VERSION ""

NS_ :

BS_:

BU_: APIM_CISM FCIMB RACM_RCIM DSP WCM DACMC HUD_ADV TRM_ITRM ACM GWM _delete APIM IPC GENERIC TSTR

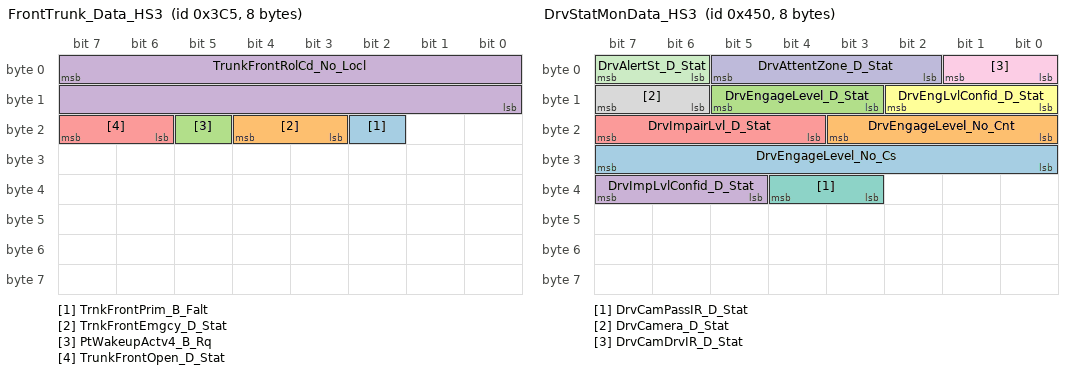
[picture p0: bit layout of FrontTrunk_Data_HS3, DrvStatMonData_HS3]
BO_ 965 FrontTrunk_Data_HS3: 8 GWM
 SG_ TrnkFrontPrim_B_Falt : 18|1@0+ (1,0) [0|1] "SED"  IPC
 SG_ TrnkFrontEmgcy_D_Stat : 20|2@0+ (1,0) [0|0] "SED"  IPC
 SG_ PtWakeupActv4_B_Rq : 21|1@0+ (1,0) [0|1] "SED"  GENERIC
 SG_ TrunkFrontRolCd_No_Locl : 7|16@0+ (1,0) [0|65535] "unitless"  GENERIC
 SG_ TrunkFrontOpen_D_Stat : 23|2@0+ (1,0) [0|3] "SED"  GENERIC

BO_ 1104 DrvStatMonData_HS3: 8 GWM
 SG_ DrvEngageLevel_No_Cs : 31|8@0+ (1,0) [0|255] "Unitless" Vector__XXX
 SG_ DrvEngageLevel_No_Cnt : 19|4@0+ (1,0) [0|15] "Unitless" Vector__XXX
 SG_ DrvEngageLevel_D_Stat : 13|3@0+ (1,0) [0|7] "SED" Vector__XXX
 SG_ DrvImpLvlConfid_D_Stat : 39|3@0+ (1,0) [0|7] "SED" Vector__XXX
 SG_ DrvImpairLvl_D_Stat : 23|4@0+ (1,0) [0|15] "SED" Vector__XXX
 SG_ DrvEngLvlConfid_D_Stat : 10|3@0+ (1,0) [0|7] "SED" Vector__XXX
 SG_ DrvCamPassIR_D_Stat : 36|2@0+ (1,0) [0|3] "SED"  APIM_CISM
 SG_ DrvCamera_D_Stat : 15|2@0+ (1,0) [0|3] "SED"  APIM_CISM
 SG_ DrvCamDrvIR_D_Stat : 1|2@0+ (1,0) [0|3] "SED"  APIM_CISM
 SG_ DrvAttentZone_D_Stat : 5|4@0+ (1,0) [0|15] "SED" Vector__XXX
 SG_ DrvAlertSt_D_Stat : 7|2@0+ (1,0) [0|3] "SED" Vector__XXX

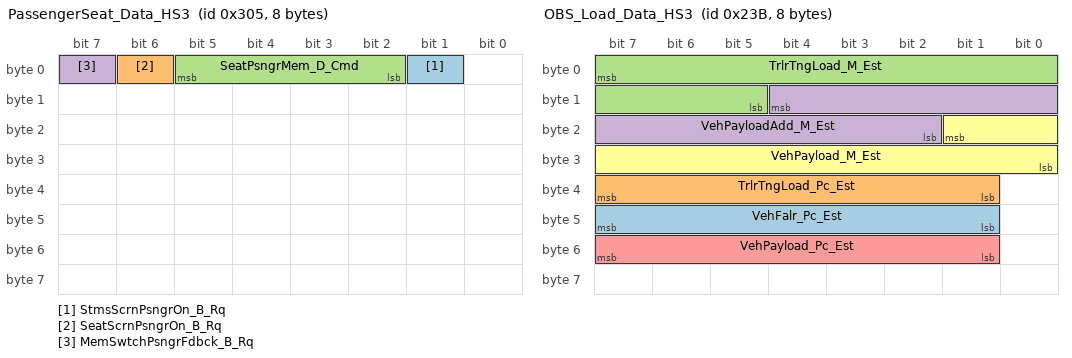
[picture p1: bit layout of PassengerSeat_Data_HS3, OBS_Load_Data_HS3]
BO_ 773 PassengerSeat_Data_HS3: 8 GWM
 SG_ StmsScrnPsngrOn_B_Rq : 1|1@0+ (1,0) [0|1] "SED"  APIM,APIM_CISM
 SG_ SeatScrnPsngrOn_B_Rq : 6|1@0+ (1,0) [0|1] "SED"  GENERIC
 SG_ SeatPsngrMem_D_Cmd : 5|4@0+ (1,0) [0|15] "SED"  GENERIC
 SG_ MemSwtchPsngrFdbck_B_Rq : 7|1@0+ (1,0) [0|1] "SED"  GENERIC

BO_ 303 Body_Info_16_HS3: 8 GWM
 SG_ CanMsg12F_No_Crc : 7|8@0+ (1,0) [0|255] "Unitless"  GENERIC
 SG_ CanMsg12F_No_Cnt : 11|4@0+ (1,0) [0|15] "Unitless"  GENERIC
 SG_ DrStatHood_D2_Actl : 23|3@0+ (1,0) [0|7] "SED"  IPC

BO_ 302 FrontTrunk_Data_2_HS3: 8 GWM
 SG_ CanMsg12E_No_Crc : 7|8@0+ (1,0) [0|255] "Unitless"  GENERIC
 SG_ CanMsg12E_No_Cnt : 11|4@0+ (1,0) [0|15] "Unitless"  GENERIC
 SG_ TrnkFrontRleas_B_Stat : 21|1@0+ (1,0) [0|1] "SED"  GENERIC

BO_ 2612009176 PARSEDPushFcGWM_ECGtoHUD: 8 GWM
 SG_ PARSEDPushFcGWM_ECGtoHUD : 7|29@0+ (1,0) [0|536870911] "unitless"  HUD_ADV

BO_ 571 OBS_Load_Data_HS3: 8 GWM
 SG_ VehFalr_Pc_Est : 47|7@0+ (1,0) [0|125] "percent"  APIM,APIM_CISM
 SG_ TrlrTngLoad_Pc_Est : 39|7@0+ (1,0) [0|125] "percent"  APIM,APIM_CISM
 SG_ TrlrTngLoad_M_Est : 7|11@0+ (10,-10240) [-10240|10210] "kilogram"  APIM,APIM_CISM
 SG_ VehPayloadAdd_M_Est : 12|11@0+ (5,-5115) [-5115|5110] "kilogram"  APIM,APIM_CISM
 SG_ VehPayload_Pc_Est : 55|7@0+ (1,0) [0|125] "percent"  APIM,APIM_CISM
 SG_ VehPayload_M_Est : 17|10@0+ (5,0) [0|5105] "kilogram"  APIM,APIM_CISM

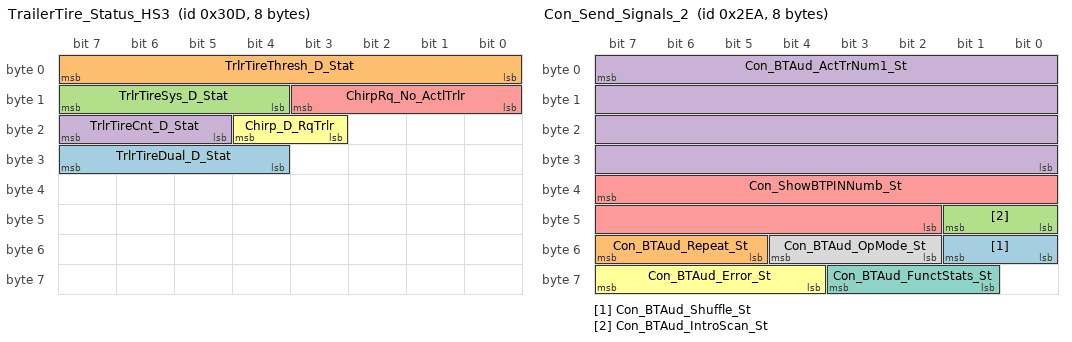
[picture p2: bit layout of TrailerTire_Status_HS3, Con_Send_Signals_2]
BO_ 781 TrailerTire_Status_HS3: 8 GWM
 SG_ TrlrTireDual_D_Stat : 31|4@0+ (1,0) [0|15] "SED"  APIM,IPC,APIM_CISM
 SG_ TrlrTireThresh_D_Stat : 7|8@0+ (1,0) [0|255] "unitless"  APIM,IPC,APIM_CISM
 SG_ TrlrTireSys_D_Stat : 15|4@0+ (1,0) [0|15] "SED"  APIM,IPC,APIM_CISM
 SG_ TrlrTireCnt_D_Stat : 23|3@0+ (1,0) [0|6] "SED"  APIM,IPC,APIM_CISM
 SG_ ChirpRq_No_ActlTrlr : 11|4@0+ (1,0) [0|15] "unitless"  GENERIC
 SG_ Chirp_D_RqTrlr : 20|2@0+ (1,0) [0|3] "SED"  GENERIC

BO_ 1188 OPTIN_MC_WORD_Rx: 8 IPC
 SG_ OPTIN_MC_WORD_Rx : 7|64@0+ (1,0) [0|1.84467440737096E+019] "unitless"  GWM

BO_ 746 Con_Send_Signals_2: 8 ACM
 SG_ Con_BTAud_Shuffle_St : 49|2@0+ (1,0) [0|3] "SED"  IPC
 SG_ Con_BTAud_Repeat_St : 55|3@0+ (1,0) [0|7] "SED"  IPC
 SG_ Con_BTAud_IntroScan_St : 41|2@0+ (1,0) [0|3] "SED"  IPC
 SG_ Con_BTAud_ActTrNum1_St : 7|32@0+ (1,0) [0|4294967295] ""  IPC
 SG_ Con_ShowBTPINNumb_St : 39|14@0+ (1,0) [0|16383] ""  IPC
 SG_ Con_BTAud_Error_St : 63|4@0+ (1,0) [0|15] "SED"  IPC
 SG_ Con_BTAud_FunctStats_St : 59|3@0+ (1,0) [0|7] "SED"  IPC
 SG_ Con_BTAud_OpMode_St : 52|3@0+ (1,0) [0|7] "SED"  IPC

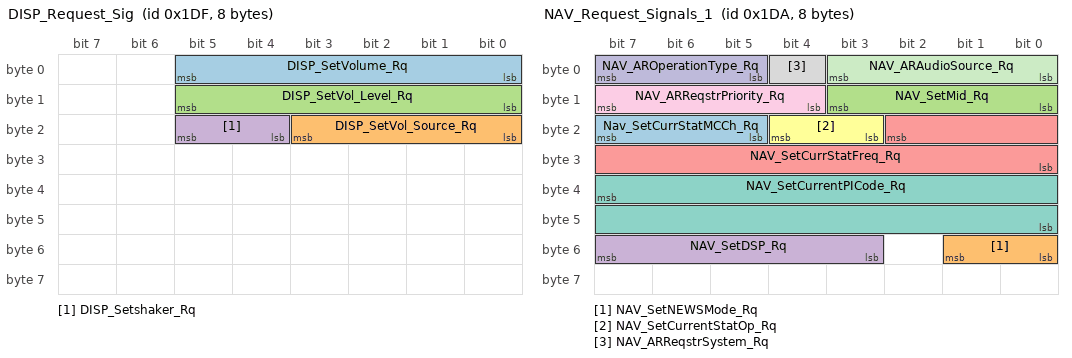
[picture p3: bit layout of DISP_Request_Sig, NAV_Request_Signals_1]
BO_ 479 DISP_Request_Sig: 8 APIM
 SG_ DISP_SetVolume_Rq : 5|6@0+ (1,-30) [-30|33] "steps"  ACM,DSP,GWM
 SG_ DISP_SetVol_Source_Rq : 19|4@0+ (1,0) [0|15] "SED"  IPC,ACM,DSP
 SG_ DISP_SetVol_Level_Rq : 13|6@0+ (1,0) [0|63] "unitless"  ACM,DSP
 SG_ DISP_Setshaker_Rq : 21|2@0+ (1,0) [0|3] "SED"  ACM,DSP

BO_ 474 NAV_Request_Signals_1: 8 APIM
 SG_ Nav_SetCurrStatMCCh_Rq : 23|3@0+ (1,0) [0|7] "SED"  ACM
 SG_ NAV_SetNEWSMode_Rq : 49|2@0+ (1,0) [0|3] "SED"  ACM
 SG_ NAV_SetMid_Rq : 11|4@0+ (1,-7) [-7|8] "SED"  DSP,ACM
 SG_ NAV_SetDSP_Rq : 55|5@0+ (1,0) [0|31] "SED"  ACM
 SG_ NAV_SetCurrStatFreq_Rq : 18|11@0+ (1,0) [0|1557] "unitless"  ACM
 SG_ NAV_SetCurrentStatOp_Rq : 20|2@0+ (1,0) [0|3] "SED"  ACM
 SG_ NAV_SetCurrentPICode_Rq : 39|16@0+ (1,0) [0|65535] "unitless"  ACM
 SG_ NAV_ARReqstrSystem_Rq : 4|1@0+ (1,0) [0|1] "SED"  DSP,ACM
 SG_ NAV_ARReqstrPriority_Rq : 15|4@0+ (1,0) [0|15] "SED"  DSP,ACM
 SG_ NAV_AROperationType_Rq : 7|3@0+ (1,0) [0|7] "SED"  DSP,ACM
 SG_ NAV_ARAudioSource_Rq : 3|4@0+ (1,0) [0|15] "SED"  DSP,ACM

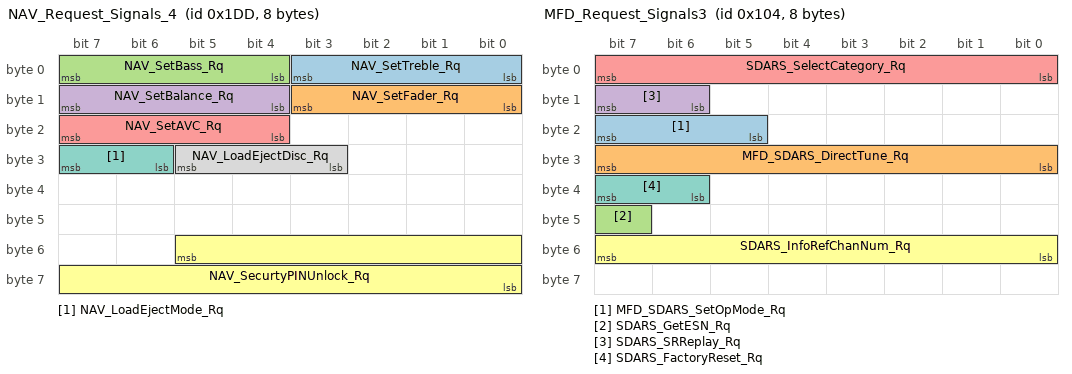
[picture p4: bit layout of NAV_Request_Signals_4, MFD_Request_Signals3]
BO_ 477 NAV_Request_Signals_4: 8 APIM
 SG_ NAV_SetTreble_Rq : 3|4@0+ (1,-7) [-7|8] "SED"  ACM,DSP
 SG_ NAV_SetFader_Rq : 11|4@0+ (1,-7) [-7|8] "SED"  ACM,DSP
 SG_ NAV_SetBass_Rq : 7|4@0+ (1,-7) [-7|8] "SED"  ACM,DSP
 SG_ NAV_SetBalance_Rq : 15|4@0+ (1,-7) [-7|8] "SED"  ACM,DSP
 SG_ NAV_SetAVC_Rq : 23|4@0+ (1,0) [0|15] "SED"  ACM,DSP
 SG_ NAV_SecurtyPINUnlock_Rq : 53|14@0+ (1,0) [0|16383] "unitless"  ACM
 SG_ NAV_LoadEjectMode_Rq : 31|2@0+ (1,0) [0|3] "SED"  ACM
 SG_ NAV_LoadEjectDisc_Rq : 29|3@0+ (1,0) [0|7] "SED"  ACM

BO_ 260 MFD_Request_Signals3: 8 APIM
 SG_ MFD_SDARS_SetOpMode_Rq : 23|3@0+ (1,0) [0|7] "SED"  ACM
 SG_ MFD_SDARS_DirectTune_Rq : 31|8@0+ (1,0) [0|255] "unitless"  ACM
 SG_ SDARS_GetESN_Rq : 47|1@0+ (1,0) [0|1] "SED"  ACM
 SG_ SDARS_SRReplay_Rq : 15|2@0+ (1,0) [0|3] "SED"  ACM
 SG_ SDARS_SelectCategory_Rq : 7|8@0+ (1,0) [0|255] "unitless"  ACM
 SG_ SDARS_InfoRefChanNum_Rq : 55|8@0+ (1,0) [0|255] "unitless"  ACM
 SG_ SDARS_FactoryReset_Rq : 39|2@0+ (1,0) [0|3] "SED"  DSP,ACM

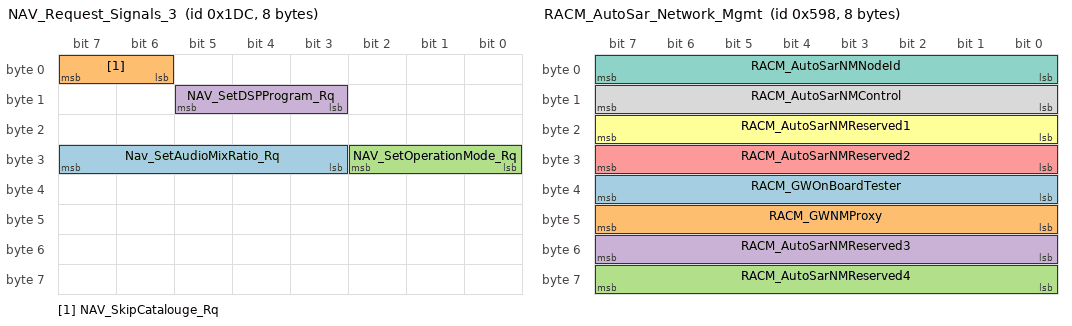
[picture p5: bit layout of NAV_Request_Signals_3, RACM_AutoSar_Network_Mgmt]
BO_ 476 NAV_Request_Signals_3: 8 APIM
 SG_ Nav_SetAudioMixRatio_Rq : 31|5@0+ (1,0) [0|20] "decibel"  ACM
 SG_ NAV_SkipCatalouge_Rq : 7|2@0+ (1,0) [0|3] "SED"  ACM
 SG_ NAV_SetOperationMode_Rq : 26|3@0+ (1,0) [0|7] "SED"  ACM
 SG_ NAV_SetDSPProgram_Rq : 13|3@0+ (1,0) [0|7] "SED"  ACM

BO_ 490 HMI_Request_Signals_2: 8 APIM
 SG_ HMI_SetCompression_Rq : 9|2@0+ (1,0) [0|3] "SED"  ACM
 SG_ HMI_SkipTrack_Rq : 35|2@0+ (1,0) [0|3] "SED"  ACM

BO_ 1001 Personality_SUMA_Data_HS3: 8 GWM
 SG_ AirSuspMsgTxt_D_Rq2 : 36|2@0+ (1,0) [0|3] "SED"  APIM_CISM,APIM,IPC
 SG_ PersIndexSuma_D_Actl : 39|3@0+ (1,0) [0|7] "SED"  APIM_CISM,APIM,IPC
 SG_ FeatNoSumaActl : 23|16@0+ (1,0) [0|65535] "Number"  APIM_CISM,APIM,IPC
 SG_ FeatConfigSumaActl : 7|16@0+ (1,0) [0|65535] "Undefined"  APIM_CISM,APIM,IPC

BO_ 1916 TesterPhysicalResRACM: 8 RACM_RCIM
 SG_ TesterPhysicalResRACM : 7|64@0+ (1,0) [0|1.84467E+019] "unitless"  TSTR

BO_ 1908 TesterPhysicalReqRACM: 8 TSTR
 SG_ TesterPhysicalReqRACM : 7|64@0+ (1,0) [0|1.84467E+019] "unitless"  RACM_RCIM

BO_ 1432 RACM_AutoSar_Network_Mgmt: 8 RACM_RCIM
 SG_ RACM_GWOnBoardTester : 39|8@0+ (1,0) [0|255] "unitless"  HUD_ADV,GWM
 SG_ RACM_GWNMProxy : 47|8@0+ (1,0) [0|255] "unitless"  HUD_ADV,GWM
 SG_ RACM_AutoSarNMReserved4 : 63|8@0+ (1,0) [0|255] "unitless"  HUD_ADV,GWM
 SG_ RACM_AutoSarNMReserved3 : 55|8@0+ (1,0) [0|255] "unitless"  HUD_ADV,GWM
 SG_ RACM_AutoSarNMReserved2 : 31|8@0+ (1,0) [0|255] "unitless"  HUD_ADV,GWM
 SG_ RACM_AutoSarNMReserved1 : 23|8@0+ (1,0) [0|255] "unitless"  HUD_ADV,GWM
 SG_ RACM_AutoSarNMNodeId : 7|8@0+ (1,0) [0|255] "unitless"  HUD_ADV,GWM
 SG_ RACM_AutoSarNMControl : 15|8@0+ (1,0) [0|255] "unitless"  HUD_ADV,GWM

BO_ 1923 TesterPhysicalReqDSP: 8 TSTR
 SG_ TesterPhysicalReqDSP : 7|64@0+ (1,0) [0|1.84467E+019] "unitless"  DSP

BO_ 1931 TesterPhysicalResDSP: 8 DSP
 SG_ TesterPhysicalResDSP : 7|64@0+ (1,0) [0|1.84467E+019] "unitless"  TSTR

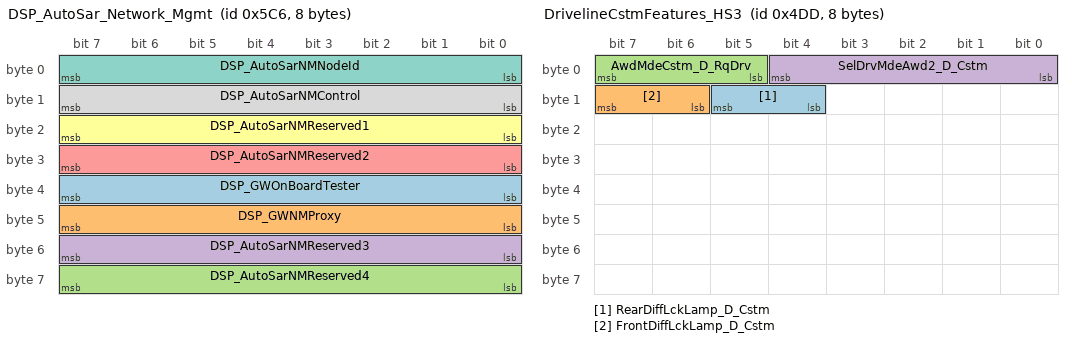
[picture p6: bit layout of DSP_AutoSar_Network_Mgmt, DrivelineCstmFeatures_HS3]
BO_ 1478 DSP_AutoSar_Network_Mgmt: 8 DSP
 SG_ DSP_GWOnBoardTester : 39|8@0+ (1,0) [0|255] "unitless"  HUD_ADV
 SG_ DSP_GWNMProxy : 47|8@0+ (1,0) [0|255] "unitless"  HUD_ADV
 SG_ DSP_AutoSarNMReserved4 : 63|8@0+ (1,0) [0|255] "unitless"  HUD_ADV
 SG_ DSP_AutoSarNMReserved3 : 55|8@0+ (1,0) [0|255] "unitless"  HUD_ADV
 SG_ DSP_AutoSarNMReserved2 : 31|8@0+ (1,0) [0|255] "unitless"  HUD_ADV
 SG_ DSP_AutoSarNMReserved1 : 23|8@0+ (1,0) [0|255] "unitless"  HUD_ADV
 SG_ DSP_AutoSarNMNodeId : 7|8@0+ (1,0) [0|255] "unitless"  HUD_ADV
 SG_ DSP_AutoSarNMControl : 15|8@0+ (1,0) [0|255] "unitless"  HUD_ADV

BO_ 1245 DrivelineCstmFeatures_HS3: 8 GWM
 SG_ RearDiffLckLamp_D_Cstm : 13|2@0+ (1,0) [0|3] "SED"  IPC
 SG_ FrontDiffLckLamp_D_Cstm : 15|2@0+ (1,0) [0|3] "SED"  IPC
 SG_ AwdMdeCstm_D_RqDrv : 7|3@0+ (1,0) [0|7] "SED"  IPC
 SG_ SelDrvMdeAwd2_D_Cstm : 4|5@0+ (1,0) [0|31] "SED"  GENERIC

BO_ 1242 PowertrainCstmData_HS3: 8 GWM
 SG_ EngExhMdeQuietCstm_D_Rq : 7|3@0+ (1,0) [0|7] "SED"  IPC
 SG_ StopStrtCstm_D_Rq : 15|2@0+ (1,0) [0|3] "SED"  IPC
 SG_ SelDrvMdeCstmPt_D_Rq : 4|5@0+ (1,0) [0|31] "SED"  GENERIC

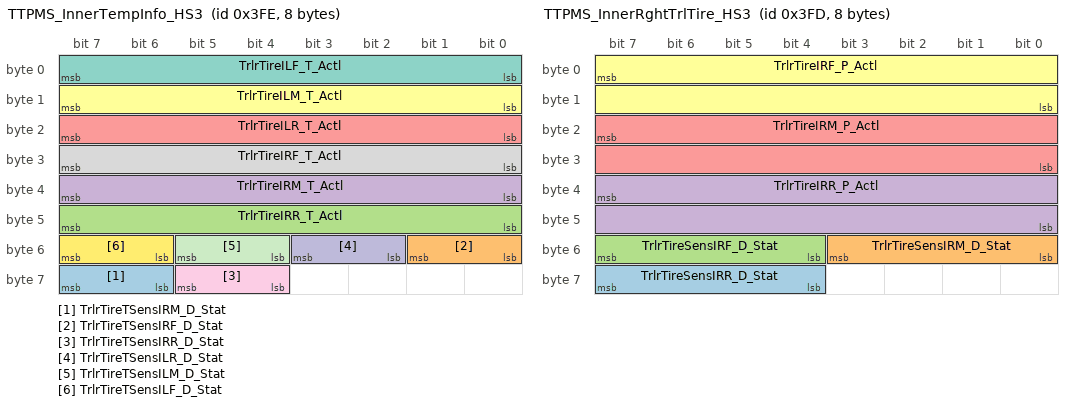
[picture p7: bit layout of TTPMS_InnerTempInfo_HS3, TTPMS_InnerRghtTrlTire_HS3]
BO_ 1022 TTPMS_InnerTempInfo_HS3: 8 GWM
 SG_ TrlrTireTSensIRM_D_Stat : 63|2@0+ (1,0) [0|3] "SED"  APIM,IPC,APIM_CISM
 SG_ TrlrTireTSensIRF_D_Stat : 49|2@0+ (1,0) [0|3] "SED"  APIM,IPC,APIM_CISM
 SG_ TrlrTireIRR_T_Actl : 47|8@0+ (1,-60) [-60|193] "degC"  APIM,IPC,APIM_CISM
 SG_ TrlrTireIRM_T_Actl : 39|8@0+ (1,-60) [-60|193] "degC"  APIM,IPC,APIM_CISM
 SG_ TrlrTireILR_T_Actl : 23|8@0+ (1,-60) [-60|193] "degC"  APIM,IPC,APIM_CISM
 SG_ TrlrTireILM_T_Actl : 15|8@0+ (1,-60) [-60|193] "degC"  APIM,IPC,APIM_CISM
 SG_ TrlrTireILF_T_Actl : 7|8@0+ (1,-60) [-60|193] "degC"  APIM,IPC,APIM_CISM
 SG_ TrlrTireIRF_T_Actl : 31|8@0+ (1,-60) [-60|193] "degC"  APIM,IPC,APIM_CISM
 SG_ TrlrTireTSensIRR_D_Stat : 61|2@0+ (1,0) [0|3] "SED"  APIM,IPC,APIM_CISM
 SG_ TrlrTireTSensILR_D_Stat : 51|2@0+ (1,0) [0|3] "SED"  APIM,IPC,APIM_CISM
 SG_ TrlrTireTSensILM_D_Stat : 53|2@0+ (1,0) [0|3] "SED"  APIM,IPC,APIM_CISM
 SG_ TrlrTireTSensILF_D_Stat : 55|2@0+ (1,0) [0|3] "SED"  APIM,IPC,APIM_CISM

BO_ 1021 TTPMS_InnerRghtTrlTire_HS3: 8 GWM
 SG_ TrlrTireSensIRR_D_Stat : 63|4@0+ (1,0) [0|15] "SED"  APIM,IPC,APIM_CISM
 SG_ TrlrTireSensIRM_D_Stat : 51|4@0+ (1,0) [0|15] "SED"  APIM,IPC,APIM_CISM
 SG_ TrlrTireSensIRF_D_Stat : 55|4@0+ (1,0) [0|15] "SED"  APIM_CISM
 SG_ TrlrTireIRR_P_Actl : 39|16@0+ (1,0) [0|65533] "kilopascal"  APIM,IPC,APIM_CISM
 SG_ TrlrTireIRM_P_Actl : 23|16@0+ (1,0) [0|65533] "kilopascal"  APIM,IPC,APIM_CISM
 SG_ TrlrTireIRF_P_Actl : 7|16@0+ (1,0) [0|65533] "kilopascal"  APIM,IPC,APIM_CISM

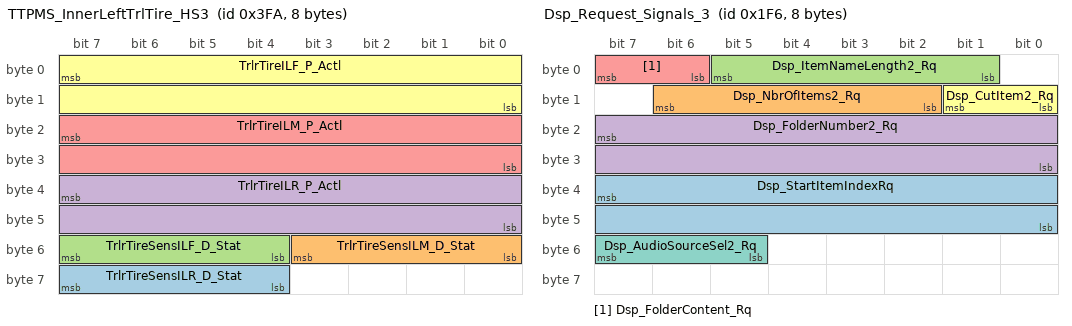
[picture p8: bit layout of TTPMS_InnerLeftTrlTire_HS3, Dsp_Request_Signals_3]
BO_ 1018 TTPMS_InnerLeftTrlTire_HS3: 8 GWM
 SG_ TrlrTireSensILR_D_Stat : 63|4@0+ (1,0) [0|15] "SED"  APIM_CISM,APIM,IPC
 SG_ TrlrTireSensILM_D_Stat : 51|4@0+ (1,0) [0|15] "SED"  APIM,IPC,APIM_CISM
 SG_ TrlrTireSensILF_D_Stat : 55|4@0+ (1,0) [0|15] "SED"  APIM,IPC,APIM_CISM
 SG_ TrlrTireILR_P_Actl : 39|16@0+ (1,0) [0|65533] "kilopascal"  APIM,IPC,APIM_CISM
 SG_ TrlrTireILM_P_Actl : 23|16@0+ (1,0) [0|65533] "kilopascal"  APIM,IPC,APIM_CISM
 SG_ TrlrTireILF_P_Actl : 7|16@0+ (1,0) [0|65533] "kilopascal"  APIM,IPC,APIM_CISM

BO_ 502 Dsp_Request_Signals_3: 8 APIM
 SG_ Dsp_StartItemIndexRq : 39|16@0+ (1,0) [0|65535] "unitless"  ACM
 SG_ Dsp_NbrOfItems2_Rq : 14|5@0+ (1,0) [0|20] "SED"  ACM
 SG_ Dsp_ItemNameLength2_Rq : 5|5@0+ (1,0) [0|20] "SED"  ACM
 SG_ Dsp_FolderNumber2_Rq : 23|16@0+ (1,0) [0|65535] "unitless"  ACM
 SG_ Dsp_FolderContent_Rq : 7|2@0+ (1,0) [0|3] "SED"  ACM
 SG_ Dsp_CutItem2_Rq : 9|2@0+ (1,0) [0|3] "SED"  ACM
 SG_ Dsp_AudioSourceSel2_Rq : 55|3@0+ (1,0) [0|7] "SED"  ACM

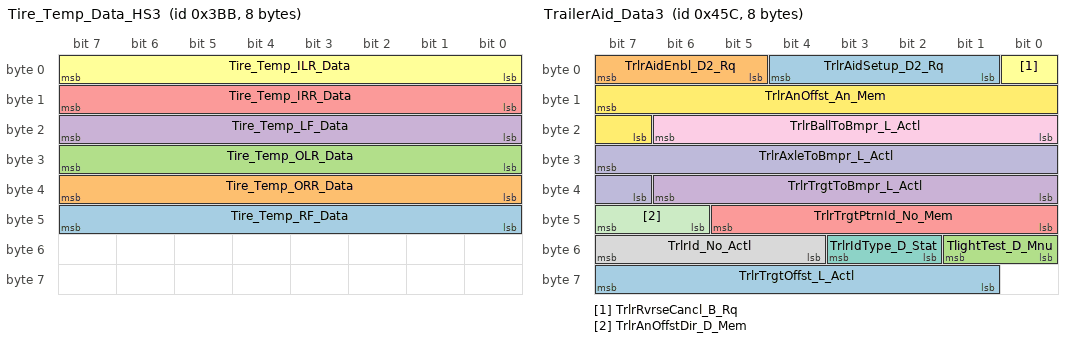
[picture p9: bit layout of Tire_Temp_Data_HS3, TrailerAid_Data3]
BO_ 955 Tire_Temp_Data_HS3: 8 GWM
 SG_ Tire_Temp_RF_Data : 47|8@0+ (1,-60) [-60|193] "degC"  IPC,APIM,APIM_CISM
 SG_ Tire_Temp_ORR_Data : 39|8@0+ (1,-60) [-60|193] "degC"  IPC,APIM,APIM_CISM
 SG_ Tire_Temp_OLR_Data : 31|8@0+ (1,-60) [-60|193] "degC"  IPC,APIM,APIM_CISM
 SG_ Tire_Temp_LF_Data : 23|8@0+ (1,-60) [-60|193] "degC"  IPC,APIM,APIM_CISM
 SG_ Tire_Temp_IRR_Data : 15|8@0+ (1,-60) [-60|193] "degC"  IPC,APIM,APIM_CISM
 SG_ Tire_Temp_ILR_Data : 7|8@0+ (1,-60) [-60|193] "degC"  IPC,APIM,APIM_CISM

BO_ 1116 TrailerAid_Data3: 8 APIM
 SG_ TrlrAidSetup_D2_Rq : 4|4@0+ (1,0) [0|15] "SED"  GWM
 SG_ TrlrAidEnbl_D2_Rq : 7|3@0+ (1,0) [0|7] "SED"  GWM
 SG_ TlightTest_D_Mnu : 49|2@0+ (1,0) [0|3] "SED"  GWM
 SG_ TrlrTrgtToBmpr_L_Actl : 38|7@0+ (0.0127,0) [0|1.6129] "meter"  GWM
 SG_ TrlrTrgtPtrnId_No_Mem : 45|6@0+ (1,0) [0|63] "unitless"  GWM
 SG_ TrlrRvrseCancl_B_Rq : 0|1@0+ (1,0) [0|1] "SED"  GWM
 SG_ TrlrIdType_D_Stat : 51|2@0+ (1,0) [0|3] "SED"  GWM
 SG_ TrlrId_No_Actl : 55|4@0+ (1,0) [0|15] "unitless"  GWM
 SG_ TrlrBallToBmpr_L_Actl : 22|7@0+ (0.0127,0) [0|1.6129] "meter"  GWM
 SG_ TrlrAxleToBmpr_L_Actl : 31|9@0+ (0.0254,0) [0|12.9794] "meter"  GWM
 SG_ TrlrAnOffstDir_D_Mem : 47|2@0+ (1,0) [0|3] "SED"  GWM
 SG_ TrlrAnOffst_An_Mem : 15|9@0+ (0.1,0) [0|51.1] "degrees"  GWM
 SG_ TrlrTrgtOffst_L_Actl : 63|7@0+ (0.0127,0) [0|1.6129] "meter"  GWM

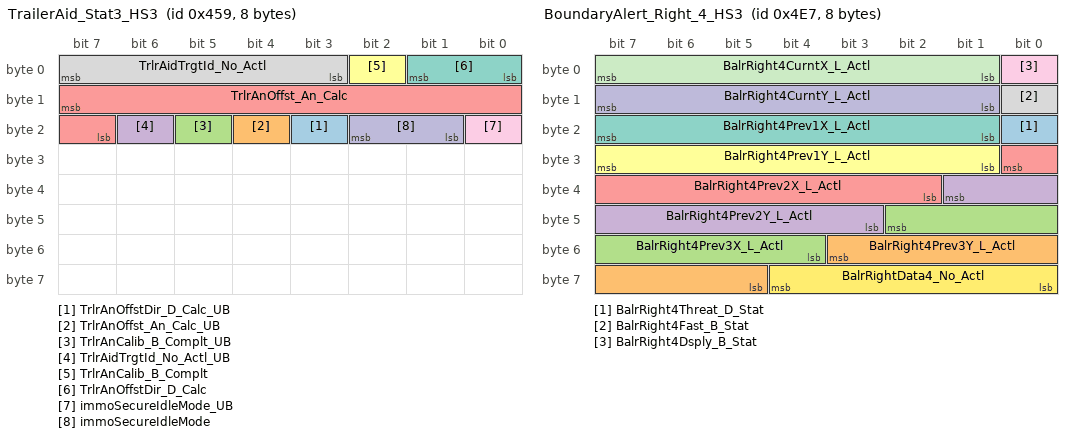
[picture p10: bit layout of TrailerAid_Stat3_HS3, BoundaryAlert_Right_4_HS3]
BO_ 1113 TrailerAid_Stat3_HS3: 8 GWM
 SG_ TrlrAnOffstDir_D_Calc_UB : 19|1@0+ (1,0) [0|1] "SED"  APIM_CISM,IPC,APIM
 SG_ TrlrAnOffst_An_Calc_UB : 20|1@0+ (1,0) [0|1] "SED"  APIM_CISM,IPC,APIM
 SG_ TrlrAnCalib_B_Complt_UB : 21|1@0+ (1,0) [0|1] "SED"  APIM_CISM,IPC,APIM
 SG_ TrlrAidTrgtId_No_Actl_UB : 22|1@0+ (1,0) [0|1] "SED"  APIM_CISM,IPC,APIM
 SG_ TrlrAnOffst_An_Calc : 15|9@0+ (0.1,0) [0|51.1] "degrees"  APIM_CISM,IPC,APIM
 SG_ TrlrAnCalib_B_Complt : 2|1@0+ (1,0) [0|1] "SED"  APIM_CISM,IPC,APIM
 SG_ TrlrAnOffstDir_D_Calc : 1|2@0+ (1,0) [0|3] "SED"  APIM_CISM,IPC,APIM
 SG_ TrlrAidTrgtId_No_Actl : 7|5@0+ (1,0) [0|31] "unitless"  APIM_CISM,IPC,APIM
 SG_ immoSecureIdleMode_UB : 16|1@0+ (1,0) [0|1] "SED"  APIM_CISM,APIM
 SG_ immoSecureIdleMode : 18|2@0+ (1,0) [0|3] "SED"  APIM_CISM,APIM

BO_ 1255 BoundaryAlert_Right_4_HS3: 8 GWM
 SG_ BalrRight4Threat_D_Stat : 16|1@0+ (1,0) [0|1] "SED"  IPC
 SG_ BalrRight4Prev3Y_L_Actl : 51|7@0+ (0.5,-32) [-32|31.5] "meter"  IPC
 SG_ BalrRight4Prev3X_L_Actl : 42|7@0+ (0.5,-32) [-32|31.5] "meter"  IPC
 SG_ BalrRight4Prev2Y_L_Actl : 33|7@0+ (0.5,-32) [-32|31.5] "meter"  IPC
 SG_ BalrRight4Prev2X_L_Actl : 24|7@0+ (0.5,-32) [-32|31.5] "meter"  IPC
 SG_ BalrRight4Prev1Y_L_Actl : 31|7@0+ (0.5,-32) [-32|31.5] "meter"  IPC
 SG_ BalrRight4Prev1X_L_Actl : 23|7@0+ (0.5,-32) [-32|31.5] "meter"  IPC
 SG_ BalrRight4Fast_B_Stat : 8|1@0+ (1,0) [0|1] "SED"  IPC
 SG_ BalrRight4Dsply_B_Stat : 0|1@0+ (1,0) [0|1] "SED"  IPC
 SG_ BalrRight4CurntY_L_Actl : 15|7@0+ (0.5,-32) [-32|31.5] "meter"  IPC
 SG_ BalrRight4CurntX_L_Actl : 7|7@0+ (0.5,-32) [-32|31.5] "meter"  IPC
 SG_ BalrRightData4_No_Actl : 60|5@0+ (1,0) [0|31] "unitless" Vector__XXX

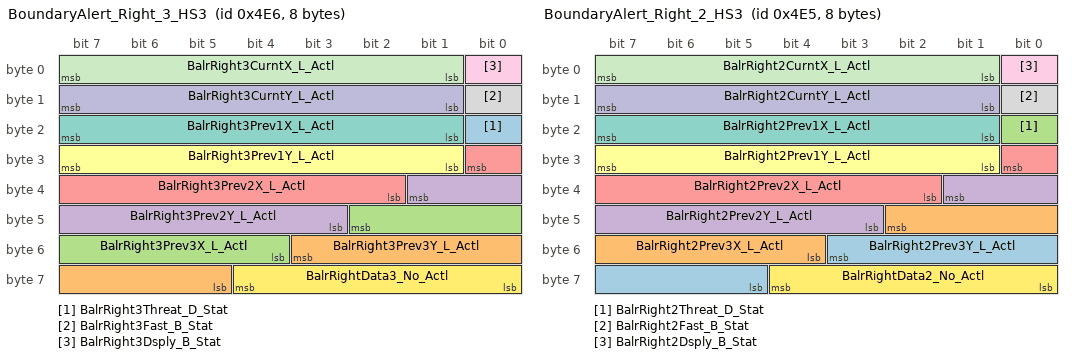
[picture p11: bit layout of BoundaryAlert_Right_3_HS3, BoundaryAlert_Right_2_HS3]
BO_ 1254 BoundaryAlert_Right_3_HS3: 8 GWM
 SG_ BalrRight3Threat_D_Stat : 16|1@0+ (1,0) [0|1] "SED"  IPC
 SG_ BalrRight3Prev3Y_L_Actl : 51|7@0+ (0.5,-32) [-32|31.5] "meter"  IPC
 SG_ BalrRight3Prev3X_L_Actl : 42|7@0+ (0.5,-32) [-32|31.5] "meter"  IPC
 SG_ BalrRight3Prev2Y_L_Actl : 33|7@0+ (0.5,-32) [-32|31.5] "meter"  IPC
 SG_ BalrRight3Prev2X_L_Actl : 24|7@0+ (0.5,-32) [-32|31.5] "meter"  IPC
 SG_ BalrRight3Prev1Y_L_Actl : 31|7@0+ (0.5,-32) [-32|31.5] "meter"  IPC
 SG_ BalrRight3Prev1X_L_Actl : 23|7@0+ (0.5,-32) [-32|31.5] "meter"  IPC
 SG_ BalrRight3Fast_B_Stat : 8|1@0+ (1,0) [0|1] "SED"  IPC
 SG_ BalrRight3Dsply_B_Stat : 0|1@0+ (1,0) [0|1] "SED"  IPC
 SG_ BalrRight3CurntY_L_Actl : 15|7@0+ (0.5,-32) [-32|31.5] "meter"  IPC
 SG_ BalrRight3CurntX_L_Actl : 7|7@0+ (0.5,-32) [-32|31.5] "meter"  IPC
 SG_ BalrRightData3_No_Actl : 60|5@0+ (1,0) [0|31] "unitless" Vector__XXX

BO_ 1253 BoundaryAlert_Right_2_HS3: 8 GWM
 SG_ BalrRight2Prev3Y_L_Actl : 51|7@0+ (0.5,-32) [-32|31.5] "meter"  IPC
 SG_ BalrRight2Prev3X_L_Actl : 42|7@0+ (0.5,-32) [-32|31.5] "meter"  IPC
 SG_ BalrRight2Threat_D_Stat : 16|1@0+ (1,0) [0|1] "SED"  IPC
 SG_ BalrRight2Prev2Y_L_Actl : 33|7@0+ (0.5,-32) [-32|31.5] "meter"  IPC
 SG_ BalrRight2Prev2X_L_Actl : 24|7@0+ (0.5,-32) [-32|31.5] "meter"  IPC
 SG_ BalrRight2Prev1Y_L_Actl : 31|7@0+ (0.5,-32) [-32|31.5] "meter"  IPC
 SG_ BalrRight2Prev1X_L_Actl : 23|7@0+ (0.5,-32) [-32|31.5] "meter"  IPC
 SG_ BalrRight2Fast_B_Stat : 8|1@0+ (1,0) [0|1] "SED"  IPC
 SG_ BalrRight2Dsply_B_Stat : 0|1@0+ (1,0) [0|1] "SED"  IPC
 SG_ BalrRight2CurntY_L_Actl : 15|7@0+ (0.5,-32) [-32|31.5] "meter"  IPC
 SG_ BalrRight2CurntX_L_Actl : 7|7@0+ (0.5,-32) [-32|31.5] "meter"  IPC
 SG_ BalrRightData2_No_Actl : 60|5@0+ (1,0) [0|31] "unitless" Vector__XXX

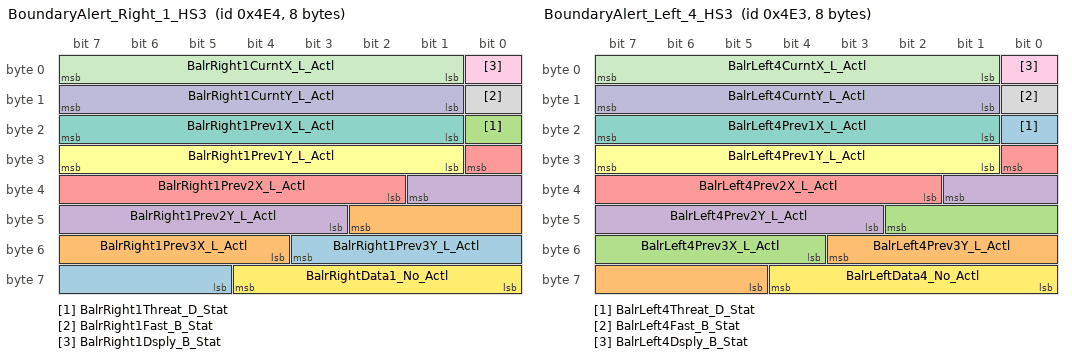
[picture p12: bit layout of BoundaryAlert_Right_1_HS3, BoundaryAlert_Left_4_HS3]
BO_ 1252 BoundaryAlert_Right_1_HS3: 8 GWM
 SG_ BalrRight1Prev3Y_L_Actl : 51|7@0+ (0.5,-32) [-32|31.5] "meter"  IPC
 SG_ BalrRight1Prev3X_L_Actl : 42|7@0+ (0.5,-32) [-32|31.5] "meter"  IPC
 SG_ BalrRight1Threat_D_Stat : 16|1@0+ (1,0) [0|1] "SED"  IPC
 SG_ BalrRight1Prev2Y_L_Actl : 33|7@0+ (0.5,-32) [-32|31.5] "meter"  IPC
 SG_ BalrRight1Prev2X_L_Actl : 24|7@0+ (0.5,-32) [-32|31.5] "meter"  IPC
 SG_ BalrRight1Prev1Y_L_Actl : 31|7@0+ (0.5,-32) [-32|31.5] "meter"  IPC
 SG_ BalrRight1Prev1X_L_Actl : 23|7@0+ (0.5,-32) [-32|31.5] "meter"  IPC
 SG_ BalrRight1Fast_B_Stat : 8|1@0+ (1,0) [0|1] "SED"  IPC
 SG_ BalrRight1Dsply_B_Stat : 0|1@0+ (1,0) [0|1] "SED"  IPC
 SG_ BalrRight1CurntY_L_Actl : 15|7@0+ (0.5,-32) [-32|31.5] "meter"  IPC
 SG_ BalrRight1CurntX_L_Actl : 7|7@0+ (0.5,-32) [-32|31.5] "meter"  IPC
 SG_ BalrRightData1_No_Actl : 60|5@0+ (1,0) [0|31] "unitless" Vector__XXX

BO_ 1251 BoundaryAlert_Left_4_HS3: 8 GWM
 SG_ BalrLeft4Threat_D_Stat : 16|1@0+ (1,0) [0|1] "SED"  IPC
 SG_ BalrLeft4Prev3Y_L_Actl : 51|7@0+ (0.5,-32) [-32|31.5] "meter"  IPC
 SG_ BalrLeft4Prev3X_L_Actl : 42|7@0+ (0.5,-32) [-32|31.5] "meter"  IPC
 SG_ BalrLeft4Prev2Y_L_Actl : 33|7@0+ (0.5,-32) [-32|31.5] "meter"  IPC
 SG_ BalrLeft4Prev2X_L_Actl : 24|7@0+ (0.5,-32) [-32|31.5] "meter"  IPC
 SG_ BalrLeft4Prev1Y_L_Actl : 31|7@0+ (0.5,-32) [-32|31.5] "meter"  IPC
 SG_ BalrLeft4Prev1X_L_Actl : 23|7@0+ (0.5,-32) [-32|31.5] "meter"  IPC
 SG_ BalrLeft4Fast_B_Stat : 8|1@0+ (1,0) [0|1] "SED"  IPC
 SG_ BalrLeft4Dsply_B_Stat : 0|1@0+ (1,0) [0|1] "SED"  IPC
 SG_ BalrLeft4CurntY_L_Actl : 15|7@0+ (0.5,-32) [-32|31.5] "meter"  IPC
 SG_ BalrLeft4CurntX_L_Actl : 7|7@0+ (0.5,-32) [-32|31.5] "meter"  IPC
 SG_ BalrLeftData4_No_Actl : 60|5@0+ (1,0) [0|31] "unitless" Vector__XXX

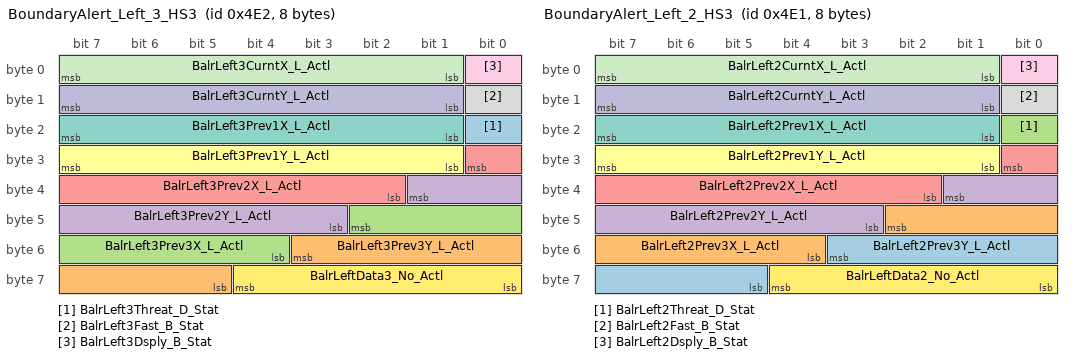
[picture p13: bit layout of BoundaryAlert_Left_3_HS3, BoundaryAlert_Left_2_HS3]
BO_ 1250 BoundaryAlert_Left_3_HS3: 8 GWM
 SG_ BalrLeft3Threat_D_Stat : 16|1@0+ (1,0) [0|1] "SED"  IPC
 SG_ BalrLeft3Prev3Y_L_Actl : 51|7@0+ (0.5,-32) [-32|31.5] "meter"  IPC
 SG_ BalrLeft3Prev3X_L_Actl : 42|7@0+ (0.5,-32) [-32|31.5] "meter"  IPC
 SG_ BalrLeft3Prev2Y_L_Actl : 33|7@0+ (0.5,-32) [-32|31.5] "meter"  IPC
 SG_ BalrLeft3Prev2X_L_Actl : 24|7@0+ (0.5,-32) [-32|31.5] "meter"  IPC
 SG_ BalrLeft3Prev1Y_L_Actl : 31|7@0+ (0.5,-32) [-32|31.5] "meter"  IPC
 SG_ BalrLeft3Prev1X_L_Actl : 23|7@0+ (0.5,-32) [-32|31.5] "meter"  IPC
 SG_ BalrLeft3Fast_B_Stat : 8|1@0+ (1,0) [0|1] "SED"  IPC
 SG_ BalrLeft3Dsply_B_Stat : 0|1@0+ (1,0) [0|1] "SED"  IPC
 SG_ BalrLeft3CurntY_L_Actl : 15|7@0+ (0.5,-32) [-32|31.5] "meter"  IPC
 SG_ BalrLeft3CurntX_L_Actl : 7|7@0+ (0.5,-32) [-32|31.5] "meter"  IPC
 SG_ BalrLeftData3_No_Actl : 60|5@0+ (1,0) [0|31] "unitless" Vector__XXX

BO_ 1249 BoundaryAlert_Left_2_HS3: 8 GWM
 SG_ BalrLeft2Prev3Y_L_Actl : 51|7@0+ (0.5,-32) [-32|31.5] "meter"  IPC
 SG_ BalrLeft2Prev3X_L_Actl : 42|7@0+ (0.5,-32) [-32|31.5] "meter"  IPC
 SG_ BalrLeft2Threat_D_Stat : 16|1@0+ (1,0) [0|1] "SED"  IPC
 SG_ BalrLeft2Prev2Y_L_Actl : 33|7@0+ (0.5,-32) [-32|31.5] "meter"  IPC
 SG_ BalrLeft2Prev2X_L_Actl : 24|7@0+ (0.5,-32) [-32|31.5] "meter"  IPC
 SG_ BalrLeft2Prev1Y_L_Actl : 31|7@0+ (0.5,-32) [-32|31.5] "meter"  IPC
 SG_ BalrLeft2Prev1X_L_Actl : 23|7@0+ (0.5,-32) [-32|31.5] "meter"  IPC
 SG_ BalrLeft2Fast_B_Stat : 8|1@0+ (1,0) [0|1] "SED"  IPC
 SG_ BalrLeft2Dsply_B_Stat : 0|1@0+ (1,0) [0|1] "SED"  IPC
 SG_ BalrLeft2CurntY_L_Actl : 15|7@0+ (0.5,-32) [-32|31.5] "meter"  IPC
 SG_ BalrLeft2CurntX_L_Actl : 7|7@0+ (0.5,-32) [-32|31.5] "meter"  IPC
 SG_ BalrLeftData2_No_Actl : 60|5@0+ (1,0) [0|31] "unitless" Vector__XXX

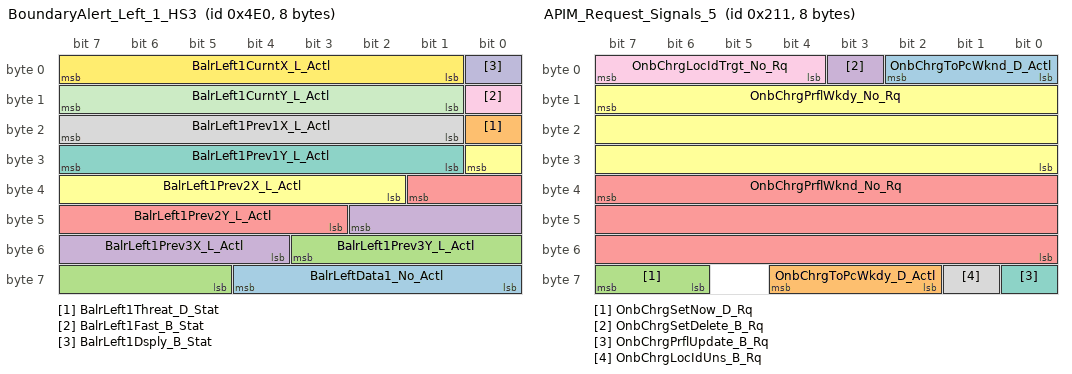
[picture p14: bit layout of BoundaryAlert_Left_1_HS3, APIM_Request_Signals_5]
BO_ 1248 BoundaryAlert_Left_1_HS3: 8 GWM
 SG_ BalrLeftData1_No_Actl : 60|5@0+ (1,0) [0|31] "unitless" Vector__XXX
 SG_ BalrLeft1Threat_D_Stat : 16|1@0+ (1,0) [0|1] "SED"  IPC
 SG_ BalrLeft1Prev3Y_L_Actl : 51|7@0+ (0.5,-32) [-32|31.5] "meter"  IPC
 SG_ BalrLeft1Prev3X_L_Actl : 42|7@0+ (0.5,-32) [-32|31.5] "meter"  IPC
 SG_ BalrLeft1Prev2Y_L_Actl : 33|7@0+ (0.5,-32) [-32|31.5] "meter"  IPC
 SG_ BalrLeft1Prev2X_L_Actl : 24|7@0+ (0.5,-32) [-32|31.5] "meter"  IPC
 SG_ BalrLeft1Prev1Y_L_Actl : 31|7@0+ (0.5,-32) [-32|31.5] "meter"  IPC
 SG_ BalrLeft1Prev1X_L_Actl : 23|7@0+ (0.5,-32) [-32|31.5] "meter"  IPC
 SG_ BalrLeft1Fast_B_Stat : 8|1@0+ (1,0) [0|1] "SED"  IPC
 SG_ BalrLeft1Dsply_B_Stat : 0|1@0+ (1,0) [0|1] "SED"  IPC
 SG_ BalrLeft1CurntY_L_Actl : 15|7@0+ (0.5,-32) [-32|31.5] "meter"  IPC
 SG_ BalrLeft1CurntX_L_Actl : 7|7@0+ (0.5,-32) [-32|31.5] "meter"  IPC

BO_ 1256 GWM_Send_Signals_15_HS3: 8 GWM
 SG_ BalrMdeRight_D_Stat_UB : 21|1@0+ (1,0) [0|1] "SED"  IPC
 SG_ BalrMdeSelRight_B_Stat_UB : 17|1@0+ (1,0) [0|1] "SED"  IPC
 SG_ BalrRight_D_Stat_UB : 16|1@0+ (1,0) [0|1] "SED"  IPC
 SG_ BalrLckRight_B_Stat_UB : 14|1@0+ (1,0) [0|1] "SED"  IPC
 SG_ BalrChimeRight_D_Rq_UB : 2|1@0+ (1,0) [0|1] "SED"  IPC
 SG_ BalrSnsRight_D_Falt_UB : 24|1@0+ (1,0) [0|1] "SED"  IPC
 SG_ BalrWndwRight_B_Stat_UB : 36|1@0+ (1,0) [0|1] "SED"  IPC
 SG_ BalrLckRight_B_Stat : 15|1@0+ (1,0) [0|1] "SED"  IPC
 SG_ BalrWndwRight_B_Stat : 37|1@0+ (1,0) [0|1] "SED"  IPC
 SG_ BalrMdeSelRight_B_Stat : 18|1@0+ (1,0) [0|1] "SED"  IPC
 SG_ BalrSnsRight_D_Falt : 26|2@0+ (1,0) [0|3] "SED"  IPC
 SG_ BalrChimeRight_D_Rq : 4|2@0+ (1,0) [0|3] "SED"  IPC
 SG_ BalrMdeRight_D_Stat : 23|2@0+ (1,0) [0|3] "SED"  IPC
 SG_ BalrRight_D_Stat : 31|2@0+ (1,0) [0|3] "SED"  IPC
 SG_ BalrWndwLeft_B_Stat_UB : 38|1@0+ (1,0) [0|1] "SED"  IPC
 SG_ BalrSnsLeft_D_Falt_UB : 27|1@0+ (1,0) [0|1] "SED"  IPC
 SG_ BalrMdeSelLeft_B_Stat_UB : 19|1@0+ (1,0) [0|1] "SED"  IPC
 SG_ BalrMdeLeft_D_Stat_UB : 8|1@0+ (1,0) [0|1] "SED"  IPC
 SG_ BalrLeft_D_Stat_UB : 11|1@0+ (1,0) [0|1] "SED"  IPC
 SG_ BalrLckLeft_B_Stat_UB : 0|1@0+ (1,0) [0|1] "SED"  IPC
 SG_ BalrChimeLeft_D_Rq_UB : 5|1@0+ (1,0) [0|1] "SED"  IPC
 SG_ BalrLeft_D_Stat : 13|2@0+ (1,0) [0|3] "SED"  IPC
 SG_ BalrMdeSelLeft_B_Stat : 20|1@0+ (1,0) [0|1] "SED"  IPC
 SG_ BalrLckLeft_B_Stat : 1|1@0+ (1,0) [0|1] "SED"  IPC
 SG_ BalrWndwLeft_B_Stat : 39|1@0+ (1,0) [0|1] "SED"  IPC
 SG_ BalrMdeLeft_D_Stat : 10|2@0+ (1,0) [0|3] "SED"  IPC
 SG_ BalrSnsLeft_D_Falt : 29|2@0+ (1,0) [0|3] "SED"  IPC
 SG_ BalrChimeLeft_D_Rq : 7|2@0+ (1,0) [0|3] "SED"  IPC
 SG_ WakeAlarm2_D_Stat_UB : 33|1@0+ (1,0) [0|1] "SED"  TRM_ITRM
 SG_ WakeAlarm2_D_Stat : 35|2@0+ (1,0) [0|3] "SED"  TRM_ITRM

BO_ 529 APIM_Request_Signals_5: 8 APIM
 SG_ OnbChrgToPcWknd_D_Actl : 2|3@0+ (1,0) [0|7] "percent"  GWM
 SG_ OnbChrgToPcWkdy_D_Actl : 60|3@0+ (1,0) [0|7] "percent"  GWM
 SG_ OnbChrgSetNow_D_Rq : 63|2@0+ (1,0) [0|3] "SED"  GWM
 SG_ OnbChrgSetDelete_B_Rq : 3|1@0+ (1,0) [0|1] "SED"  GWM
 SG_ OnbChrgPrflWknd_No_Rq : 39|24@0+ (1,0) [0|16777215] "unitless"  GWM
 SG_ OnbChrgPrflWkdy_No_Rq : 15|24@0+ (1,0) [0|16777215] "unitless"  GWM
 SG_ OnbChrgPrflUpdate_B_Rq : 56|1@0+ (1,0) [0|1] "SED"  GWM
 SG_ OnbChrgLocIdUns_B_Rq : 57|1@0+ (1,0) [0|1] "SED"  GWM
 SG_ OnbChrgLocIdTrgt_No_Rq : 7|4@0+ (1,0) [0|15] "Unitless"  GWM

BO_ 642 GWM_Send_Signals_14_HS3: 8 GWM
 SG_ SldrrMsgTxt_D2_Rq_UB : 8|1@0+ (1,0) [0|1] "SED"  IPC
 SG_ SldrrMsgTxt_D2_Rq : 11|3@0+ (1,0) [0|7] "SED"  IPC
 SG_ SldrrChime_D_Rq_UB : 12|1@0+ (1,0) [0|1] "SED"  IPC
 SG_ SldrrChime_D_Rq : 15|3@0+ (1,0) [0|7] "SED"  IPC
 SG_ SldrlMsgTxt_D2_Rq_UB : 0|1@0+ (1,0) [0|1] "SED"  IPC
 SG_ SldrlMsgTxt_D2_Rq : 3|3@0+ (1,0) [0|7] "SED"  IPC
 SG_ SldrlChime_D_Rq_UB : 4|1@0+ (1,0) [0|1] "SED"  IPC
 SG_ SldrlChime_D_Rq : 7|3@0+ (1,0) [0|7] "SED"  IPC
 SG_ PaakMyKeySearch_D_Stat_UB : 27|1@0+ (1,0) [0|1] "SED"  APIM_CISM,APIM
 SG_ UreaLvlQlty_D_RqDsply_UB : 48|1@0+ (1,0) [0|1] "SED"  IPC
 SG_ DieslPrtcWarn_D_Rq_UB : 24|1@0+ (1,0) [0|1] "SED"  IPC
 SG_ UreaQltySysWarn_D_Rq_UB : 25|1@0+ (1,0) [0|1] "SED"  IPC
 SG_ UreaLvlTxtWarn_D_Rq_UB : 26|1@0+ (1,0) [0|1] "SED"  IPC
 SG_ UreaLvlQlty_D_RqDsply : 59|3@0+ (1,0) [0|7] "SED"  IPC
 SG_ UreaLvlTxtWarn_D_Rq : 63|4@0+ (1,0) [0|15] "SED"  IPC
 SG_ UreaQltySysWarn_D_Rq : 51|3@0+ (1,0) [0|7] "SED"  IPC
 SG_ DieslPrtcWarn_D_Rq : 55|4@0+ (1,0) [0|15] "SED"  IPC
 SG_ KeyMyKeyTot_No2_Cnt_UB : 40|1@0+ (1,0) [0|1] "SED"  APIM_CISM,APIM
 SG_ KeyAdmnTot_No2_Cnt_UB : 32|1@0+ (1,0) [0|1] "SED"  APIM_CISM,APIM
 SG_ KeyMyKeyTot_No2_Cnt : 47|7@0+ (1,0) [0|127] "unitless"  APIM_CISM,APIM
 SG_ KeyAdmnTot_No2_Cnt : 39|7@0+ (1,0) [0|127] "unitless"  APIM_CISM,APIM
 SG_ DcChrgSrvcRqd_B_Rq_UB : 31|1@0+ (1,0) [0|1] "SED"  IPC
 SG_ DcChrgSrvcRqd_B_Rq : 16|1@0+ (1,0) [0|1] "SED"  IPC
 SG_ PaakMyKeySearch_D_Stat : 30|3@0+ (1,0) [0|7] "SED"  APIM_CISM,APIM
 SG_ GrdAsstActv_B_Stat_UB : 17|1@0+ (1,0) [0|1] "SED"  IPC
 SG_ GrdAsstActv_B_Stat : 18|1@0+ (1,0) [0|1] "SED"  IPC
 SG_ TrlrAidTrlrId_No_Rq_UB : 19|1@0+ (1,0) [0|1] "SED"  APIM_CISM,IPC,APIM
 SG_ TrlrAidTrlrId_No_Rq : 23|4@0+ (1,0) [0|15] "unitless"  APIM_CISM,IPC,APIM

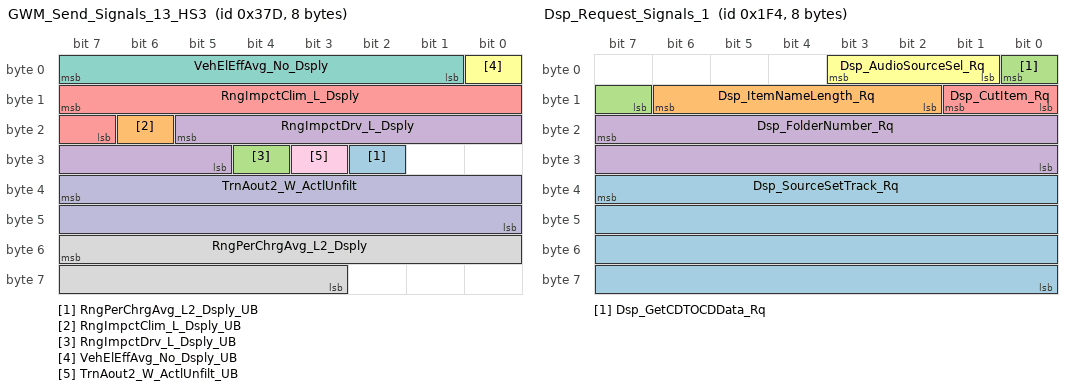
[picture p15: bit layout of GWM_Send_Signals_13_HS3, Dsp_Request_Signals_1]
BO_ 893 GWM_Send_Signals_13_HS3: 8 GWM
 SG_ RngPerChrgAvg_L2_Dsply_UB : 26|1@0+ (1,0) [0|1] "SED"  APIM,APIM_CISM,IPC
 SG_ RngImpctClim_L_Dsply_UB : 22|1@0+ (1,0) [0|1] "SED"  IPC
 SG_ RngImpctDrv_L_Dsply_UB : 28|1@0+ (1,0) [0|1] "SED"  IPC
 SG_ RngImpctDrv_L_Dsply : 21|9@0+ (1,-255) [-255|256] "km"  IPC
 SG_ RngImpctClim_L_Dsply : 15|9@0+ (1,-255) [-255|256] "km"  IPC
 SG_ VehElEffAvg_No_Dsply_UB : 0|1@0+ (1,0) [0|1] "SED"  APIM_CISM,IPC,APIM
 SG_ VehElEffAvg_No_Dsply : 7|7@0+ (10,-100) [-100|1150] "wattHr/km"  APIM_CISM,IPC,APIM
 SG_ RngPerChrgAvg_L2_Dsply : 55|13@0+ (0.1,0) [0|818.9] "km"  APIM,APIM_CISM,IPC
 SG_ TrnAout2_W_ActlUnfilt_UB : 27|1@0+ (1,0) [0|1] "SED"  APIM_CISM,ACM
 SG_ TrnAout2_W_ActlUnfilt : 39|16@0+ (0.1,-3276.5) [-3276.5|3276.8] "rad/s"  APIM_CISM,ACM

BO_ 500 Dsp_Request_Signals_1: 8 APIM
 SG_ Dsp_SourceSetTrack_Rq : 39|32@0+ (1,0) [0|4294967295] "unitless"  ACM
 SG_ Dsp_ItemNameLength_Rq : 14|5@0+ (1,0) [0|20] "SED"  ACM
 SG_ Dsp_GetCDTOCDData_Rq : 0|2@0+ (1,0) [0|3] "SED"  ACM
 SG_ Dsp_FolderNumber_Rq : 23|16@0+ (1,0) [0|65535] "unitless"  ACM
 SG_ Dsp_CutItem_Rq : 9|2@0+ (1,0) [0|3] "SED"  ACM
 SG_ Dsp_AudioSourceSel_Rq : 3|3@0+ (1,0) [0|7] "SED"  ACM

BO_ 503 Dsp_Request_Signals_4: 8 APIM
 SG_ Dsp_PlayFrstTrInFldr_Rq : 39|16@0+ (1,0) [0|65535] "unitless"  ACM
 SG_ Dsp_ItemIndex_Rq : 23|16@0+ (1,0) [0|65535] "unitless"  ACM
 SG_ Dsp_FolderNumber3_Rq : 7|16@0+ (1,0) [0|65535] "unitless"  ACM
 SG_ Dsp_AudioSourceSel3_Rq : 55|3@0+ (1,0) [0|7] "SED"  ACM

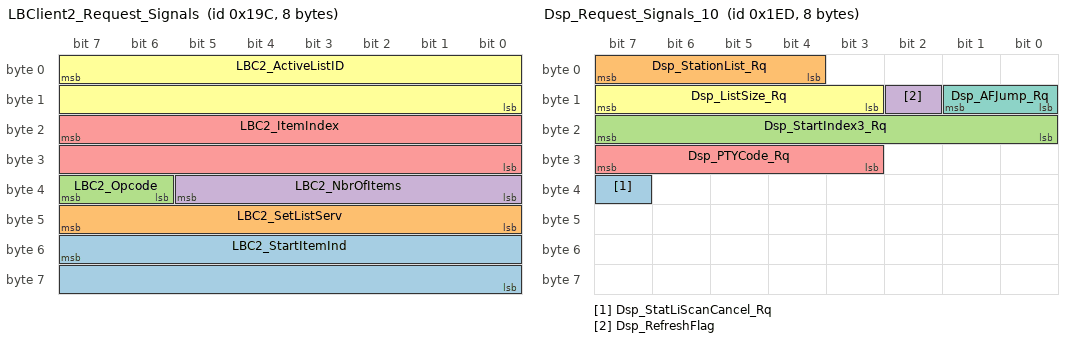
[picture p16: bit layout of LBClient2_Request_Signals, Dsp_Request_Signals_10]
BO_ 412 LBClient2_Request_Signals: 8 APIM
 SG_ LBC2_StartItemInd : 55|16@0+ (1,0) [0|65535] "unitless"  ACM
 SG_ LBC2_SetListServ : 47|8@0+ (1,0) [0|255] "unitless"  ACM
 SG_ LBC2_Opcode : 39|2@0+ (1,0) [0|3] "SED"  ACM
 SG_ LBC2_NbrOfItems : 37|6@0+ (1,0) [0|63] "unitless"  ACM
 SG_ LBC2_ItemIndex : 23|16@0+ (1,0) [0|65535] "unitless"  ACM
 SG_ LBC2_ActiveListID : 7|16@0+ (1,0) [0|65535] "unitless"  ACM

BO_ 493 Dsp_Request_Signals_10: 8 APIM
 SG_ Dsp_StatLiScanCancel_Rq : 39|1@0+ (1,0) [0|1] "SED"  ACM
 SG_ Dsp_StationList_Rq : 7|4@0+ (1,0) [0|15] "SED"  ACM
 SG_ Dsp_StartIndex3_Rq : 23|8@0+ (1,0) [0|255] "unitless"  ACM
 SG_ Dsp_RefreshFlag : 10|1@0+ (1,0) [0|1] "SED"  ACM
 SG_ Dsp_PTYCode_Rq : 31|5@0+ (1,0) [0|31] "SED"  ACM
 SG_ Dsp_ListSize_Rq : 15|5@0+ (1,0) [0|31] "SED"  ACM
 SG_ Dsp_AFJump_Rq : 9|2@0+ (1,0) [0|3] "SED"  ACM

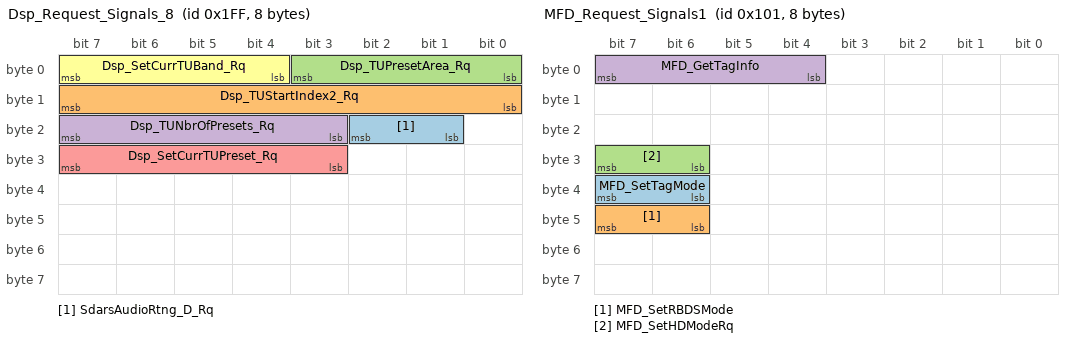
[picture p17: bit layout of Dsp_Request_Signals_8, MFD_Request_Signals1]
BO_ 511 Dsp_Request_Signals_8: 8 APIM
 SG_ SdarsAudioRtng_D_Rq : 18|2@0+ (1,0) [0|3] "SED"  ACM
 SG_ Dsp_TUStartIndex2_Rq : 15|8@0+ (1,0) [0|255] "unitless"  ACM
 SG_ Dsp_TUPresetArea_Rq : 3|4@0+ (1,0) [0|15] "SED"  ACM
 SG_ Dsp_TUNbrOfPresets_Rq : 23|5@0+ (1,0) [0|30] "SED"  ACM
 SG_ Dsp_SetCurrTUPreset_Rq : 31|5@0+ (1,0) [0|31] "SED"  ACM
 SG_ Dsp_SetCurrTUBand_Rq : 7|4@0+ (1,0) [0|15] "SED"  ACM

BO_ 257 MFD_Request_Signals1: 8 APIM
 SG_ MFD_SetTagMode : 39|2@0+ (1,0) [0|3] "SED"  ACM
 SG_ MFD_SetRBDSMode : 47|2@0+ (1,0) [0|3] "SED"  ACM
 SG_ MFD_SetHDModeRq : 31|2@0+ (1,0) [0|3] "SED"  ACM
 SG_ MFD_GetTagInfo : 7|4@0+ (1,0) [0|15] "day"  ACM

BO_ 713 SDARS_RDISP_WORD_Rx: 8 APIM
 SG_ SDARS_RDISP_WORD_Rx : 7|64@0+ (1,0) [0|1.84467440737096E+019] "unitless"  ACM

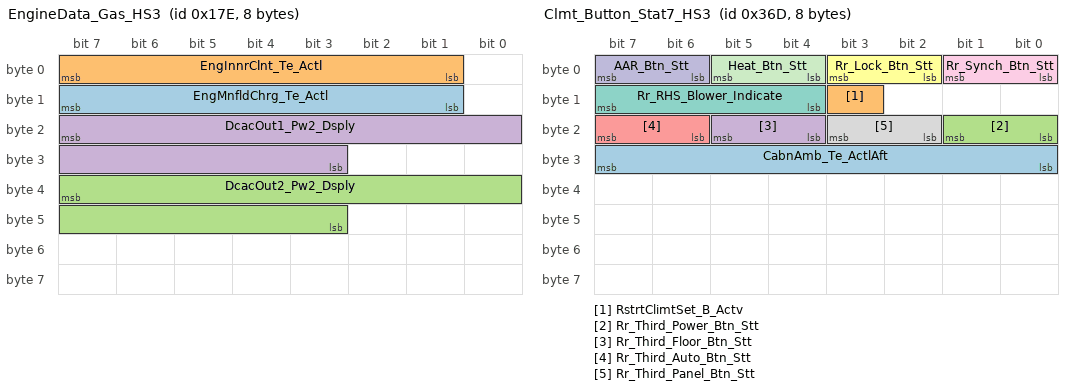
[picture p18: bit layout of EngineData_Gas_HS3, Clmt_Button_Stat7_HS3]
BO_ 382 EngineData_Gas_HS3: 8 GWM
 SG_ EngMnfldChrg_Te_Actl : 15|7@0+ (1,-20) [-20|105] "degC"  IPC
 SG_ EngInnrClnt_Te_Actl : 7|7@0+ (1,50) [50|175] "degC"  IPC
 SG_ DcacOut2_Pw2_Dsply : 39|13@0+ (1,0) [0|8189] "watts"  APIM,APIM_CISM
 SG_ DcacOut1_Pw2_Dsply : 23|13@0+ (1,0) [0|8189] "watts"  APIM,APIM_CISM

BO_ 877 Clmt_Button_Stat7_HS3: 8 GWM
 SG_ CabnAmb_Te_ActlAft : 31|8@0+ (0.5,-57) [-57|70] "degC"  GENERIC
 SG_ RstrtClimtSet_B_Actv : 11|1@0+ (1,0) [0|1] "SED"  GENERIC
 SG_ Rr_Third_Power_Btn_Stt : 17|2@0+ (1,0) [0|3] "SED"  APIM_CISM,APIM,RACM_RCIM
 SG_ Rr_Third_Floor_Btn_Stt : 21|2@0+ (1,0) [0|3] "SED"  APIM_CISM,APIM,RACM_RCIM
 SG_ Rr_Third_Auto_Btn_Stt : 23|2@0+ (1,0) [0|3] "SED"  APIM_CISM,APIM,RACM_RCIM
 SG_ Rr_Lock_Btn_Stt : 3|2@0+ (1,0) [0|3] "SED"  APIM_CISM,RACM_RCIM,APIM
 SG_ Rr_RHS_Blower_Indicate : 15|4@0+ (1,0) [0|15] "SED"  APIM_CISM,RACM_RCIM,APIM
 SG_ Rr_Third_Panel_Btn_Stt : 19|2@0+ (1,0) [0|3] "SED"  APIM_CISM,APIM,RACM_RCIM
 SG_ Rr_Synch_Btn_Stt : 1|2@0+ (1,0) [0|3] "SED"  RACM_RCIM,APIM_CISM,APIM
 SG_ AAR_Btn_Stt : 7|2@0+ (1,0) [0|3] "SED"  RACM_RCIM,APIM_CISM,FCIMB,APIM
 SG_ Heat_Btn_Stt : 5|2@0+ (1,0) [0|3] "SED"  RACM_RCIM,APIM_CISM,FCIMB,APIM

BO_ 592 RFA_BLEM_APIM_Tx_HS3: 8 GWM
 SG_ RFA_BLEM_APIM_Tx : 7|64@0+ (1,0) [0|1.84467440737096E+019] "unitless"  APIM_CISM,APIM

BO_ 600 APIM_RFA_BLEM_Tx: 8 APIM
 SG_ APIM_RFA_BLEM_Tx : 7|64@0+ (1,0) [0|1.84467440737096E+019] "unitless"  GWM

BO_ 708 TMCSrvr_TMCClnt_WORD_Tx: 8 ACM
 SG_ TMCSrvr_TMCClnt_WORD_Tx : 7|64@0+ (1,0) [0|1.84467440737096E+019] "unitless"  APIM

BO_ 414 LBS2_Indication_Signals: 8 ACM
 SG_ LBS2_ListStatus : 57|2@0+ (1,0) [0|3] "SED"  RACM_RCIM,APIM,IPC
 SG_ LBS2_ParentID : 31|16@0+ (1,0) [0|65535] "unitless"  RACM_RCIM,APIM,IPC
 SG_ LBS2_ListServer : 7|8@0+ (1,0) [0|255] "unitless"  RACM_RCIM,APIM,IPC
 SG_ LBS2_ListID : 15|16@0+ (1,0) [0|65535] "unitless"  RACM_RCIM,APIM,IPC
 SG_ LBS2_EntryIndex : 47|16@0+ (1,0) [0|65535] "unitless"  APIM,IPC,RACM_RCIM

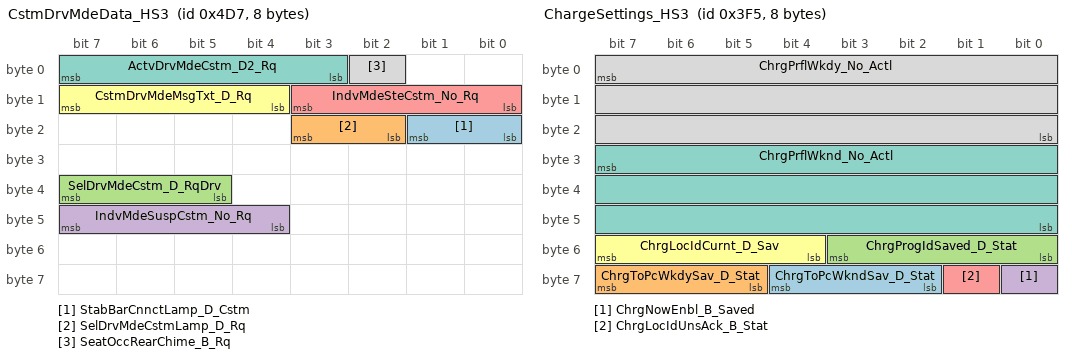
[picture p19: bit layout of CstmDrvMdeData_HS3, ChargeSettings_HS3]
BO_ 1239 CstmDrvMdeData_HS3: 8 GWM
 SG_ StabBarCnnctLamp_D_Cstm : 17|2@0+ (1,0) [0|3] "SED"  IPC
 SG_ SelDrvMdeCstmLamp_D_Rq : 19|2@0+ (1,0) [0|3] "SED"  IPC
 SG_ SelDrvMdeCstm_D_RqDrv : 39|3@0+ (1,0) [0|7] "SED"  IPC
 SG_ IndvMdeSuspCstm_No_Rq : 47|4@0+ (1,0) [0|15] "unitless"  IPC
 SG_ IndvMdeSteCstm_No_Rq : 11|4@0+ (1,0) [0|15] "unitless"  IPC
 SG_ CstmDrvMdeMsgTxt_D_Rq : 15|4@0+ (1,0) [0|15] "SED"  IPC
 SG_ ActvDrvMdeCstm_D2_Rq : 7|5@0+ (1,0) [0|31] "SED"  IPC
 SG_ SeatOccRearChime_B_Rq : 2|1@0+ (1,0) [0|1] "SED"  IPC

BO_ 716 TMCSrvr_TMCClient_WORD_Rx: 8 APIM
 SG_ TMCSrvr_TMCClnt_WORD_Rx : 7|64@0+ (1,0) [0|1.84467440737096E+019] "unitless"  ACM

BO_ 1013 ChargeSettings_HS3: 8 GWM
 SG_ ChrgToPcWkndSav_D_Stat : 60|3@0+ (1,0) [0|7] "SED"  APIM_CISM,APIM
 SG_ ChrgToPcWkdySav_D_Stat : 63|3@0+ (1,0) [0|7] "SED"  APIM_CISM,APIM
 SG_ ChrgProgIdSaved_D_Stat : 51|4@0+ (1,0) [0|15] "Unitless"  APIM_CISM,APIM
 SG_ ChrgNowEnbl_B_Saved : 56|1@0+ (1,0) [0|1] "SED"  APIM_CISM,APIM
 SG_ ChrgLocIdUnsAck_B_Stat : 57|1@0+ (1,0) [0|1] "SED"  APIM_CISM,APIM
 SG_ ChrgLocIdCurnt_D_Sav : 55|4@0+ (1,0) [0|15] "unitless"  APIM_CISM,IPC,APIM
 SG_ ChrgPrflWknd_No_Actl : 31|24@0+ (1,0) [0|16777215] "unitless"  APIM_CISM,APIM
 SG_ ChrgPrflWkdy_No_Actl : 7|24@0+ (1,0) [0|16777215] "unitless"  APIM_CISM,APIM

BO_ 641 GWM_Send_Signals_10_HS3: 8 GWM
 SG_ ChrgGoTElement_B_Dsply_UB : 57|1@0+ (1,0) [0|1] "SED"  APIM,APIM_CISM
 SG_ ChrgGoTElement_B_Dsply : 58|1@0+ (1,0) [0|1] "SED"  APIM,APIM_CISM
 SG_ BattChrgTrgtSoC_D_Rq : 46|3@0+ (1,0) [0|7] "Percent"  IPC
 SG_ BattChrgTrgtSoC_D_Rq_UB : 43|1@0+ (1,0) [0|1] "SED"  IPC
 SG_ ChrgLocIdCurnt_D_Uns_UB : 59|1@0+ (1,0) [0|1] "SED"  APIM_CISM,APIM
 SG_ ChrgLocIdCurnt_D_Uns : 63|4@0+ (1,0) [0|15] "unitless"  APIM_CISM,APIM
 SG_ IgnPsswrdActv_B_Stat_UB : 54|1@0+ (1,0) [0|1] "SED"  APIM_CISM,APIM
 SG_ IgnPsswrdSetup_B_Rq_UB : 50|1@0+ (1,0) [0|1] "SED"  APIM_CISM,APIM
 SG_ IgnPsswrdLckout_B_Stat_UB : 51|1@0+ (1,0) [0|1] "SED"  APIM_CISM,APIM
 SG_ IgnPsswrdSetup_B_Rq : 52|1@0+ (1,0) [0|1] "SED"  APIM_CISM,APIM
 SG_ IgnPsswrdLckout_B_Stat : 53|1@0+ (1,0) [0|1] "SED"  APIM_CISM,APIM
 SG_ PaakCnnct_D_Stat_UB : 40|1@0+ (1,0) [0|1] "SED"  APIM_CISM,APIM
 SG_ PaakCnnct_D_Stat : 42|2@0+ (1,0) [0|3] "SED"  APIM_CISM,APIM
 SG_ IgnPsswrdActv_B_Stat : 55|1@0+ (1,0) [0|1] "SED"  APIM_CISM,APIM
 SG_ ChrgGoTTouch_B_Stat_UB : 47|1@0+ (1,0) [0|1] "SED"  APIM_CISM,APIM
 SG_ ChrgGoTTouch_B_Stat : 24|1@0+ (1,0) [0|1] "SED"  APIM_CISM,APIM
 SG_ ChrgGoTPrcond_D_Stat_UB : 16|1@0+ (1,0) [0|1] "SED"  APIM_CISM,APIM
 SG_ ChrgGoTPrcond_D_Stat : 26|2@0+ (1,0) [0|3] "SED"  APIM_CISM,APIM
 SG_ ChrgGoTNext_D_Stat_UB : 17|1@0+ (1,0) [0|1] "SED"  APIM_CISM,APIM
 SG_ ChrgGoTNext_D_Stat : 35|4@0+ (1,0) [0|15] "Unitless"  APIM_CISM,APIM
 SG_ ChrgGoTMnte_D_Stat_UB : 18|1@0+ (1,0) [0|1] "SED"  APIM_CISM,APIM
 SG_ ChrgGoTMnte_D_Stat : 39|4@0+ (1,0) [0|15] "SED"  APIM_CISM,APIM
 SG_ ChrgGoTHr_T_Stat_UB : 19|1@0+ (1,0) [0|1] "SED"  APIM_CISM,APIM
 SG_ ChrgGoTHr_T_Stat : 31|5@0+ (1,0) [0|29] "hour"  APIM_CISM,APIM
 SG_ ChrgGoTExtHtr_B_Stat_UB : 8|1@0+ (1,0) [0|1] "SED"  APIM_CISM,APIM
 SG_ ChrgGoTExtHtr_B_Stat : 9|1@0+ (1,0) [0|1] "SED"  APIM_CISM,APIM
 SG_ ChrgGoTElement_D_Stat_UB : 10|1@0+ (1,0) [0|1] "SED"  APIM_CISM,APIM
 SG_ ChrgGoTElement_D_Stat : 23|4@0+ (1,0) [0|15] "Unitless"  APIM_CISM,APIM
 SG_ ChrgGoTAllOn_B_Stat_UB : 11|1@0+ (1,0) [0|1] "SED"  APIM_CISM,APIM
 SG_ ChrgGoTAllOn_B_Stat : 12|1@0+ (1,0) [0|1] "SED"  APIM_CISM,APIM
 SG_ TrlrAidMsgTxt_D2_Rq : 7|6@0+ (1,0) [0|63] "SED"  APIM_CISM,IPC,TRM_ITRM,APIM
 SG_ TrlrAidEnbl_D2_Stat : 15|3@0+ (1,0) [0|7] "SED"  APIM_CISM,IPC,TRM_ITRM,APIM
 SG_ TrlrAidMsgTxt_D2_Rq_UB : 1|1@0+ (1,0) [0|1] "SED"  APIM_CISM,IPC,TRM_ITRM,APIM
 SG_ TrlrAidEnbl_D2_Stat_UB : 0|1@0+ (1,0) [0|1] "SED"  APIM_CISM,IPC,TRM_ITRM,APIM

BO_TX_BU_ 479 : APIM_CISM,APIM;
BO_TX_BU_ 474 : APIM_CISM,APIM;
BO_TX_BU_ 477 : APIM_CISM,APIM;
BO_TX_BU_ 260 : APIM_CISM,APIM;
BO_TX_BU_ 1116 : APIM_CISM,APIM;
BO_TX_BU_ 529 : APIM_CISM,APIM;
BO_TX_BU_ 600 : APIM_CISM,APIM;
BO_TX_BU_ 414 : APIM_CISM,ACM;
CM_ SG_ 1104 DrvEngageLevel_No_Cs "Signal not transmitted on gas variants.";
CM_ SG_ 1104 DrvEngageLevel_No_Cnt "Signal not transmitted on gas variants.";
CM_ SG_ 773 MemSwtchPsngrFdbck_B_Rq "Updated to 1 bit for CGEA, Not backwards compatible";
CM_ SG_ 746 Con_BTAud_Shuffle_St "Object MediaPlayer BTAudio.Shuffle";
CM_ SG_ 746 Con_BTAud_Repeat_St "Object Media Player BTAudio.Repeat";
CM_ SG_ 746 Con_BTAud_IntroScan_St "Object Media Player BTAudio.IntroScan";
CM_ SG_ 746 Con_BTAud_ActTrNum1_St "Object Media Player BTAudio.ActiveTrackNum1
";
CM_ SG_ 746 Con_ShowBTPINNumb_St "Object BT Device.ShowBTPINNumb

PIN value range (dec): 0000 - 9999

Inactive: $3FFD
Invalid: $3FFE";
CM_ SG_ 746 Con_BTAud_Error_St "Object Media Player BTAudio.BTAudioError";
CM_ SG_ 746 Con_BTAud_FunctStats_St "Object Media Player BTAudio.FunctionStatus";
CM_ SG_ 746 Con_BTAud_OpMode_St "Object Media Player BTAudio.OperationMode";
CM_ SG_ 479 DISP_SetVol_Source_Rq "Object.VolumeControl.MFD_SetVol_Source.Rq

SetVol_Source.Rq";
CM_ SG_ 479 DISP_SetVol_Level_Rq "Object.VolumeControl.MFD_SetVol_Level.Rq 

0x0 Inactive/NoChange
0x1 No Volume
0x2 Vol_Step1
0x3 Vol_Step2
0x4 Vol_Step3
Cont.
0x1F Vol_Step30

Object.VolumeControl.SetPointVolume

Object.VolumeControl.SetVol_Level.Rq";
CM_ SG_ 479 DISP_Setshaker_Rq "Object.AudioSettings.SetShaker.Rq
";
CM_ SG_ 474 Nav_SetCurrStatMCCh_Rq "Object Audio.SetDSPProgram
";
CM_ SG_ 474 NAV_SetNEWSMode_Rq "Object Tuner.SetNEWSMode";
CM_ SG_ 474 NAV_SetMid_Rq "Object Audio Settings.SetMid

Level -7..0..7
$F: Inactive

Method: SetMidRange.Rq";
CM_ SG_ 474 NAV_SetDSP_Rq "Object Audio.SetDSP

Object.AudioSettings.SetOccupancy_Mode.Rq";
CM_ SG_ 474 NAV_SetCurrStatFreq_Rq "Object Tuner.SetCurrentStat.Request.Frequency

AM: Freq = 153+ Offset kHz.
Offset 0..1557

FM: Freq = 76+ Offset*0.05 MHz. Offset 0..640
Selected tuned band determine frequency (kHz or MHz).";
CM_ SG_ 474 NAV_SetCurrentStatOp_Rq "Object Tuner.SetCurrentStat.Request.Operation";
CM_ SG_ 474 NAV_SetCurrentPICode_Rq "Object Tuner.SetCurrentStat.Request.PI Code

16 bit hex coded PI Code

";
CM_ SG_ 474 NAV_ARReqstrSystem_Rq "Object Audio Management AudioClient.AudioRequest.Requester System

AudioRequest.Rq : RequesterSystem";
CM_ SG_ 474 NAV_ARReqstrPriority_Rq "Object Audio Management AudioClient.AudioRequest.Requester Priority

AudioRequest.Rq : RequesterPriority";
CM_ SG_ 474 NAV_AROperationType_Rq "Object Audio Management Audio Client.AudioRequest.Operation Type

AudioRequest.Rq : OperationType";
CM_ SG_ 474 NAV_ARAudioSource_Rq "Object Audio Management Audio Client.AudioRequest.Requested Audio Source

$8 interpreted as APIM or Navigation

AudioRequest.Rq : RequestedAudioSource";
CM_ SG_ 477 NAV_SetTreble_Rq "Object Audio.SetTreble.Rq



Level -7..0..7
$F: Inactive";
CM_ SG_ 477 NAV_SetFader_Rq "Object Audio.SetFader

.Rq

Level -7..0..7

$F: Inactive";
CM_ SG_ 477 NAV_SetBass_Rq "Object Audio.SetBass.Rq



Level -7..0..7
$F: Inactive";
CM_ SG_ 477 NAV_SetBalance_Rq "Object Audio.SetBalance.Rq



Level -7..0..7
$F: Inactive";
CM_ SG_ 477 NAV_SetAVC_Rq "Object Audio.SetAVC
Object. Audio.SetSpeed_Comp_Vol.Rq

$F: Inactive";
CM_ SG_ 477 NAV_SecurtyPINUnlock_Rq "Object ACU System Master.SecurityPINUnlock
PIN: from 0000 - 9999
$3FFF: Inactive";
CM_ SG_ 477 NAV_LoadEjectMode_Rq "Object Single CD.LoadEject.Mode";
CM_ SG_ 477 NAV_LoadEjectDisc_Rq "Object Indash CD Changer.LoadEject(Disc Number)
Object Single CD.LoadEject(Action)
";
CM_ SG_ 260 SDARS_GetESN_Rq "Object Tuner.SDARS Tuner.GetESN";
CM_ SG_ 260 SDARS_SRReplay_Rq "Object Tuner.SDARS Tuner.SR-ReplayStatus";
CM_ SG_ 260 SDARS_SelectCategory_Rq "Object Tuner.SDARS Tuner.SetCategory
0x00: All
0x01: Category1
0x02: Category2
....
0xF9: Category249
0xFA: Reserved
....
0xFE: Reserved
0xFF: Invalid
";
CM_ SG_ 260 SDARS_InfoRefChanNum_Rq "Object Tuner.SDARS Tuner.InfoRefresh.Rq
$0: Channel_0
$1: Channel_1
$2: Channel_2
$FE: Channel_254
$FF: Inactive";
CM_ SG_ 260 SDARS_FactoryReset_Rq "Object Tuner.SDARS Tuner.FactoryReset

Object VehicleSettings.FactoryReset.Rq

Object StationManagement.FactoryReset.Rq

Enhanced Memory: FactoryReset_Rq";
CM_ SG_ 476 NAV_SkipCatalouge_Rq "Object Single CD.SkipFolder";
CM_ SG_ 476 NAV_SetOperationMode_Rq "Object Rear CD Changer.SetOperationMode
Object Indash CD Changer.SetOperationMode
Object Single CD.SetOperationMode";
CM_ SG_ 476 NAV_SetDSPProgram_Rq "Object Audio.SetDSPProgram
";
CM_ SG_ 502 Dsp_StartItemIndexRq "Object Media Player BT SDCard.GetMPInfo.StartItemIndex
USB.GetMPInfo.StartItemIndex
SingleCD.GetMPInfo.StartItemIndex

$FFFF: Inactive";
CM_ SG_ 502 Dsp_NbrOfItems2_Rq "Object Media Player 
BT Audio.GetMPInfo.NbrOfItems
SDCard.GetMPInfo.NbrOfItems
USB.GetMPInfo.NbrOfItems
SingleCD.GetMPInfo.NbrOfItems";
CM_ SG_ 502 Dsp_ItemNameLength2_Rq "Object Media Player 
BT Audio.GetMPInfo.ItemNameLength
SDCard.GetMPInfo.ItemNameLength
USB.GetMPInfo.ItemNameLength
SingleCD.GetMPInfo.ItemNameLength";
CM_ SG_ 502 Dsp_FolderNumber2_Rq "Object Media Player 
BT Audio.GetMPInfo.FolderNumber
USB.GetMPInfo.FolderNumber
SDCard.GetMPInfo.FolderNumber
SingleCD.GetMPInfo.FolderNumber

$FFFF: Inactive";
CM_ SG_ 502 Dsp_FolderContent_Rq "Object Media Player 
BT Audio.GetMPInfo.FolderContent
SDCard.GetMPInfo.FolderContent
USB.GetMPInfo.FolderContent
SingleCD.GetMPinfo.Foldercontent

Note: Value table entries were truncated from:
$0: ..FolderNumber
$1: ..OfParameterFolderNumber";
CM_ SG_ 502 Dsp_CutItem2_Rq "Object Media Player 
BT Audio.GetMPInfo.CutItemName
SDCard.GetMPInfo.CutItemName
USB.GetMPInfo.CutItemName
SingleCD.GetMPInfo.CutItemName

Note: value table entry for value $2 was truncated from:
OneQuarterFromTheBeginningThreeQuarterFromTheEnd";
CM_ SG_ 502 Dsp_AudioSourceSel2_Rq "Object Media Player 
BT Audio.GetMPInfo.AudioSource
SDCard.GetMPInfo.AudioSource
USB.GetMPInfo.AudioSource
SingleCD.GetMPInfo.AudioSource";
CM_ SG_ 500 Dsp_SourceSetTrack_Rq "Object Media Player BTAudio.SetTrack
Object Media Player USB.SetTrack
Object Single CD.SetTrack.AudioSource
";
CM_ SG_ 500 Dsp_ItemNameLength_Rq "Object Media Player BTAudio.GetFolderName.ItemNameLength
Object Media Player USB.GetFolderName.ItemNameLength
Object Single CD.GetFolderName.ItemNameLength";
CM_ SG_ 500 Dsp_GetCDTOCDData_Rq "GetCDTOCData";
CM_ SG_ 500 Dsp_FolderNumber_Rq "Object Media Player BTAudio.GetFolderName.FolderNumber
Object Media Player USB.GetFolderName.FolderNumber
Object Single CD.GetFolderName.FolderNumber";
CM_ SG_ 500 Dsp_CutItem_Rq "Object Media Player BTAudio.GetFolderName.CutItemName
Object Media Player USB.GetFolderName.CutItemName
Object Single CD.GetFolderName.CutItemName

Note: value table entry for value $2 was truncated from:
OneQuarterFromTheBeginningThreeQuarterFromTheEnd";
CM_ SG_ 500 Dsp_AudioSourceSel_Rq "Object Media Player 
{ BTAudio.GetFolderName, 
SDCard.GetFolderName,
USB.GetFolderName,
BTAudio.SetTrack,
SD Card.SetTrack}.AudioSource
USB.SetTrack.AudioSource
Object Single CD.GetFolderName.AudioSource
Object Single CD.SetTrack.AudioSource";
CM_ SG_ 503 Dsp_PlayFrstTrInFldr_Rq "Object Single CD.PlayFirstTrackInFolder
Object Media Player BTAudio.PlayFirstTrackInFolder.FolderNumber
Object Media Player USB.PlayFirstTrackInFolder.FolderNumber

$FFFF: Inactive";
CM_ SG_ 503 Dsp_ItemIndex_Rq "Object Media Player BTAudio.GetDetailedMPInfo.ItemIndex
Object Media Player USB.GetDetailedMPInfo.ItemIndex

$FFFF: Inactive";
CM_ SG_ 503 Dsp_FolderNumber3_Rq "Object Media Player BTAudio.GetDetailedMPInfo.FolderNumber
Object Media Player USB.GetDetailedMPInfo.FolderNumber

$FFFF: Inactive";
CM_ SG_ 503 Dsp_AudioSourceSel3_Rq "Objects Media Player  {BTAudio, USB}.GetDetailedMPInfo.AudioSource

Objects Media Player {Single CD, BTAudio, USB}.PlayFirstTrackInFolder.AudioSource";
CM_ SG_ 412 LBC2_StartItemInd "Object. ListBrowser.ItemInf.Rq.StartItemInd
0x0000:Inactive
0x0001:1
0xFFFE:65634
0xFFFF:Reserved";
CM_ SG_ 412 LBC2_SetListServ "Object. ListBrowser.ItemInf.Rq.SetListServ
0x00:Inactive
0x01:ServerID_1
0xFF:ALL";
CM_ SG_ 412 LBC2_Opcode "Object. ListBrowser.ItemInf.Rq.Opcode";
CM_ SG_ 412 LBC2_NbrOfItems "Object. ListBrowser.ItemInf.Rq.NbrOfItems
0x00:Inactive
0x01:1Item
0x3F:63Items";
CM_ SG_ 412 LBC2_ItemIndex "Object. ListBrowser.ItemInf.Rq.ItemIndex
0x0000:BrowseActiveListID
0x0001:EntryIndex_1
0xFFFF:ParentOfActiveListID";
CM_ SG_ 412 LBC2_ActiveListID "Object. ListBrowser.ItemInf.Rq.ActiveListID
0x0000:Root
0xFFFF:Reserved";
CM_ SG_ 493 Dsp_StatLiScanCancel_Rq "Object Tuner.StationListScan";
CM_ SG_ 493 Dsp_StationList_Rq "Object Tuner.GetStationList(StationList)
(Parameter1)";
CM_ SG_ 493 Dsp_StartIndex3_Rq "Object TunerGetStationList(StartingIndex)
(Parameter3)";
CM_ SG_ 493 Dsp_RefreshFlag "Object Tuner.GetStationList(StationList)
(Parameter5)";
CM_ SG_ 493 Dsp_PTYCode_Rq "Object Tuner.GetStationList(PTYCode)
(Parramater4)

$0: Invalid
$1: PTY 1 (News)
..
$1F: PTY 31 (Alarm)";
CM_ SG_ 493 Dsp_ListSize_Rq "Object Tuner.GetStationList(ListSize)
(Parameter2)";
CM_ SG_ 493 Dsp_AFJump_Rq "Object Tuner.AFJump.Rq";
CM_ SG_ 511 Dsp_TUStartIndex2_Rq "Object Tuner.GetTUPresetInfo.StartIndex2
Object DAB.GetTUPresetInfo.StartIndex2
Object SDARS.GetTUPresetInfo.StartIndex2

$1-$FF: Preset 1 to 255";
CM_ SG_ 511 Dsp_TUPresetArea_Rq "Object Tuner.GetTUPresetInfo.PresetArea
Object DAB.GetTUPresetInfo.PresetArea
Object SDARS.GetTUPresetInfo.PresetArea";
CM_ SG_ 511 Dsp_TUNbrOfPresets_Rq "Object Tuner.GetTUPresetInfo.NumberOfPresets
Object DAB.GetTUPresetInfo.NumberOfPresets
Object SDARS.GetTUPresetInfo.NumberOfPresets

$1-$1E: Preset 1 to 30";
CM_ SG_ 511 Dsp_SetCurrTUPreset_Rq "Object Tuner.GetTUPresetInfo.SetCurrentTUPreset
Object DAB.GetTUPresetInfo.SetCurrentTUPreset
Object SDARS.GetTUPresetInfo.SetCurrentTUPreset

$1-$1E: Preset 1 to 30";
CM_ SG_ 511 Dsp_SetCurrTUBand_Rq "Object Tuner.SetCurrTUBand
Object DAB.SetCurrTUBand
Object SDARS.SetCurrTUBand
";
CM_ SG_ 257 MFD_SetTagMode "Used by MFD to distribute actual Master Clock data to the Slave";
CM_ SG_ 257 MFD_SetRBDSMode "Used by MFD to distribute actual Master Clock data to the Slave";
CM_ SG_ 257 MFD_SetHDModeRq "Used by MFD to distribute actual Master Clock data to the Slave";
CM_ SG_ 257 MFD_GetTagInfo "Used by MFD to distribute actual Master Clock data to the Slave";
CM_ BO_ 382 "ECM, PCM Gas Only msg";
CM_ BO_ 600 "Tx by HS3 APIM";
CM_ SG_ 600 APIM_RFA_BLEM_Tx "Tx by HS3 APIM";
CM_ SG_ 708 TMCSrvr_TMCClnt_WORD_Tx "MM ISO 15765-2 Message Catalogue RDISP2 - AUDIO";
CM_ SG_ 414 LBS2_ParentID "Object. ListBrowser.ItemInf.Rq.ActiveListID
0x0000:Root
0xFFFF:Reserved";
CM_ SG_ 414 LBS2_ListID "Object. ListBrowser.ItemInf.Rq.ItemIndex
0x0000:BrowseActiveListID
0x0001:EntryIndex_1
0xFFFF:ParentOfActiveListID";
CM_ SG_ 414 LBS2_EntryIndex "Object. ListBrowser.ItemInf.Rq.ActiveListID
0x0000:Root
0xFFFF:Reserved";
BA_DEF_ BO_  "FrameRouting" STRING ;
BA_DEF_ BO_  "FrameGatewayNetwork" STRING ;
BA_DEF_ BO_  "NetworkInitialization" ENUM  "No","Yes";
BA_DEF_ BO_  "FrameGatewayId" HEX 0 1407;
BA_DEF_ BO_  "EventRateOfChange" INT 10 10000;
BA_DEF_ BO_  "GenMsgStartDelayTime" INT 0 10000;
BA_DEF_ BO_  "GenMsgNrOfRepetition" INT 0 100;
BA_DEF_ BO_  "GenMsgDelayTime" INT 0 1000;
BA_DEF_ BO_  "GenMsgCycleTime" INT 0 100000;
BA_DEF_ BO_  "GenMsgSendType" ENUM  "FixedPeriodic","Event","EnabledPeriodic","NotUsed","NotUsed","EventPeriodic","NotUsed","NotUsed","NoMsgSendType";
BA_DEF_ SG_  "U_CD764_MY2022_Tx" ENUM  "No","Yes";
BA_DEF_ SG_  "U_U55X_MY2022_Tx" ENUM  "No","Yes";
BA_DEF_ SG_  "U_CD542_MY2021_Tx" ENUM  "No","Yes";
BA_DEF_ SG_  "ECGUsedTxSignal" ENUM  "No","Yes";
BA_DEF_ SG_  "U_T6_MCA_MY2020_Tx" ENUM  "No","Yes";
BA_DEF_ SG_  "U_P702_MY2021_Tx" ENUM  "No","Yes";
BA_DEF_ SG_  "U_CX727_MY2021_Tx" ENUM  "No","Yes";
BA_DEF_ SG_  "U_CD764_MY2022_Rx" ENUM  "No","Yes";
BA_DEF_ SG_  "U_FNV2_IVI_Rx" ENUM  "No","Yes";
BA_DEF_ SG_  "U_U55X_MY2022_Rx" ENUM  "No","Yes";
BA_DEF_ SG_  "U_CD542_MY2021_Rx" ENUM  "No","Yes";
BA_DEF_ SG_  "ECGUsedRxSignal" ENUM  "No","Yes";
BA_DEF_ SG_  "U_T6_MCA_MY2020_Rx" ENUM  "No","Yes";
BA_DEF_ SG_  "U_P702_MY2021_Rx" ENUM  "No","Yes";
BA_DEF_ SG_  "U_CX727_MY2021_Rx" ENUM  "No","Yes";
BA_DEF_ SG_  "GenSigStartValue" HEX 0 268435455;
BA_DEF_ SG_  "MetaData" ENUM  "No","Yes";
BA_DEF_ SG_  "ContentDependant" ENUM  "No","Yes";
BA_DEF_ SG_  "GenSigStartValueInteger" INT 0 1000000000;
BA_DEF_ SG_  "UsedOnPgmDBC" ENUM  "No","Yes";
BA_DEF_ SG_  "WakeupSignal" ENUM  "No","Yes";
BA_DEF_ SG_  "GenSigInactiveValue" INT 0 100000;
BA_DEF_ SG_  "GenSigSendType" ENUM  "Cyclic","OnWrite","vector_leerstring","OnChange","vector_leerstring","IfActive","vector_leerstring","NoSigSendType";
BA_DEF_ BO_  "OvtpPushApplication" ENUM  "FALSE","TRUE";
BA_DEF_ BO_  "SCP_FreshnessValueLength" INT 0 512;
BA_DEF_ BO_  "SCP_FreshnessValueTxLength" INT 0 512;
BA_DEF_ BO_  "SCP_AuthInfoTxLength" INT 0 512;
BA_DEF_ BO_  "GenMsgRoutingTimeoutTime" INT 0 5000;
BA_DEF_ BO_  "MessageGateway" ENUM  "No","Yes";
BA_DEF_ BO_  "NmAsrMessage" ENUM  "No","Yes";
BA_DEF_ BO_  "DiagState" ENUM  "No","Yes";
BA_DEF_ BO_  "TpTxIndex" INT 0 536870911;
BA_DEF_ BO_  "DiagRequest" ENUM  "No","Yes";
BA_DEF_ BO_  "DiagResponse" ENUM  "No","Yes";
BA_DEF_ BO_  "GenMsgILSupport" ENUM  "No","Yes";
BA_DEF_DEF_  "FrameRouting" "";
BA_DEF_DEF_  "FrameGatewayNetwork" "NONE";
BA_DEF_DEF_  "NetworkInitialization" "Yes";
BA_DEF_DEF_  "FrameGatewayId" 0;
BA_DEF_DEF_  "EventRateOfChange" 10000;
BA_DEF_DEF_  "GenMsgStartDelayTime" 0;
BA_DEF_DEF_  "GenMsgNrOfRepetition" 1;
BA_DEF_DEF_  "GenMsgDelayTime" 20;
BA_DEF_DEF_  "GenMsgCycleTime" 0;
BA_DEF_DEF_  "GenMsgSendType" "NoMsgSendType";
BA_DEF_DEF_  "U_CD764_MY2022_Tx" "No";
BA_DEF_DEF_  "U_U55X_MY2022_Tx" "No";
BA_DEF_DEF_  "U_CD542_MY2021_Tx" "No";
BA_DEF_DEF_  "ECGUsedTxSignal" "No";
BA_DEF_DEF_  "U_T6_MCA_MY2020_Tx" "No";
BA_DEF_DEF_  "U_P702_MY2021_Tx" "No";
BA_DEF_DEF_  "U_CX727_MY2021_Tx" "No";
BA_DEF_DEF_  "U_CD764_MY2022_Rx" "No";
BA_DEF_DEF_  "U_FNV2_IVI_Rx" "No";
BA_DEF_DEF_  "U_U55X_MY2022_Rx" "No";
BA_DEF_DEF_  "U_CD542_MY2021_Rx" "No";
BA_DEF_DEF_  "ECGUsedRxSignal" "No";
BA_DEF_DEF_  "U_T6_MCA_MY2020_Rx" "No";
BA_DEF_DEF_  "U_P702_MY2021_Rx" "No";
BA_DEF_DEF_  "U_CX727_MY2021_Rx" "No";
BA_DEF_DEF_  "GenSigStartValue" 0;
BA_DEF_DEF_  "MetaData" "No";
BA_DEF_DEF_  "ContentDependant" "No";
BA_DEF_DEF_  "GenSigStartValueInteger" 0;
BA_DEF_DEF_  "UsedOnPgmDBC" "Yes";
BA_DEF_DEF_  "WakeupSignal" "No";
BA_DEF_DEF_  "GenSigInactiveValue" 0;
BA_DEF_DEF_  "GenSigSendType" "NoSigSendType";
BA_DEF_DEF_  "OvtpPushApplication" "FALSE";
BA_DEF_DEF_  "SCP_FreshnessValueLength" 64;
BA_DEF_DEF_  "SCP_FreshnessValueTxLength" 11;
BA_DEF_DEF_  "SCP_AuthInfoTxLength" 53;
BA_DEF_DEF_  "GenMsgRoutingTimeoutTime" 0;
BA_DEF_DEF_  "MessageGateway" "No";
BA_DEF_DEF_  "NmAsrMessage" "No";
BA_DEF_DEF_  "DiagState" "No";
BA_DEF_DEF_  "TpTxIndex" 0;
BA_DEF_DEF_  "DiagRequest" "No";
BA_DEF_DEF_  "DiagResponse" "No";
BA_DEF_DEF_  "GenMsgILSupport" "Yes";
BA_ "FrameRouting" BO_ 965 "MS1_CAN,0x3C5;";
BA_ "FrameGatewayNetwork" BO_ 965 "MS1_CAN";
BA_ "FrameGatewayId" BO_ 965 965;
BA_ "FrameRouting" BO_ 1104 "FD1_CAN,0x450;";
BA_ "FrameGatewayNetwork" BO_ 1104 "FD1_CAN";
BA_ "FrameGatewayId" BO_ 1104 1104;
BA_ "FrameRouting" BO_ 773 "MS1_CAN,0x305;";
BA_ "FrameGatewayNetwork" BO_ 773 "MS1_CAN";
BA_ "FrameGatewayId" BO_ 773 773;
BA_ "FrameRouting" BO_ 303 "HS1_CAN,0x12F";
BA_ "FrameGatewayNetwork" BO_ 303 "HS1_CAN";
BA_ "FrameGatewayId" BO_ 303 303;
BA_ "FrameRouting" BO_ 302 "MS1_CAN,0x12E;";
BA_ "FrameGatewayNetwork" BO_ 302 "MS1_CAN";
BA_ "FrameGatewayId" BO_ 302 302;
BA_ "GenMsgDelayTime" BO_ 2612009176 0;
BA_ "GenMsgSendType" BO_ 2612009176 1;
BA_ "OvtpPushApplication" BO_ 2612009176 1;
BA_ "TpTxIndex" BO_ 2612009176 464525528;
BA_ "FrameRouting" BO_ 571 "FD1_CAN,0x23B;";
BA_ "FrameGatewayNetwork" BO_ 571 "FD1_CAN";
BA_ "FrameGatewayId" BO_ 571 571;
BA_ "FrameRouting" BO_ 781 "MS2_CAN,0x30D;";
BA_ "FrameGatewayNetwork" BO_ 781 "MS2_CAN";
BA_ "FrameGatewayId" BO_ 781 781;
BA_ "TpTxIndex" BO_ 1188 55;
BA_ "GenMsgCycleTime" BO_ 746 1000;
BA_ "GenMsgSendType" BO_ 746 5;
BA_ "GenMsgSendType" BO_ 479 1;
BA_ "GenMsgSendType" BO_ 474 1;
BA_ "GenMsgSendType" BO_ 477 1;
BA_ "GenMsgSendType" BO_ 260 1;
BA_ "GenMsgSendType" BO_ 476 1;
BA_ "GenMsgSendType" BO_ 490 1;
BA_ "FrameRouting" BO_ 1001 "HS2_CAN,0x3E9;";
BA_ "FrameGatewayNetwork" BO_ 1001 "HS2_CAN";
BA_ "FrameGatewayId" BO_ 1001 1001;
BA_ "NetworkInitialization" BO_ 1916 0;
BA_ "GenMsgDelayTime" BO_ 1916 0;
BA_ "GenMsgSendType" BO_ 1916 1;
BA_ "DiagResponse" BO_ 1916 1;
BA_ "GenMsgILSupport" BO_ 1916 0;
BA_ "NetworkInitialization" BO_ 1908 0;
BA_ "GenMsgDelayTime" BO_ 1908 0;
BA_ "GenMsgSendType" BO_ 1908 1;
BA_ "DiagRequest" BO_ 1908 1;
BA_ "GenMsgILSupport" BO_ 1908 0;
BA_ "NetworkInitialization" BO_ 1432 0;
BA_ "GenMsgCycleTime" BO_ 1432 1000;
BA_ "GenMsgSendType" BO_ 1432 0;
BA_ "NmAsrMessage" BO_ 1432 1;
BA_ "GenMsgILSupport" BO_ 1432 0;
BA_ "NetworkInitialization" BO_ 1923 0;
BA_ "GenMsgDelayTime" BO_ 1923 0;
BA_ "GenMsgSendType" BO_ 1923 1;
BA_ "DiagRequest" BO_ 1923 1;
BA_ "GenMsgILSupport" BO_ 1923 0;
BA_ "NetworkInitialization" BO_ 1931 0;
BA_ "GenMsgDelayTime" BO_ 1931 0;
BA_ "GenMsgSendType" BO_ 1931 1;
BA_ "DiagResponse" BO_ 1931 1;
BA_ "GenMsgILSupport" BO_ 1931 0;
BA_ "NetworkInitialization" BO_ 1478 0;
BA_ "GenMsgCycleTime" BO_ 1478 1000;
BA_ "GenMsgSendType" BO_ 1478 0;
BA_ "NmAsrMessage" BO_ 1478 1;
BA_ "GenMsgILSupport" BO_ 1478 0;
BA_ "GenMsgCycleTime" BO_ 1245 1000;
BA_ "GenMsgSendType" BO_ 1245 5;
BA_ "GenMsgCycleTime" BO_ 1242 1000;
BA_ "GenMsgSendType" BO_ 1242 5;
BA_ "FrameRouting" BO_ 1022 "MS2_CAN,0x3FE;";
BA_ "FrameGatewayNetwork" BO_ 1022 "MS2_CAN";
BA_ "FrameGatewayId" BO_ 1022 1022;
BA_ "FrameRouting" BO_ 1021 "MS2_CAN,0x3FD;";
BA_ "FrameGatewayNetwork" BO_ 1021 "MS2_CAN";
BA_ "FrameGatewayId" BO_ 1021 1021;
BA_ "FrameRouting" BO_ 1018 "MS2_CAN,0x3FA;";
BA_ "FrameGatewayNetwork" BO_ 1018 "MS2_CAN";
BA_ "FrameGatewayId" BO_ 1018 1018;
BA_ "GenMsgSendType" BO_ 502 1;
BA_ "FrameRouting" BO_ 955 "HS1_CAN,0x3BB;";
BA_ "FrameGatewayNetwork" BO_ 955 "HS1_CAN";
BA_ "FrameGatewayId" BO_ 955 955;
BA_ "GenMsgCycleTime" BO_ 1116 1000;
BA_ "GenMsgSendType" BO_ 1116 5;
BA_ "GenMsgCycleTime" BO_ 1113 50;
BA_ "GenMsgSendType" BO_ 1113 0;
BA_ "FrameRouting" BO_ 1255 "FD1_CAN,0x4E7;MS1_CAN,0x4E7";
BA_ "FrameRouting" BO_ 1254 "FD1_CAN,0x4E6;MS1_CAN,0x4E6";
BA_ "FrameRouting" BO_ 1253 "FD1_CAN,0x4E5;MS1_CAN,0x4E5";
BA_ "FrameRouting" BO_ 1252 "FD1_CAN,0x4E4;MS1_CAN,0x4E4";
BA_ "FrameRouting" BO_ 1251 "FD1_CAN,0x4E3;MS1_CAN,0x4E3";
BA_ "FrameRouting" BO_ 1250 "FD1_CAN,0x4E2;MS1_CAN,0x4E2";
BA_ "FrameRouting" BO_ 1249 "FD1_CAN,0x4E1;MS1_CAN,0x4E1";
BA_ "FrameRouting" BO_ 1248 "FD1_CAN,0x4E0;MS1_CAN,0x4E0";
BA_ "GenMsgCycleTime" BO_ 1256 1000;
BA_ "GenMsgSendType" BO_ 1256 5;
BA_ "GenMsgCycleTime" BO_ 529 1000;
BA_ "GenMsgSendType" BO_ 529 5;
BA_ "GenMsgCycleTime" BO_ 642 1000;
BA_ "GenMsgSendType" BO_ 642 5;
BA_ "GenMsgCycleTime" BO_ 893 1000;
BA_ "GenMsgSendType" BO_ 893 0;
BA_ "GenMsgSendType" BO_ 500 1;
BA_ "GenMsgSendType" BO_ 503 1;
BA_ "GenMsgSendType" BO_ 412 1;
BA_ "GenMsgSendType" BO_ 493 1;
BA_ "GenMsgSendType" BO_ 511 1;
BA_ "GenMsgSendType" BO_ 257 1;
BA_ "TpTxIndex" BO_ 713 27;
BA_ "FrameRouting" BO_ 382 "FD1_CAN,0x17E;";
BA_ "FrameGatewayNetwork" BO_ 382 "FD1_CAN";
BA_ "FrameGatewayId" BO_ 382 382;
BA_ "FrameRouting" BO_ 877 "MS1_CAN,0x36D;";
BA_ "FrameGatewayNetwork" BO_ 877 "MS1_CAN";
BA_ "FrameGatewayId" BO_ 877 877;
BA_ "FrameRouting" BO_ 592 "HS4_CAN,0x250";
BA_ "FrameGatewayNetwork" BO_ 592 "HS4_CAN";
BA_ "FrameGatewayId" BO_ 592 592;
BA_ "TpTxIndex" BO_ 592 50;
BA_ "TpTxIndex" BO_ 600 50;
BA_ "TpTxIndex" BO_ 708 33;
BA_ "GenMsgSendType" BO_ 414 1;
BA_ "GenMsgCycleTime" BO_ 1239 1000;
BA_ "GenMsgSendType" BO_ 1239 5;
BA_ "TpTxIndex" BO_ 716 33;
BA_ "FrameRouting" BO_ 1013 "HS1_CAN,0x3F5;";
BA_ "FrameGatewayNetwork" BO_ 1013 "HS1_CAN";
BA_ "FrameGatewayId" BO_ 1013 1013;
BA_ "GenMsgCycleTime" BO_ 641 1000;
BA_ "GenMsgSendType" BO_ 641 5;
BA_ "WakeupSignal" SG_ 965 TrnkFrontEmgcy_D_Stat 1;
BA_ "WakeupSignal" SG_ 965 PtWakeupActv4_B_Rq 1;
BA_ "WakeupSignal" SG_ 965 TrunkFrontRolCd_No_Locl 1;
BA_ "U_U55X_MY2022_Rx" SG_ 965 TrunkFrontOpen_D_Stat 1;
BA_ "U_CD542_MY2021_Rx" SG_ 965 TrunkFrontOpen_D_Stat 1;
BA_ "U_T6_MCA_MY2020_Rx" SG_ 965 TrunkFrontOpen_D_Stat 1;
BA_ "GenSigStartValue" SG_ 965 TrunkFrontOpen_D_Stat 2;
BA_ "WakeupSignal" SG_ 965 TrunkFrontOpen_D_Stat 1;
BA_ "MetaData" SG_ 1104 DrvEngageLevel_No_Cs 1;
BA_ "ContentDependant" SG_ 1104 DrvEngageLevel_No_Cs 1;
BA_ "MetaData" SG_ 1104 DrvEngageLevel_No_Cnt 1;
BA_ "ContentDependant" SG_ 1104 DrvEngageLevel_No_Cnt 1;
BA_ "U_CD764_MY2022_Rx" SG_ 773 SeatScrnPsngrOn_B_Rq 1;
BA_ "U_U55X_MY2022_Rx" SG_ 773 SeatScrnPsngrOn_B_Rq 1;
BA_ "U_CD542_MY2021_Rx" SG_ 773 SeatScrnPsngrOn_B_Rq 1;
BA_ "U_T6_MCA_MY2020_Rx" SG_ 773 SeatScrnPsngrOn_B_Rq 1;
BA_ "U_P702_MY2021_Rx" SG_ 773 SeatScrnPsngrOn_B_Rq 1;
BA_ "MetaData" SG_ 303 CanMsg12F_No_Crc 1;
BA_ "ContentDependant" SG_ 303 CanMsg12F_No_Crc 1;
BA_ "MetaData" SG_ 303 CanMsg12F_No_Cnt 1;
BA_ "ContentDependant" SG_ 303 CanMsg12F_No_Cnt 1;
BA_ "U_CD764_MY2022_Rx" SG_ 303 DrStatHood_D2_Actl 1;
BA_ "WakeupSignal" SG_ 303 DrStatHood_D2_Actl 1;
BA_ "MetaData" SG_ 302 CanMsg12E_No_Crc 1;
BA_ "ContentDependant" SG_ 302 CanMsg12E_No_Crc 1;
BA_ "MetaData" SG_ 302 CanMsg12E_No_Cnt 1;
BA_ "ContentDependant" SG_ 302 CanMsg12E_No_Cnt 1;
BA_ "WakeupSignal" SG_ 302 TrnkFrontRleas_B_Stat 1;
BA_ "U_CD764_MY2022_Tx" SG_ 2612009176 PARSEDPushFcGWM_ECGtoHUD 1;
BA_ "ECGUsedTxSignal" SG_ 2612009176 PARSEDPushFcGWM_ECGtoHUD 1;
BA_ "U_CD764_MY2022_Rx" SG_ 2612009176 PARSEDPushFcGWM_ECGtoHUD 1;
BA_ "GenSigSendType" SG_ 2612009176 PARSEDPushFcGWM_ECGtoHUD 3;
BA_ "GenSigStartValue" SG_ 571 VehFalr_Pc_Est 126;
BA_ "GenSigStartValue" SG_ 571 TrlrTngLoad_Pc_Est 126;
BA_ "GenSigStartValue" SG_ 571 TrlrTngLoad_M_Est 2046;
BA_ "GenSigStartValue" SG_ 571 VehPayloadAdd_M_Est 2046;
BA_ "GenSigStartValue" SG_ 571 VehPayload_Pc_Est 126;
BA_ "GenSigStartValue" SG_ 571 VehPayload_M_Est 1022;
BA_ "U_CD764_MY2022_Rx" SG_ 1188 OPTIN_MC_WORD_Rx 1;
BA_ "ECGUsedRxSignal" SG_ 1188 OPTIN_MC_WORD_Rx 1;
BA_ "U_T6_MCA_MY2020_Tx" SG_ 746 Con_BTAud_Shuffle_St 1;
BA_ "U_CD542_MY2021_Rx" SG_ 746 Con_BTAud_Shuffle_St 1;
BA_ "U_T6_MCA_MY2020_Rx" SG_ 746 Con_BTAud_Shuffle_St 1;
BA_ "GenSigSendType" SG_ 746 Con_BTAud_Shuffle_St 3;
BA_ "U_T6_MCA_MY2020_Tx" SG_ 746 Con_BTAud_Repeat_St 1;
BA_ "U_CD542_MY2021_Rx" SG_ 746 Con_BTAud_Repeat_St 1;
BA_ "U_T6_MCA_MY2020_Rx" SG_ 746 Con_BTAud_Repeat_St 1;
BA_ "GenSigSendType" SG_ 746 Con_BTAud_Repeat_St 3;
BA_ "U_T6_MCA_MY2020_Tx" SG_ 746 Con_BTAud_IntroScan_St 1;
BA_ "U_CD542_MY2021_Rx" SG_ 746 Con_BTAud_IntroScan_St 1;
BA_ "U_T6_MCA_MY2020_Rx" SG_ 746 Con_BTAud_IntroScan_St 1;
BA_ "GenSigSendType" SG_ 746 Con_BTAud_IntroScan_St 3;
BA_ "U_T6_MCA_MY2020_Tx" SG_ 746 Con_BTAud_ActTrNum1_St 1;
BA_ "U_CD542_MY2021_Rx" SG_ 746 Con_BTAud_ActTrNum1_St 1;
BA_ "U_T6_MCA_MY2020_Rx" SG_ 746 Con_BTAud_ActTrNum1_St 1;
BA_ "GenSigSendType" SG_ 746 Con_BTAud_ActTrNum1_St 3;
BA_ "U_T6_MCA_MY2020_Tx" SG_ 746 Con_ShowBTPINNumb_St 1;
BA_ "U_CD542_MY2021_Rx" SG_ 746 Con_ShowBTPINNumb_St 1;
BA_ "U_T6_MCA_MY2020_Rx" SG_ 746 Con_ShowBTPINNumb_St 1;
BA_ "GenSigSendType" SG_ 746 Con_ShowBTPINNumb_St 3;
BA_ "U_T6_MCA_MY2020_Tx" SG_ 746 Con_BTAud_Error_St 1;
BA_ "U_CD542_MY2021_Rx" SG_ 746 Con_BTAud_Error_St 1;
BA_ "U_T6_MCA_MY2020_Rx" SG_ 746 Con_BTAud_Error_St 1;
BA_ "GenSigSendType" SG_ 746 Con_BTAud_Error_St 3;
BA_ "U_T6_MCA_MY2020_Tx" SG_ 746 Con_BTAud_FunctStats_St 1;
BA_ "U_CD542_MY2021_Rx" SG_ 746 Con_BTAud_FunctStats_St 1;
BA_ "U_T6_MCA_MY2020_Rx" SG_ 746 Con_BTAud_FunctStats_St 1;
BA_ "GenSigSendType" SG_ 746 Con_BTAud_FunctStats_St 3;
BA_ "U_T6_MCA_MY2020_Tx" SG_ 746 Con_BTAud_OpMode_St 1;
BA_ "U_CD542_MY2021_Rx" SG_ 746 Con_BTAud_OpMode_St 1;
BA_ "U_T6_MCA_MY2020_Rx" SG_ 746 Con_BTAud_OpMode_St 1;
BA_ "GenSigSendType" SG_ 746 Con_BTAud_OpMode_St 3;
BA_ "U_CD764_MY2022_Tx" SG_ 479 DISP_SetVolume_Rq 1;
BA_ "U_U55X_MY2022_Tx" SG_ 479 DISP_SetVolume_Rq 1;
BA_ "U_CD542_MY2021_Tx" SG_ 479 DISP_SetVolume_Rq 1;
BA_ "U_T6_MCA_MY2020_Tx" SG_ 479 DISP_SetVolume_Rq 1;
BA_ "U_P702_MY2021_Tx" SG_ 479 DISP_SetVolume_Rq 1;
BA_ "U_CD764_MY2022_Rx" SG_ 479 DISP_SetVolume_Rq 1;
BA_ "U_U55X_MY2022_Rx" SG_ 479 DISP_SetVolume_Rq 1;
BA_ "U_CD542_MY2021_Rx" SG_ 479 DISP_SetVolume_Rq 1;
BA_ "U_T6_MCA_MY2020_Rx" SG_ 479 DISP_SetVolume_Rq 1;
BA_ "U_P702_MY2021_Rx" SG_ 479 DISP_SetVolume_Rq 1;
BA_ "GenSigSendType" SG_ 479 DISP_SetVolume_Rq 3;
BA_ "GenSigStartValue" SG_ 479 DISP_SetVolume_Rq 30;
BA_ "GenSigStartValueInteger" SG_ 479 DISP_SetVolume_Rq 30;
BA_ "U_CD764_MY2022_Tx" SG_ 479 DISP_SetVol_Source_Rq 1;
BA_ "U_U55X_MY2022_Tx" SG_ 479 DISP_SetVol_Source_Rq 1;
BA_ "U_CD542_MY2021_Tx" SG_ 479 DISP_SetVol_Source_Rq 1;
BA_ "U_T6_MCA_MY2020_Tx" SG_ 479 DISP_SetVol_Source_Rq 1;
BA_ "U_P702_MY2021_Tx" SG_ 479 DISP_SetVol_Source_Rq 1;
BA_ "U_P702_MY2021_Rx" SG_ 479 DISP_SetVol_Source_Rq 1;
BA_ "U_CD764_MY2022_Rx" SG_ 479 DISP_SetVol_Source_Rq 1;
BA_ "U_U55X_MY2022_Rx" SG_ 479 DISP_SetVol_Source_Rq 1;
BA_ "U_CD542_MY2021_Rx" SG_ 479 DISP_SetVol_Source_Rq 1;
BA_ "U_T6_MCA_MY2020_Rx" SG_ 479 DISP_SetVol_Source_Rq 1;
BA_ "GenSigSendType" SG_ 479 DISP_SetVol_Source_Rq 3;
BA_ "U_CD764_MY2022_Tx" SG_ 479 DISP_SetVol_Level_Rq 1;
BA_ "U_U55X_MY2022_Tx" SG_ 479 DISP_SetVol_Level_Rq 1;
BA_ "U_CD542_MY2021_Tx" SG_ 479 DISP_SetVol_Level_Rq 1;
BA_ "U_T6_MCA_MY2020_Tx" SG_ 479 DISP_SetVol_Level_Rq 1;
BA_ "U_P702_MY2021_Tx" SG_ 479 DISP_SetVol_Level_Rq 1;
BA_ "U_P702_MY2021_Rx" SG_ 479 DISP_SetVol_Level_Rq 1;
BA_ "U_CD764_MY2022_Rx" SG_ 479 DISP_SetVol_Level_Rq 1;
BA_ "U_U55X_MY2022_Rx" SG_ 479 DISP_SetVol_Level_Rq 1;
BA_ "U_CD542_MY2021_Rx" SG_ 479 DISP_SetVol_Level_Rq 1;
BA_ "U_T6_MCA_MY2020_Rx" SG_ 479 DISP_SetVol_Level_Rq 1;
BA_ "U_U55X_MY2022_Tx" SG_ 479 DISP_Setshaker_Rq 1;
BA_ "U_CD542_MY2021_Tx" SG_ 479 DISP_Setshaker_Rq 1;
BA_ "U_T6_MCA_MY2020_Tx" SG_ 479 DISP_Setshaker_Rq 1;
BA_ "U_P702_MY2021_Tx" SG_ 479 DISP_Setshaker_Rq 1;
BA_ "U_P702_MY2021_Rx" SG_ 479 DISP_Setshaker_Rq 1;
BA_ "U_T6_MCA_MY2020_Rx" SG_ 479 DISP_Setshaker_Rq 1;
BA_ "GenSigSendType" SG_ 479 DISP_Setshaker_Rq 3;
BA_ "U_U55X_MY2022_Tx" SG_ 474 Nav_SetCurrStatMCCh_Rq 1;
BA_ "U_CD542_MY2021_Tx" SG_ 474 Nav_SetCurrStatMCCh_Rq 1;
BA_ "U_T6_MCA_MY2020_Tx" SG_ 474 Nav_SetCurrStatMCCh_Rq 1;
BA_ "U_P702_MY2021_Tx" SG_ 474 Nav_SetCurrStatMCCh_Rq 1;
BA_ "U_U55X_MY2022_Rx" SG_ 474 Nav_SetCurrStatMCCh_Rq 1;
BA_ "U_CD542_MY2021_Rx" SG_ 474 Nav_SetCurrStatMCCh_Rq 1;
BA_ "U_T6_MCA_MY2020_Rx" SG_ 474 Nav_SetCurrStatMCCh_Rq 1;
BA_ "U_P702_MY2021_Rx" SG_ 474 Nav_SetCurrStatMCCh_Rq 1;
BA_ "U_U55X_MY2022_Tx" SG_ 474 NAV_SetNEWSMode_Rq 1;
BA_ "U_CD542_MY2021_Tx" SG_ 474 NAV_SetNEWSMode_Rq 1;
BA_ "U_T6_MCA_MY2020_Tx" SG_ 474 NAV_SetNEWSMode_Rq 1;
BA_ "U_P702_MY2021_Tx" SG_ 474 NAV_SetNEWSMode_Rq 1;
BA_ "U_U55X_MY2022_Rx" SG_ 474 NAV_SetNEWSMode_Rq 1;
BA_ "U_CD542_MY2021_Rx" SG_ 474 NAV_SetNEWSMode_Rq 1;
BA_ "U_T6_MCA_MY2020_Rx" SG_ 474 NAV_SetNEWSMode_Rq 1;
BA_ "U_P702_MY2021_Rx" SG_ 474 NAV_SetNEWSMode_Rq 1;
BA_ "GenSigSendType" SG_ 474 NAV_SetNEWSMode_Rq 3;
BA_ "U_CD764_MY2022_Tx" SG_ 474 NAV_SetMid_Rq 1;
BA_ "U_U55X_MY2022_Tx" SG_ 474 NAV_SetMid_Rq 1;
BA_ "U_CD542_MY2021_Tx" SG_ 474 NAV_SetMid_Rq 1;
BA_ "U_T6_MCA_MY2020_Tx" SG_ 474 NAV_SetMid_Rq 1;
BA_ "U_P702_MY2021_Tx" SG_ 474 NAV_SetMid_Rq 1;
BA_ "U_P702_MY2021_Rx" SG_ 474 NAV_SetMid_Rq 1;
BA_ "U_CD764_MY2022_Rx" SG_ 474 NAV_SetMid_Rq 1;
BA_ "U_U55X_MY2022_Rx" SG_ 474 NAV_SetMid_Rq 1;
BA_ "U_CD542_MY2021_Rx" SG_ 474 NAV_SetMid_Rq 1;
BA_ "U_T6_MCA_MY2020_Rx" SG_ 474 NAV_SetMid_Rq 1;
BA_ "GenSigSendType" SG_ 474 NAV_SetMid_Rq 3;
BA_ "GenSigStartValue" SG_ 474 NAV_SetMid_Rq 15;
BA_ "U_CD764_MY2022_Tx" SG_ 474 NAV_SetDSP_Rq 1;
BA_ "U_U55X_MY2022_Tx" SG_ 474 NAV_SetDSP_Rq 1;
BA_ "U_CD542_MY2021_Tx" SG_ 474 NAV_SetDSP_Rq 1;
BA_ "U_T6_MCA_MY2020_Tx" SG_ 474 NAV_SetDSP_Rq 1;
BA_ "U_P702_MY2021_Tx" SG_ 474 NAV_SetDSP_Rq 1;
BA_ "U_U55X_MY2022_Rx" SG_ 474 NAV_SetDSP_Rq 1;
BA_ "U_CD542_MY2021_Rx" SG_ 474 NAV_SetDSP_Rq 1;
BA_ "U_T6_MCA_MY2020_Rx" SG_ 474 NAV_SetDSP_Rq 1;
BA_ "U_P702_MY2021_Rx" SG_ 474 NAV_SetDSP_Rq 1;
BA_ "GenSigSendType" SG_ 474 NAV_SetDSP_Rq 3;
BA_ "U_U55X_MY2022_Tx" SG_ 474 NAV_SetCurrStatFreq_Rq 1;
BA_ "U_CD542_MY2021_Tx" SG_ 474 NAV_SetCurrStatFreq_Rq 1;
BA_ "U_T6_MCA_MY2020_Tx" SG_ 474 NAV_SetCurrStatFreq_Rq 1;
BA_ "U_P702_MY2021_Tx" SG_ 474 NAV_SetCurrStatFreq_Rq 1;
BA_ "U_U55X_MY2022_Rx" SG_ 474 NAV_SetCurrStatFreq_Rq 1;
BA_ "U_T6_MCA_MY2020_Rx" SG_ 474 NAV_SetCurrStatFreq_Rq 1;
BA_ "U_P702_MY2021_Rx" SG_ 474 NAV_SetCurrStatFreq_Rq 1;
BA_ "U_U55X_MY2022_Tx" SG_ 474 NAV_SetCurrentStatOp_Rq 1;
BA_ "U_CD542_MY2021_Tx" SG_ 474 NAV_SetCurrentStatOp_Rq 1;
BA_ "U_T6_MCA_MY2020_Tx" SG_ 474 NAV_SetCurrentStatOp_Rq 1;
BA_ "U_P702_MY2021_Tx" SG_ 474 NAV_SetCurrentStatOp_Rq 1;
BA_ "U_U55X_MY2022_Rx" SG_ 474 NAV_SetCurrentStatOp_Rq 1;
BA_ "U_CD542_MY2021_Rx" SG_ 474 NAV_SetCurrentStatOp_Rq 1;
BA_ "U_T6_MCA_MY2020_Rx" SG_ 474 NAV_SetCurrentStatOp_Rq 1;
BA_ "U_P702_MY2021_Rx" SG_ 474 NAV_SetCurrentStatOp_Rq 1;
BA_ "GenSigSendType" SG_ 474 NAV_SetCurrentStatOp_Rq 3;
BA_ "U_U55X_MY2022_Tx" SG_ 474 NAV_SetCurrentPICode_Rq 1;
BA_ "U_CD542_MY2021_Tx" SG_ 474 NAV_SetCurrentPICode_Rq 1;
BA_ "U_T6_MCA_MY2020_Tx" SG_ 474 NAV_SetCurrentPICode_Rq 1;
BA_ "U_P702_MY2021_Tx" SG_ 474 NAV_SetCurrentPICode_Rq 1;
BA_ "U_U55X_MY2022_Rx" SG_ 474 NAV_SetCurrentPICode_Rq 1;
BA_ "U_CD542_MY2021_Rx" SG_ 474 NAV_SetCurrentPICode_Rq 1;
BA_ "U_T6_MCA_MY2020_Rx" SG_ 474 NAV_SetCurrentPICode_Rq 1;
BA_ "U_P702_MY2021_Rx" SG_ 474 NAV_SetCurrentPICode_Rq 1;
BA_ "U_CD764_MY2022_Tx" SG_ 474 NAV_ARReqstrSystem_Rq 1;
BA_ "U_U55X_MY2022_Tx" SG_ 474 NAV_ARReqstrSystem_Rq 1;
BA_ "U_CD542_MY2021_Tx" SG_ 474 NAV_ARReqstrSystem_Rq 1;
BA_ "U_T6_MCA_MY2020_Tx" SG_ 474 NAV_ARReqstrSystem_Rq 1;
BA_ "U_P702_MY2021_Tx" SG_ 474 NAV_ARReqstrSystem_Rq 1;
BA_ "U_U55X_MY2022_Rx" SG_ 474 NAV_ARReqstrSystem_Rq 1;
BA_ "U_P702_MY2021_Rx" SG_ 474 NAV_ARReqstrSystem_Rq 1;
BA_ "U_CD764_MY2022_Rx" SG_ 474 NAV_ARReqstrSystem_Rq 1;
BA_ "U_CD542_MY2021_Rx" SG_ 474 NAV_ARReqstrSystem_Rq 1;
BA_ "U_T6_MCA_MY2020_Rx" SG_ 474 NAV_ARReqstrSystem_Rq 1;
BA_ "U_CD764_MY2022_Tx" SG_ 474 NAV_ARReqstrPriority_Rq 1;
BA_ "U_U55X_MY2022_Tx" SG_ 474 NAV_ARReqstrPriority_Rq 1;
BA_ "U_CD542_MY2021_Tx" SG_ 474 NAV_ARReqstrPriority_Rq 1;
BA_ "U_T6_MCA_MY2020_Tx" SG_ 474 NAV_ARReqstrPriority_Rq 1;
BA_ "U_P702_MY2021_Tx" SG_ 474 NAV_ARReqstrPriority_Rq 1;
BA_ "U_U55X_MY2022_Rx" SG_ 474 NAV_ARReqstrPriority_Rq 1;
BA_ "U_P702_MY2021_Rx" SG_ 474 NAV_ARReqstrPriority_Rq 1;
BA_ "U_CD764_MY2022_Rx" SG_ 474 NAV_ARReqstrPriority_Rq 1;
BA_ "U_CD542_MY2021_Rx" SG_ 474 NAV_ARReqstrPriority_Rq 1;
BA_ "U_T6_MCA_MY2020_Rx" SG_ 474 NAV_ARReqstrPriority_Rq 1;
BA_ "U_CD764_MY2022_Tx" SG_ 474 NAV_AROperationType_Rq 1;
BA_ "U_U55X_MY2022_Tx" SG_ 474 NAV_AROperationType_Rq 1;
BA_ "U_CD542_MY2021_Tx" SG_ 474 NAV_AROperationType_Rq 1;
BA_ "U_T6_MCA_MY2020_Tx" SG_ 474 NAV_AROperationType_Rq 1;
BA_ "U_P702_MY2021_Tx" SG_ 474 NAV_AROperationType_Rq 1;
BA_ "U_U55X_MY2022_Rx" SG_ 474 NAV_AROperationType_Rq 1;
BA_ "U_P702_MY2021_Rx" SG_ 474 NAV_AROperationType_Rq 1;
BA_ "U_CD764_MY2022_Rx" SG_ 474 NAV_AROperationType_Rq 1;
BA_ "U_CD542_MY2021_Rx" SG_ 474 NAV_AROperationType_Rq 1;
BA_ "U_T6_MCA_MY2020_Rx" SG_ 474 NAV_AROperationType_Rq 1;
BA_ "GenSigSendType" SG_ 474 NAV_AROperationType_Rq 3;
BA_ "U_CD764_MY2022_Tx" SG_ 474 NAV_ARAudioSource_Rq 1;
BA_ "U_U55X_MY2022_Tx" SG_ 474 NAV_ARAudioSource_Rq 1;
BA_ "U_CD542_MY2021_Tx" SG_ 474 NAV_ARAudioSource_Rq 1;
BA_ "U_T6_MCA_MY2020_Tx" SG_ 474 NAV_ARAudioSource_Rq 1;
BA_ "U_P702_MY2021_Tx" SG_ 474 NAV_ARAudioSource_Rq 1;
BA_ "U_U55X_MY2022_Rx" SG_ 474 NAV_ARAudioSource_Rq 1;
BA_ "U_P702_MY2021_Rx" SG_ 474 NAV_ARAudioSource_Rq 1;
BA_ "U_CD764_MY2022_Rx" SG_ 474 NAV_ARAudioSource_Rq 1;
BA_ "U_CD542_MY2021_Rx" SG_ 474 NAV_ARAudioSource_Rq 1;
BA_ "U_T6_MCA_MY2020_Rx" SG_ 474 NAV_ARAudioSource_Rq 1;
BA_ "U_CD764_MY2022_Tx" SG_ 477 NAV_SetTreble_Rq 1;
BA_ "U_U55X_MY2022_Tx" SG_ 477 NAV_SetTreble_Rq 1;
BA_ "U_CD542_MY2021_Tx" SG_ 477 NAV_SetTreble_Rq 1;
BA_ "U_T6_MCA_MY2020_Tx" SG_ 477 NAV_SetTreble_Rq 1;
BA_ "U_CD764_MY2022_Rx" SG_ 477 NAV_SetTreble_Rq 1;
BA_ "U_U55X_MY2022_Rx" SG_ 477 NAV_SetTreble_Rq 1;
BA_ "U_CD542_MY2021_Rx" SG_ 477 NAV_SetTreble_Rq 1;
BA_ "U_T6_MCA_MY2020_Rx" SG_ 477 NAV_SetTreble_Rq 1;
BA_ "GenSigSendType" SG_ 477 NAV_SetTreble_Rq 3;
BA_ "GenSigStartValue" SG_ 477 NAV_SetTreble_Rq 15;
BA_ "U_CD764_MY2022_Tx" SG_ 477 NAV_SetFader_Rq 1;
BA_ "U_U55X_MY2022_Tx" SG_ 477 NAV_SetFader_Rq 1;
BA_ "U_CD542_MY2021_Tx" SG_ 477 NAV_SetFader_Rq 1;
BA_ "U_T6_MCA_MY2020_Tx" SG_ 477 NAV_SetFader_Rq 1;
BA_ "U_CD764_MY2022_Rx" SG_ 477 NAV_SetFader_Rq 1;
BA_ "U_U55X_MY2022_Rx" SG_ 477 NAV_SetFader_Rq 1;
BA_ "U_CD542_MY2021_Rx" SG_ 477 NAV_SetFader_Rq 1;
BA_ "U_T6_MCA_MY2020_Rx" SG_ 477 NAV_SetFader_Rq 1;
BA_ "GenSigSendType" SG_ 477 NAV_SetFader_Rq 3;
BA_ "GenSigStartValue" SG_ 477 NAV_SetFader_Rq 15;
BA_ "U_CD764_MY2022_Tx" SG_ 477 NAV_SetBass_Rq 1;
BA_ "U_U55X_MY2022_Tx" SG_ 477 NAV_SetBass_Rq 1;
BA_ "U_CD542_MY2021_Tx" SG_ 477 NAV_SetBass_Rq 1;
BA_ "U_T6_MCA_MY2020_Tx" SG_ 477 NAV_SetBass_Rq 1;
BA_ "U_CD764_MY2022_Rx" SG_ 477 NAV_SetBass_Rq 1;
BA_ "U_U55X_MY2022_Rx" SG_ 477 NAV_SetBass_Rq 1;
BA_ "U_CD542_MY2021_Rx" SG_ 477 NAV_SetBass_Rq 1;
BA_ "U_T6_MCA_MY2020_Rx" SG_ 477 NAV_SetBass_Rq 1;
BA_ "GenSigSendType" SG_ 477 NAV_SetBass_Rq 3;
BA_ "GenSigStartValue" SG_ 477 NAV_SetBass_Rq 15;
BA_ "U_CD764_MY2022_Tx" SG_ 477 NAV_SetBalance_Rq 1;
BA_ "U_U55X_MY2022_Tx" SG_ 477 NAV_SetBalance_Rq 1;
BA_ "U_CD542_MY2021_Tx" SG_ 477 NAV_SetBalance_Rq 1;
BA_ "U_T6_MCA_MY2020_Tx" SG_ 477 NAV_SetBalance_Rq 1;
BA_ "U_CD764_MY2022_Rx" SG_ 477 NAV_SetBalance_Rq 1;
BA_ "U_U55X_MY2022_Rx" SG_ 477 NAV_SetBalance_Rq 1;
BA_ "U_CD542_MY2021_Rx" SG_ 477 NAV_SetBalance_Rq 1;
BA_ "U_T6_MCA_MY2020_Rx" SG_ 477 NAV_SetBalance_Rq 1;
BA_ "GenSigSendType" SG_ 477 NAV_SetBalance_Rq 3;
BA_ "GenSigStartValue" SG_ 477 NAV_SetBalance_Rq 15;
BA_ "U_CD764_MY2022_Tx" SG_ 477 NAV_SetAVC_Rq 1;
BA_ "U_U55X_MY2022_Tx" SG_ 477 NAV_SetAVC_Rq 1;
BA_ "U_CD542_MY2021_Tx" SG_ 477 NAV_SetAVC_Rq 1;
BA_ "U_T6_MCA_MY2020_Tx" SG_ 477 NAV_SetAVC_Rq 1;
BA_ "U_CD764_MY2022_Rx" SG_ 477 NAV_SetAVC_Rq 1;
BA_ "U_U55X_MY2022_Rx" SG_ 477 NAV_SetAVC_Rq 1;
BA_ "U_CD542_MY2021_Rx" SG_ 477 NAV_SetAVC_Rq 1;
BA_ "U_T6_MCA_MY2020_Rx" SG_ 477 NAV_SetAVC_Rq 1;
BA_ "GenSigSendType" SG_ 477 NAV_SetAVC_Rq 3;
BA_ "GenSigStartValue" SG_ 477 NAV_SetAVC_Rq 15;
BA_ "U_U55X_MY2022_Tx" SG_ 477 NAV_SecurtyPINUnlock_Rq 1;
BA_ "U_CD542_MY2021_Tx" SG_ 477 NAV_SecurtyPINUnlock_Rq 1;
BA_ "U_T6_MCA_MY2020_Tx" SG_ 477 NAV_SecurtyPINUnlock_Rq 1;
BA_ "U_U55X_MY2022_Rx" SG_ 477 NAV_SecurtyPINUnlock_Rq 1;
BA_ "U_T6_MCA_MY2020_Rx" SG_ 477 NAV_SecurtyPINUnlock_Rq 1;
BA_ "GenSigSendType" SG_ 477 NAV_SecurtyPINUnlock_Rq 3;
BA_ "U_U55X_MY2022_Tx" SG_ 477 NAV_LoadEjectMode_Rq 1;
BA_ "U_CD542_MY2021_Tx" SG_ 477 NAV_LoadEjectMode_Rq 1;
BA_ "U_T6_MCA_MY2020_Tx" SG_ 477 NAV_LoadEjectMode_Rq 1;
BA_ "U_U55X_MY2022_Rx" SG_ 477 NAV_LoadEjectMode_Rq 1;
BA_ "U_CD542_MY2021_Rx" SG_ 477 NAV_LoadEjectMode_Rq 1;
BA_ "U_T6_MCA_MY2020_Rx" SG_ 477 NAV_LoadEjectMode_Rq 1;
BA_ "GenSigSendType" SG_ 477 NAV_LoadEjectMode_Rq 3;
BA_ "U_U55X_MY2022_Tx" SG_ 477 NAV_LoadEjectDisc_Rq 1;
BA_ "U_CD542_MY2021_Tx" SG_ 477 NAV_LoadEjectDisc_Rq 1;
BA_ "U_T6_MCA_MY2020_Tx" SG_ 477 NAV_LoadEjectDisc_Rq 1;
BA_ "U_U55X_MY2022_Rx" SG_ 477 NAV_LoadEjectDisc_Rq 1;
BA_ "U_CD542_MY2021_Rx" SG_ 477 NAV_LoadEjectDisc_Rq 1;
BA_ "U_T6_MCA_MY2020_Rx" SG_ 477 NAV_LoadEjectDisc_Rq 1;
BA_ "U_CD764_MY2022_Tx" SG_ 260 MFD_SDARS_SetOpMode_Rq 1;
BA_ "U_U55X_MY2022_Tx" SG_ 260 MFD_SDARS_SetOpMode_Rq 1;
BA_ "U_CD542_MY2021_Tx" SG_ 260 MFD_SDARS_SetOpMode_Rq 1;
BA_ "U_T6_MCA_MY2020_Tx" SG_ 260 MFD_SDARS_SetOpMode_Rq 1;
BA_ "U_P702_MY2021_Tx" SG_ 260 MFD_SDARS_SetOpMode_Rq 1;
BA_ "U_CD542_MY2021_Rx" SG_ 260 MFD_SDARS_SetOpMode_Rq 1;
BA_ "U_T6_MCA_MY2020_Rx" SG_ 260 MFD_SDARS_SetOpMode_Rq 1;
BA_ "U_P702_MY2021_Rx" SG_ 260 MFD_SDARS_SetOpMode_Rq 1;
BA_ "GenSigSendType" SG_ 260 MFD_SDARS_SetOpMode_Rq 3;
BA_ "U_U55X_MY2022_Tx" SG_ 260 MFD_SDARS_DirectTune_Rq 1;
BA_ "U_CD542_MY2021_Tx" SG_ 260 MFD_SDARS_DirectTune_Rq 1;
BA_ "U_T6_MCA_MY2020_Tx" SG_ 260 MFD_SDARS_DirectTune_Rq 1;
BA_ "U_P702_MY2021_Tx" SG_ 260 MFD_SDARS_DirectTune_Rq 1;
BA_ "U_CD542_MY2021_Rx" SG_ 260 MFD_SDARS_DirectTune_Rq 1;
BA_ "U_T6_MCA_MY2020_Rx" SG_ 260 MFD_SDARS_DirectTune_Rq 1;
BA_ "U_P702_MY2021_Rx" SG_ 260 MFD_SDARS_DirectTune_Rq 1;
BA_ "GenSigSendType" SG_ 260 MFD_SDARS_DirectTune_Rq 3;
BA_ "GenSigStartValue" SG_ 260 MFD_SDARS_DirectTune_Rq 255;
BA_ "ContentDependant" SG_ 260 MFD_SDARS_DirectTune_Rq 1;
BA_ "GenSigStartValueInteger" SG_ 260 MFD_SDARS_DirectTune_Rq 255;
BA_ "U_U55X_MY2022_Tx" SG_ 260 SDARS_GetESN_Rq 1;
BA_ "U_CD542_MY2021_Tx" SG_ 260 SDARS_GetESN_Rq 1;
BA_ "U_T6_MCA_MY2020_Tx" SG_ 260 SDARS_GetESN_Rq 1;
BA_ "U_P702_MY2021_Tx" SG_ 260 SDARS_GetESN_Rq 1;
BA_ "U_CD542_MY2021_Rx" SG_ 260 SDARS_GetESN_Rq 1;
BA_ "U_T6_MCA_MY2020_Rx" SG_ 260 SDARS_GetESN_Rq 1;
BA_ "U_P702_MY2021_Rx" SG_ 260 SDARS_GetESN_Rq 1;
BA_ "GenSigSendType" SG_ 260 SDARS_GetESN_Rq 3;
BA_ "U_U55X_MY2022_Tx" SG_ 260 SDARS_SRReplay_Rq 1;
BA_ "U_CD542_MY2021_Tx" SG_ 260 SDARS_SRReplay_Rq 1;
BA_ "U_T6_MCA_MY2020_Tx" SG_ 260 SDARS_SRReplay_Rq 1;
BA_ "U_P702_MY2021_Tx" SG_ 260 SDARS_SRReplay_Rq 1;
BA_ "U_CD542_MY2021_Rx" SG_ 260 SDARS_SRReplay_Rq 1;
BA_ "U_T6_MCA_MY2020_Rx" SG_ 260 SDARS_SRReplay_Rq 1;
BA_ "U_P702_MY2021_Rx" SG_ 260 SDARS_SRReplay_Rq 1;
BA_ "GenSigSendType" SG_ 260 SDARS_SRReplay_Rq 3;
BA_ "U_U55X_MY2022_Tx" SG_ 260 SDARS_SelectCategory_Rq 1;
BA_ "U_CD542_MY2021_Tx" SG_ 260 SDARS_SelectCategory_Rq 1;
BA_ "U_T6_MCA_MY2020_Tx" SG_ 260 SDARS_SelectCategory_Rq 1;
BA_ "U_P702_MY2021_Tx" SG_ 260 SDARS_SelectCategory_Rq 1;
BA_ "U_CD542_MY2021_Rx" SG_ 260 SDARS_SelectCategory_Rq 1;
BA_ "U_T6_MCA_MY2020_Rx" SG_ 260 SDARS_SelectCategory_Rq 1;
BA_ "U_P702_MY2021_Rx" SG_ 260 SDARS_SelectCategory_Rq 1;
BA_ "GenSigSendType" SG_ 260 SDARS_SelectCategory_Rq 3;
BA_ "U_U55X_MY2022_Tx" SG_ 260 SDARS_InfoRefChanNum_Rq 1;
BA_ "U_CD542_MY2021_Tx" SG_ 260 SDARS_InfoRefChanNum_Rq 1;
BA_ "U_T6_MCA_MY2020_Tx" SG_ 260 SDARS_InfoRefChanNum_Rq 1;
BA_ "U_P702_MY2021_Tx" SG_ 260 SDARS_InfoRefChanNum_Rq 1;
BA_ "U_CD542_MY2021_Rx" SG_ 260 SDARS_InfoRefChanNum_Rq 1;
BA_ "U_T6_MCA_MY2020_Rx" SG_ 260 SDARS_InfoRefChanNum_Rq 1;
BA_ "U_P702_MY2021_Rx" SG_ 260 SDARS_InfoRefChanNum_Rq 1;
BA_ "GenSigSendType" SG_ 260 SDARS_InfoRefChanNum_Rq 3;
BA_ "U_CD764_MY2022_Tx" SG_ 260 SDARS_FactoryReset_Rq 1;
BA_ "U_U55X_MY2022_Tx" SG_ 260 SDARS_FactoryReset_Rq 1;
BA_ "U_CD542_MY2021_Tx" SG_ 260 SDARS_FactoryReset_Rq 1;
BA_ "U_T6_MCA_MY2020_Tx" SG_ 260 SDARS_FactoryReset_Rq 1;
BA_ "U_P702_MY2021_Tx" SG_ 260 SDARS_FactoryReset_Rq 1;
BA_ "U_T6_MCA_MY2020_Rx" SG_ 260 SDARS_FactoryReset_Rq 1;
BA_ "U_P702_MY2021_Rx" SG_ 260 SDARS_FactoryReset_Rq 1;
BA_ "U_CD764_MY2022_Rx" SG_ 260 SDARS_FactoryReset_Rq 1;
BA_ "U_U55X_MY2022_Rx" SG_ 260 SDARS_FactoryReset_Rq 1;
BA_ "U_CD542_MY2021_Rx" SG_ 260 SDARS_FactoryReset_Rq 1;
BA_ "GenSigSendType" SG_ 260 SDARS_FactoryReset_Rq 3;
BA_ "U_U55X_MY2022_Tx" SG_ 476 Nav_SetAudioMixRatio_Rq 1;
BA_ "U_CD542_MY2021_Tx" SG_ 476 Nav_SetAudioMixRatio_Rq 1;
BA_ "U_T6_MCA_MY2020_Tx" SG_ 476 Nav_SetAudioMixRatio_Rq 1;
BA_ "U_P702_MY2021_Tx" SG_ 476 Nav_SetAudioMixRatio_Rq 1;
BA_ "U_CD542_MY2021_Rx" SG_ 476 Nav_SetAudioMixRatio_Rq 1;
BA_ "U_T6_MCA_MY2020_Rx" SG_ 476 Nav_SetAudioMixRatio_Rq 1;
BA_ "U_P702_MY2021_Rx" SG_ 476 Nav_SetAudioMixRatio_Rq 1;
BA_ "GenSigSendType" SG_ 476 Nav_SetAudioMixRatio_Rq 3;
BA_ "GenSigStartValue" SG_ 476 Nav_SetAudioMixRatio_Rq 31;
BA_ "GenSigStartValueInteger" SG_ 476 Nav_SetAudioMixRatio_Rq 31;
BA_ "U_U55X_MY2022_Tx" SG_ 476 NAV_SkipCatalouge_Rq 1;
BA_ "U_CD542_MY2021_Tx" SG_ 476 NAV_SkipCatalouge_Rq 1;
BA_ "U_T6_MCA_MY2020_Tx" SG_ 476 NAV_SkipCatalouge_Rq 1;
BA_ "U_P702_MY2021_Tx" SG_ 476 NAV_SkipCatalouge_Rq 1;
BA_ "U_CD542_MY2021_Rx" SG_ 476 NAV_SkipCatalouge_Rq 1;
BA_ "U_T6_MCA_MY2020_Rx" SG_ 476 NAV_SkipCatalouge_Rq 1;
BA_ "U_P702_MY2021_Rx" SG_ 476 NAV_SkipCatalouge_Rq 1;
BA_ "GenSigSendType" SG_ 476 NAV_SkipCatalouge_Rq 3;
BA_ "U_U55X_MY2022_Tx" SG_ 476 NAV_SetOperationMode_Rq 1;
BA_ "U_CD542_MY2021_Tx" SG_ 476 NAV_SetOperationMode_Rq 1;
BA_ "U_T6_MCA_MY2020_Tx" SG_ 476 NAV_SetOperationMode_Rq 1;
BA_ "U_P702_MY2021_Tx" SG_ 476 NAV_SetOperationMode_Rq 1;
BA_ "U_CD542_MY2021_Rx" SG_ 476 NAV_SetOperationMode_Rq 1;
BA_ "U_T6_MCA_MY2020_Rx" SG_ 476 NAV_SetOperationMode_Rq 1;
BA_ "U_P702_MY2021_Rx" SG_ 476 NAV_SetOperationMode_Rq 1;
BA_ "GenSigSendType" SG_ 476 NAV_SetOperationMode_Rq 3;
BA_ "U_U55X_MY2022_Tx" SG_ 476 NAV_SetDSPProgram_Rq 1;
BA_ "U_CD542_MY2021_Tx" SG_ 476 NAV_SetDSPProgram_Rq 1;
BA_ "U_T6_MCA_MY2020_Tx" SG_ 476 NAV_SetDSPProgram_Rq 1;
BA_ "U_P702_MY2021_Tx" SG_ 476 NAV_SetDSPProgram_Rq 1;
BA_ "U_CD542_MY2021_Rx" SG_ 476 NAV_SetDSPProgram_Rq 1;
BA_ "U_T6_MCA_MY2020_Rx" SG_ 476 NAV_SetDSPProgram_Rq 1;
BA_ "U_P702_MY2021_Rx" SG_ 476 NAV_SetDSPProgram_Rq 1;
BA_ "GenSigSendType" SG_ 476 NAV_SetDSPProgram_Rq 3;
BA_ "U_U55X_MY2022_Tx" SG_ 490 HMI_SetCompression_Rq 1;
BA_ "U_CD542_MY2021_Tx" SG_ 490 HMI_SetCompression_Rq 1;
BA_ "U_T6_MCA_MY2020_Tx" SG_ 490 HMI_SetCompression_Rq 1;
BA_ "U_P702_MY2021_Tx" SG_ 490 HMI_SetCompression_Rq 1;
BA_ "U_T6_MCA_MY2020_Rx" SG_ 490 HMI_SetCompression_Rq 1;
BA_ "U_P702_MY2021_Rx" SG_ 490 HMI_SetCompression_Rq 1;
BA_ "GenSigSendType" SG_ 490 HMI_SetCompression_Rq 3;
BA_ "U_U55X_MY2022_Tx" SG_ 490 HMI_SkipTrack_Rq 1;
BA_ "U_CD542_MY2021_Tx" SG_ 490 HMI_SkipTrack_Rq 1;
BA_ "U_T6_MCA_MY2020_Tx" SG_ 490 HMI_SkipTrack_Rq 1;
BA_ "U_P702_MY2021_Tx" SG_ 490 HMI_SkipTrack_Rq 1;
BA_ "U_CD542_MY2021_Rx" SG_ 490 HMI_SkipTrack_Rq 1;
BA_ "U_T6_MCA_MY2020_Rx" SG_ 490 HMI_SkipTrack_Rq 1;
BA_ "U_P702_MY2021_Rx" SG_ 490 HMI_SkipTrack_Rq 1;
BA_ "GenSigSendType" SG_ 490 HMI_SkipTrack_Rq 3;
BA_ "U_U55X_MY2022_Rx" SG_ 1001 AirSuspMsgTxt_D_Rq2 1;
BA_ "U_T6_MCA_MY2020_Rx" SG_ 1001 AirSuspMsgTxt_D_Rq2 1;
BA_ "U_P702_MY2021_Rx" SG_ 1001 AirSuspMsgTxt_D_Rq2 1;
BA_ "U_CD542_MY2021_Rx" SG_ 1001 AirSuspMsgTxt_D_Rq2 1;
BA_ "U_CD764_MY2022_Rx" SG_ 1001 PersIndexSuma_D_Actl 1;
BA_ "U_U55X_MY2022_Rx" SG_ 1001 PersIndexSuma_D_Actl 1;
BA_ "U_P702_MY2021_Rx" SG_ 1001 PersIndexSuma_D_Actl 1;
BA_ "U_CD542_MY2021_Rx" SG_ 1001 PersIndexSuma_D_Actl 1;
BA_ "U_T6_MCA_MY2020_Rx" SG_ 1001 PersIndexSuma_D_Actl 1;
BA_ "GenSigStartValue" SG_ 1001 PersIndexSuma_D_Actl 4;
BA_ "GenSigStartValueInteger" SG_ 1001 PersIndexSuma_D_Actl 4;
BA_ "U_CD764_MY2022_Rx" SG_ 1001 FeatNoSumaActl 1;
BA_ "U_U55X_MY2022_Rx" SG_ 1001 FeatNoSumaActl 1;
BA_ "U_T6_MCA_MY2020_Rx" SG_ 1001 FeatNoSumaActl 1;
BA_ "U_P702_MY2021_Rx" SG_ 1001 FeatNoSumaActl 1;
BA_ "U_CD542_MY2021_Rx" SG_ 1001 FeatNoSumaActl 1;
BA_ "U_CD764_MY2022_Rx" SG_ 1001 FeatConfigSumaActl 1;
BA_ "U_U55X_MY2022_Rx" SG_ 1001 FeatConfigSumaActl 1;
BA_ "U_P702_MY2021_Rx" SG_ 1001 FeatConfigSumaActl 1;
BA_ "U_CD542_MY2021_Rx" SG_ 1001 FeatConfigSumaActl 1;
BA_ "U_T6_MCA_MY2020_Rx" SG_ 1001 FeatConfigSumaActl 1;
BA_ "U_U55X_MY2022_Tx" SG_ 1916 TesterPhysicalResRACM 1;
BA_ "GenSigSendType" SG_ 1916 TesterPhysicalResRACM 3;
BA_ "U_U55X_MY2022_Rx" SG_ 1908 TesterPhysicalReqRACM 1;
BA_ "GenSigSendType" SG_ 1908 TesterPhysicalReqRACM 3;
BA_ "U_U55X_MY2022_Tx" SG_ 1432 RACM_GWOnBoardTester 1;
BA_ "U_CD764_MY2022_Rx" SG_ 1432 RACM_GWOnBoardTester 1;
BA_ "U_U55X_MY2022_Rx" SG_ 1432 RACM_GWOnBoardTester 1;
BA_ "GenSigStartValue" SG_ 1432 RACM_GWOnBoardTester 255;
BA_ "ContentDependant" SG_ 1432 RACM_GWOnBoardTester 1;
BA_ "GenSigStartValueInteger" SG_ 1432 RACM_GWOnBoardTester 255;
BA_ "U_U55X_MY2022_Tx" SG_ 1432 RACM_GWNMProxy 1;
BA_ "U_CD764_MY2022_Rx" SG_ 1432 RACM_GWNMProxy 1;
BA_ "U_U55X_MY2022_Rx" SG_ 1432 RACM_GWNMProxy 1;
BA_ "GenSigStartValue" SG_ 1432 RACM_GWNMProxy 255;
BA_ "ContentDependant" SG_ 1432 RACM_GWNMProxy 1;
BA_ "GenSigStartValueInteger" SG_ 1432 RACM_GWNMProxy 255;
BA_ "U_U55X_MY2022_Tx" SG_ 1432 RACM_AutoSarNMReserved4 1;
BA_ "U_CD764_MY2022_Rx" SG_ 1432 RACM_AutoSarNMReserved4 1;
BA_ "U_U55X_MY2022_Rx" SG_ 1432 RACM_AutoSarNMReserved4 1;
BA_ "GenSigStartValue" SG_ 1432 RACM_AutoSarNMReserved4 255;
BA_ "ContentDependant" SG_ 1432 RACM_AutoSarNMReserved4 1;
BA_ "GenSigStartValueInteger" SG_ 1432 RACM_AutoSarNMReserved4 255;
BA_ "U_U55X_MY2022_Tx" SG_ 1432 RACM_AutoSarNMReserved3 1;
BA_ "U_CD764_MY2022_Rx" SG_ 1432 RACM_AutoSarNMReserved3 1;
BA_ "U_U55X_MY2022_Rx" SG_ 1432 RACM_AutoSarNMReserved3 1;
BA_ "GenSigStartValue" SG_ 1432 RACM_AutoSarNMReserved3 255;
BA_ "ContentDependant" SG_ 1432 RACM_AutoSarNMReserved3 1;
BA_ "GenSigStartValueInteger" SG_ 1432 RACM_AutoSarNMReserved3 255;
BA_ "U_U55X_MY2022_Tx" SG_ 1432 RACM_AutoSarNMReserved2 1;
BA_ "U_CD764_MY2022_Rx" SG_ 1432 RACM_AutoSarNMReserved2 1;
BA_ "U_U55X_MY2022_Rx" SG_ 1432 RACM_AutoSarNMReserved2 1;
BA_ "GenSigStartValue" SG_ 1432 RACM_AutoSarNMReserved2 255;
BA_ "ContentDependant" SG_ 1432 RACM_AutoSarNMReserved2 1;
BA_ "GenSigStartValueInteger" SG_ 1432 RACM_AutoSarNMReserved2 255;
BA_ "U_U55X_MY2022_Tx" SG_ 1432 RACM_AutoSarNMReserved1 1;
BA_ "U_CD764_MY2022_Rx" SG_ 1432 RACM_AutoSarNMReserved1 1;
BA_ "U_U55X_MY2022_Rx" SG_ 1432 RACM_AutoSarNMReserved1 1;
BA_ "GenSigStartValue" SG_ 1432 RACM_AutoSarNMReserved1 255;
BA_ "ContentDependant" SG_ 1432 RACM_AutoSarNMReserved1 1;
BA_ "GenSigStartValueInteger" SG_ 1432 RACM_AutoSarNMReserved1 255;
BA_ "U_U55X_MY2022_Tx" SG_ 1432 RACM_AutoSarNMNodeId 1;
BA_ "U_CD764_MY2022_Rx" SG_ 1432 RACM_AutoSarNMNodeId 1;
BA_ "U_U55X_MY2022_Rx" SG_ 1432 RACM_AutoSarNMNodeId 1;
BA_ "GenSigStartValue" SG_ 1432 RACM_AutoSarNMNodeId 152;
BA_ "ContentDependant" SG_ 1432 RACM_AutoSarNMNodeId 1;
BA_ "GenSigStartValueInteger" SG_ 1432 RACM_AutoSarNMNodeId 150;
BA_ "U_U55X_MY2022_Tx" SG_ 1432 RACM_AutoSarNMControl 1;
BA_ "U_CD764_MY2022_Rx" SG_ 1432 RACM_AutoSarNMControl 1;
BA_ "U_U55X_MY2022_Rx" SG_ 1432 RACM_AutoSarNMControl 1;
BA_ "ContentDependant" SG_ 1432 RACM_AutoSarNMControl 1;
BA_ "U_CD764_MY2022_Rx" SG_ 1923 TesterPhysicalReqDSP 1;
BA_ "U_U55X_MY2022_Rx" SG_ 1923 TesterPhysicalReqDSP 1;
BA_ "U_CD542_MY2021_Rx" SG_ 1923 TesterPhysicalReqDSP 1;
BA_ "U_T6_MCA_MY2020_Rx" SG_ 1923 TesterPhysicalReqDSP 1;
BA_ "U_P702_MY2021_Rx" SG_ 1923 TesterPhysicalReqDSP 1;
BA_ "GenSigSendType" SG_ 1923 TesterPhysicalReqDSP 3;
BA_ "U_CD764_MY2022_Tx" SG_ 1931 TesterPhysicalResDSP 1;
BA_ "U_U55X_MY2022_Tx" SG_ 1931 TesterPhysicalResDSP 1;
BA_ "U_CD542_MY2021_Tx" SG_ 1931 TesterPhysicalResDSP 1;
BA_ "U_T6_MCA_MY2020_Tx" SG_ 1931 TesterPhysicalResDSP 1;
BA_ "GenSigSendType" SG_ 1931 TesterPhysicalResDSP 3;
BA_ "U_CD764_MY2022_Tx" SG_ 1478 DSP_GWOnBoardTester 1;
BA_ "U_U55X_MY2022_Tx" SG_ 1478 DSP_GWOnBoardTester 1;
BA_ "U_CD542_MY2021_Tx" SG_ 1478 DSP_GWOnBoardTester 1;
BA_ "U_T6_MCA_MY2020_Tx" SG_ 1478 DSP_GWOnBoardTester 1;
BA_ "U_CD764_MY2022_Rx" SG_ 1478 DSP_GWOnBoardTester 1;
BA_ "U_U55X_MY2022_Rx" SG_ 1478 DSP_GWOnBoardTester 1;
BA_ "U_T6_MCA_MY2020_Rx" SG_ 1478 DSP_GWOnBoardTester 1;
BA_ "GenSigStartValue" SG_ 1478 DSP_GWOnBoardTester 255;
BA_ "ContentDependant" SG_ 1478 DSP_GWOnBoardTester 1;
BA_ "GenSigStartValueInteger" SG_ 1478 DSP_GWOnBoardTester 255;
BA_ "U_CD764_MY2022_Tx" SG_ 1478 DSP_GWNMProxy 1;
BA_ "U_U55X_MY2022_Tx" SG_ 1478 DSP_GWNMProxy 1;
BA_ "U_CD542_MY2021_Tx" SG_ 1478 DSP_GWNMProxy 1;
BA_ "U_T6_MCA_MY2020_Tx" SG_ 1478 DSP_GWNMProxy 1;
BA_ "U_CD764_MY2022_Rx" SG_ 1478 DSP_GWNMProxy 1;
BA_ "U_U55X_MY2022_Rx" SG_ 1478 DSP_GWNMProxy 1;
BA_ "U_T6_MCA_MY2020_Rx" SG_ 1478 DSP_GWNMProxy 1;
BA_ "GenSigStartValue" SG_ 1478 DSP_GWNMProxy 255;
BA_ "ContentDependant" SG_ 1478 DSP_GWNMProxy 1;
BA_ "GenSigStartValueInteger" SG_ 1478 DSP_GWNMProxy 255;
BA_ "U_CD764_MY2022_Tx" SG_ 1478 DSP_AutoSarNMReserved4 1;
BA_ "U_U55X_MY2022_Tx" SG_ 1478 DSP_AutoSarNMReserved4 1;
BA_ "U_CD542_MY2021_Tx" SG_ 1478 DSP_AutoSarNMReserved4 1;
BA_ "U_T6_MCA_MY2020_Tx" SG_ 1478 DSP_AutoSarNMReserved4 1;
BA_ "U_CD764_MY2022_Rx" SG_ 1478 DSP_AutoSarNMReserved4 1;
BA_ "U_U55X_MY2022_Rx" SG_ 1478 DSP_AutoSarNMReserved4 1;
BA_ "U_T6_MCA_MY2020_Rx" SG_ 1478 DSP_AutoSarNMReserved4 1;
BA_ "GenSigStartValue" SG_ 1478 DSP_AutoSarNMReserved4 255;
BA_ "ContentDependant" SG_ 1478 DSP_AutoSarNMReserved4 1;
BA_ "GenSigStartValueInteger" SG_ 1478 DSP_AutoSarNMReserved4 255;
BA_ "U_CD764_MY2022_Tx" SG_ 1478 DSP_AutoSarNMReserved3 1;
BA_ "U_U55X_MY2022_Tx" SG_ 1478 DSP_AutoSarNMReserved3 1;
BA_ "U_CD542_MY2021_Tx" SG_ 1478 DSP_AutoSarNMReserved3 1;
BA_ "U_T6_MCA_MY2020_Tx" SG_ 1478 DSP_AutoSarNMReserved3 1;
BA_ "U_CD764_MY2022_Rx" SG_ 1478 DSP_AutoSarNMReserved3 1;
BA_ "U_U55X_MY2022_Rx" SG_ 1478 DSP_AutoSarNMReserved3 1;
BA_ "U_T6_MCA_MY2020_Rx" SG_ 1478 DSP_AutoSarNMReserved3 1;
BA_ "GenSigStartValue" SG_ 1478 DSP_AutoSarNMReserved3 255;
BA_ "ContentDependant" SG_ 1478 DSP_AutoSarNMReserved3 1;
BA_ "GenSigStartValueInteger" SG_ 1478 DSP_AutoSarNMReserved3 255;
BA_ "U_CD764_MY2022_Tx" SG_ 1478 DSP_AutoSarNMReserved2 1;
BA_ "U_U55X_MY2022_Tx" SG_ 1478 DSP_AutoSarNMReserved2 1;
BA_ "U_CD542_MY2021_Tx" SG_ 1478 DSP_AutoSarNMReserved2 1;
BA_ "U_T6_MCA_MY2020_Tx" SG_ 1478 DSP_AutoSarNMReserved2 1;
BA_ "U_CD764_MY2022_Rx" SG_ 1478 DSP_AutoSarNMReserved2 1;
BA_ "U_U55X_MY2022_Rx" SG_ 1478 DSP_AutoSarNMReserved2 1;
BA_ "U_T6_MCA_MY2020_Rx" SG_ 1478 DSP_AutoSarNMReserved2 1;
BA_ "GenSigStartValue" SG_ 1478 DSP_AutoSarNMReserved2 255;
BA_ "ContentDependant" SG_ 1478 DSP_AutoSarNMReserved2 1;
BA_ "GenSigStartValueInteger" SG_ 1478 DSP_AutoSarNMReserved2 255;
BA_ "U_CD764_MY2022_Tx" SG_ 1478 DSP_AutoSarNMReserved1 1;
BA_ "U_U55X_MY2022_Tx" SG_ 1478 DSP_AutoSarNMReserved1 1;
BA_ "U_CD542_MY2021_Tx" SG_ 1478 DSP_AutoSarNMReserved1 1;
BA_ "U_T6_MCA_MY2020_Tx" SG_ 1478 DSP_AutoSarNMReserved1 1;
BA_ "U_CD764_MY2022_Rx" SG_ 1478 DSP_AutoSarNMReserved1 1;
BA_ "U_U55X_MY2022_Rx" SG_ 1478 DSP_AutoSarNMReserved1 1;
BA_ "U_T6_MCA_MY2020_Rx" SG_ 1478 DSP_AutoSarNMReserved1 1;
BA_ "GenSigStartValue" SG_ 1478 DSP_AutoSarNMReserved1 255;
BA_ "ContentDependant" SG_ 1478 DSP_AutoSarNMReserved1 1;
BA_ "GenSigStartValueInteger" SG_ 1478 DSP_AutoSarNMReserved1 255;
BA_ "U_CD764_MY2022_Tx" SG_ 1478 DSP_AutoSarNMNodeId 1;
BA_ "U_U55X_MY2022_Tx" SG_ 1478 DSP_AutoSarNMNodeId 1;
BA_ "U_CD542_MY2021_Tx" SG_ 1478 DSP_AutoSarNMNodeId 1;
BA_ "U_T6_MCA_MY2020_Tx" SG_ 1478 DSP_AutoSarNMNodeId 1;
BA_ "U_CD764_MY2022_Rx" SG_ 1478 DSP_AutoSarNMNodeId 1;
BA_ "U_U55X_MY2022_Rx" SG_ 1478 DSP_AutoSarNMNodeId 1;
BA_ "U_T6_MCA_MY2020_Rx" SG_ 1478 DSP_AutoSarNMNodeId 1;
BA_ "GenSigStartValue" SG_ 1478 DSP_AutoSarNMNodeId 198;
BA_ "ContentDependant" SG_ 1478 DSP_AutoSarNMNodeId 1;
BA_ "GenSigStartValueInteger" SG_ 1478 DSP_AutoSarNMNodeId 198;
BA_ "U_CD764_MY2022_Tx" SG_ 1478 DSP_AutoSarNMControl 1;
BA_ "U_U55X_MY2022_Tx" SG_ 1478 DSP_AutoSarNMControl 1;
BA_ "U_CD542_MY2021_Tx" SG_ 1478 DSP_AutoSarNMControl 1;
BA_ "U_T6_MCA_MY2020_Tx" SG_ 1478 DSP_AutoSarNMControl 1;
BA_ "U_CD764_MY2022_Rx" SG_ 1478 DSP_AutoSarNMControl 1;
BA_ "U_U55X_MY2022_Rx" SG_ 1478 DSP_AutoSarNMControl 1;
BA_ "U_T6_MCA_MY2020_Rx" SG_ 1478 DSP_AutoSarNMControl 1;
BA_ "ContentDependant" SG_ 1478 DSP_AutoSarNMControl 1;
BA_ "U_CD764_MY2022_Tx" SG_ 1245 RearDiffLckLamp_D_Cstm 1;
BA_ "ECGUsedTxSignal" SG_ 1245 RearDiffLckLamp_D_Cstm 1;
BA_ "GenSigSendType" SG_ 1245 RearDiffLckLamp_D_Cstm 3;
BA_ "U_CD764_MY2022_Tx" SG_ 1245 FrontDiffLckLamp_D_Cstm 1;
BA_ "ECGUsedTxSignal" SG_ 1245 FrontDiffLckLamp_D_Cstm 1;
BA_ "GenSigSendType" SG_ 1245 FrontDiffLckLamp_D_Cstm 3;
BA_ "U_CD764_MY2022_Tx" SG_ 1245 AwdMdeCstm_D_RqDrv 1;
BA_ "ECGUsedTxSignal" SG_ 1245 AwdMdeCstm_D_RqDrv 1;
BA_ "GenSigSendType" SG_ 1245 AwdMdeCstm_D_RqDrv 3;
BA_ "GenSigStartValueInteger" SG_ 1245 AwdMdeCstm_D_RqDrv 5;
BA_ "U_CD764_MY2022_Tx" SG_ 1245 SelDrvMdeAwd2_D_Cstm 1;
BA_ "ECGUsedTxSignal" SG_ 1245 SelDrvMdeAwd2_D_Cstm 1;
BA_ "GenSigSendType" SG_ 1245 SelDrvMdeAwd2_D_Cstm 3;
BA_ "GenSigStartValue" SG_ 1245 SelDrvMdeAwd2_D_Cstm 31;
BA_ "GenSigStartValueInteger" SG_ 1245 SelDrvMdeAwd2_D_Cstm 31;
BA_ "U_CD764_MY2022_Tx" SG_ 1242 EngExhMdeQuietCstm_D_Rq 1;
BA_ "ECGUsedTxSignal" SG_ 1242 EngExhMdeQuietCstm_D_Rq 1;
BA_ "GenSigSendType" SG_ 1242 EngExhMdeQuietCstm_D_Rq 3;
BA_ "U_CD764_MY2022_Tx" SG_ 1242 StopStrtCstm_D_Rq 1;
BA_ "ECGUsedTxSignal" SG_ 1242 StopStrtCstm_D_Rq 1;
BA_ "GenSigSendType" SG_ 1242 StopStrtCstm_D_Rq 3;
BA_ "U_CD764_MY2022_Tx" SG_ 1242 SelDrvMdeCstmPt_D_Rq 1;
BA_ "ECGUsedTxSignal" SG_ 1242 SelDrvMdeCstmPt_D_Rq 1;
BA_ "GenSigSendType" SG_ 1242 SelDrvMdeCstmPt_D_Rq 3;
BA_ "U_CD764_MY2022_Rx" SG_ 1022 TrlrTireTSensIRM_D_Stat 1;
BA_ "U_CD764_MY2022_Rx" SG_ 1022 TrlrTireTSensIRF_D_Stat 1;
BA_ "U_CD764_MY2022_Rx" SG_ 1022 TrlrTireIRR_T_Actl 1;
BA_ "GenSigStartValue" SG_ 1022 TrlrTireIRR_T_Actl 253;
BA_ "U_CD764_MY2022_Rx" SG_ 1022 TrlrTireIRM_T_Actl 1;
BA_ "GenSigStartValue" SG_ 1022 TrlrTireIRM_T_Actl 253;
BA_ "U_CD764_MY2022_Rx" SG_ 1022 TrlrTireILR_T_Actl 1;
BA_ "GenSigStartValue" SG_ 1022 TrlrTireILR_T_Actl 253;
BA_ "U_CD764_MY2022_Rx" SG_ 1022 TrlrTireILM_T_Actl 1;
BA_ "GenSigStartValue" SG_ 1022 TrlrTireILM_T_Actl 253;
BA_ "U_CD764_MY2022_Rx" SG_ 1022 TrlrTireILF_T_Actl 1;
BA_ "GenSigStartValue" SG_ 1022 TrlrTireILF_T_Actl 253;
BA_ "U_CD764_MY2022_Rx" SG_ 1022 TrlrTireIRF_T_Actl 1;
BA_ "GenSigStartValue" SG_ 1022 TrlrTireIRF_T_Actl 253;
BA_ "U_CD764_MY2022_Rx" SG_ 1022 TrlrTireTSensIRR_D_Stat 1;
BA_ "U_CD764_MY2022_Rx" SG_ 1022 TrlrTireTSensILR_D_Stat 1;
BA_ "U_CD764_MY2022_Rx" SG_ 1022 TrlrTireTSensILM_D_Stat 1;
BA_ "U_CD764_MY2022_Rx" SG_ 1022 TrlrTireTSensILF_D_Stat 1;
BA_ "U_CD764_MY2022_Rx" SG_ 1021 TrlrTireSensIRR_D_Stat 1;
BA_ "U_CD764_MY2022_Rx" SG_ 1021 TrlrTireSensIRM_D_Stat 1;
BA_ "U_CD764_MY2022_Rx" SG_ 1021 TrlrTireIRR_P_Actl 1;
BA_ "GenSigStartValue" SG_ 1021 TrlrTireIRR_P_Actl 65533;
BA_ "GenSigStartValueInteger" SG_ 1021 TrlrTireIRR_P_Actl 65533;
BA_ "U_CD764_MY2022_Rx" SG_ 1021 TrlrTireIRM_P_Actl 1;
BA_ "GenSigStartValue" SG_ 1021 TrlrTireIRM_P_Actl 65533;
BA_ "GenSigStartValueInteger" SG_ 1021 TrlrTireIRM_P_Actl 65533;
BA_ "U_CD764_MY2022_Rx" SG_ 1021 TrlrTireIRF_P_Actl 1;
BA_ "GenSigStartValue" SG_ 1021 TrlrTireIRF_P_Actl 65533;
BA_ "GenSigStartValueInteger" SG_ 1021 TrlrTireIRF_P_Actl 65533;
BA_ "U_CD764_MY2022_Rx" SG_ 1018 TrlrTireSensILR_D_Stat 1;
BA_ "U_CD764_MY2022_Rx" SG_ 1018 TrlrTireSensILM_D_Stat 1;
BA_ "U_CD764_MY2022_Rx" SG_ 1018 TrlrTireSensILF_D_Stat 1;
BA_ "U_CD764_MY2022_Rx" SG_ 1018 TrlrTireILR_P_Actl 1;
BA_ "GenSigStartValue" SG_ 1018 TrlrTireILR_P_Actl 65533;
BA_ "GenSigStartValueInteger" SG_ 1018 TrlrTireILR_P_Actl 65533;
BA_ "U_CD764_MY2022_Rx" SG_ 1018 TrlrTireILM_P_Actl 1;
BA_ "GenSigStartValue" SG_ 1018 TrlrTireILM_P_Actl 65533;
BA_ "GenSigStartValueInteger" SG_ 1018 TrlrTireILM_P_Actl 65533;
BA_ "U_CD764_MY2022_Rx" SG_ 1018 TrlrTireILF_P_Actl 1;
BA_ "GenSigStartValue" SG_ 1018 TrlrTireILF_P_Actl 65533;
BA_ "GenSigStartValueInteger" SG_ 1018 TrlrTireILF_P_Actl 65533;
BA_ "U_U55X_MY2022_Tx" SG_ 502 Dsp_StartItemIndexRq 1;
BA_ "U_CD542_MY2021_Tx" SG_ 502 Dsp_StartItemIndexRq 1;
BA_ "U_T6_MCA_MY2020_Tx" SG_ 502 Dsp_StartItemIndexRq 1;
BA_ "U_P702_MY2021_Tx" SG_ 502 Dsp_StartItemIndexRq 1;
BA_ "U_U55X_MY2022_Rx" SG_ 502 Dsp_StartItemIndexRq 1;
BA_ "U_CD542_MY2021_Rx" SG_ 502 Dsp_StartItemIndexRq 1;
BA_ "U_T6_MCA_MY2020_Rx" SG_ 502 Dsp_StartItemIndexRq 1;
BA_ "U_P702_MY2021_Rx" SG_ 502 Dsp_StartItemIndexRq 1;
BA_ "U_U55X_MY2022_Tx" SG_ 502 Dsp_NbrOfItems2_Rq 1;
BA_ "U_CD542_MY2021_Tx" SG_ 502 Dsp_NbrOfItems2_Rq 1;
BA_ "U_T6_MCA_MY2020_Tx" SG_ 502 Dsp_NbrOfItems2_Rq 1;
BA_ "U_P702_MY2021_Tx" SG_ 502 Dsp_NbrOfItems2_Rq 1;
BA_ "U_U55X_MY2022_Rx" SG_ 502 Dsp_NbrOfItems2_Rq 1;
BA_ "U_CD542_MY2021_Rx" SG_ 502 Dsp_NbrOfItems2_Rq 1;
BA_ "U_T6_MCA_MY2020_Rx" SG_ 502 Dsp_NbrOfItems2_Rq 1;
BA_ "U_P702_MY2021_Rx" SG_ 502 Dsp_NbrOfItems2_Rq 1;
BA_ "U_U55X_MY2022_Tx" SG_ 502 Dsp_ItemNameLength2_Rq 1;
BA_ "U_CD542_MY2021_Tx" SG_ 502 Dsp_ItemNameLength2_Rq 1;
BA_ "U_T6_MCA_MY2020_Tx" SG_ 502 Dsp_ItemNameLength2_Rq 1;
BA_ "U_P702_MY2021_Tx" SG_ 502 Dsp_ItemNameLength2_Rq 1;
BA_ "U_U55X_MY2022_Rx" SG_ 502 Dsp_ItemNameLength2_Rq 1;
BA_ "U_CD542_MY2021_Rx" SG_ 502 Dsp_ItemNameLength2_Rq 1;
BA_ "U_T6_MCA_MY2020_Rx" SG_ 502 Dsp_ItemNameLength2_Rq 1;
BA_ "U_P702_MY2021_Rx" SG_ 502 Dsp_ItemNameLength2_Rq 1;
BA_ "U_U55X_MY2022_Tx" SG_ 502 Dsp_FolderNumber2_Rq 1;
BA_ "U_CD542_MY2021_Tx" SG_ 502 Dsp_FolderNumber2_Rq 1;
BA_ "U_T6_MCA_MY2020_Tx" SG_ 502 Dsp_FolderNumber2_Rq 1;
BA_ "U_P702_MY2021_Tx" SG_ 502 Dsp_FolderNumber2_Rq 1;
BA_ "U_U55X_MY2022_Rx" SG_ 502 Dsp_FolderNumber2_Rq 1;
BA_ "U_CD542_MY2021_Rx" SG_ 502 Dsp_FolderNumber2_Rq 1;
BA_ "U_T6_MCA_MY2020_Rx" SG_ 502 Dsp_FolderNumber2_Rq 1;
BA_ "U_P702_MY2021_Rx" SG_ 502 Dsp_FolderNumber2_Rq 1;
BA_ "U_U55X_MY2022_Tx" SG_ 502 Dsp_FolderContent_Rq 1;
BA_ "U_CD542_MY2021_Tx" SG_ 502 Dsp_FolderContent_Rq 1;
BA_ "U_T6_MCA_MY2020_Tx" SG_ 502 Dsp_FolderContent_Rq 1;
BA_ "U_P702_MY2021_Tx" SG_ 502 Dsp_FolderContent_Rq 1;
BA_ "U_U55X_MY2022_Rx" SG_ 502 Dsp_FolderContent_Rq 1;
BA_ "U_CD542_MY2021_Rx" SG_ 502 Dsp_FolderContent_Rq 1;
BA_ "U_T6_MCA_MY2020_Rx" SG_ 502 Dsp_FolderContent_Rq 1;
BA_ "U_P702_MY2021_Rx" SG_ 502 Dsp_FolderContent_Rq 1;
BA_ "U_U55X_MY2022_Tx" SG_ 502 Dsp_CutItem2_Rq 1;
BA_ "U_CD542_MY2021_Tx" SG_ 502 Dsp_CutItem2_Rq 1;
BA_ "U_T6_MCA_MY2020_Tx" SG_ 502 Dsp_CutItem2_Rq 1;
BA_ "U_P702_MY2021_Tx" SG_ 502 Dsp_CutItem2_Rq 1;
BA_ "U_U55X_MY2022_Rx" SG_ 502 Dsp_CutItem2_Rq 1;
BA_ "U_CD542_MY2021_Rx" SG_ 502 Dsp_CutItem2_Rq 1;
BA_ "U_T6_MCA_MY2020_Rx" SG_ 502 Dsp_CutItem2_Rq 1;
BA_ "U_P702_MY2021_Rx" SG_ 502 Dsp_CutItem2_Rq 1;
BA_ "U_U55X_MY2022_Tx" SG_ 502 Dsp_AudioSourceSel2_Rq 1;
BA_ "U_CD542_MY2021_Tx" SG_ 502 Dsp_AudioSourceSel2_Rq 1;
BA_ "U_T6_MCA_MY2020_Tx" SG_ 502 Dsp_AudioSourceSel2_Rq 1;
BA_ "U_P702_MY2021_Tx" SG_ 502 Dsp_AudioSourceSel2_Rq 1;
BA_ "U_U55X_MY2022_Rx" SG_ 502 Dsp_AudioSourceSel2_Rq 1;
BA_ "U_CD542_MY2021_Rx" SG_ 502 Dsp_AudioSourceSel2_Rq 1;
BA_ "U_T6_MCA_MY2020_Rx" SG_ 502 Dsp_AudioSourceSel2_Rq 1;
BA_ "U_P702_MY2021_Rx" SG_ 502 Dsp_AudioSourceSel2_Rq 1;
BA_ "GenSigSendType" SG_ 502 Dsp_AudioSourceSel2_Rq 3;
BA_ "U_CD542_MY2021_Rx" SG_ 955 Tire_Temp_RF_Data 1;
BA_ "U_U55X_MY2022_Rx" SG_ 955 Tire_Temp_RF_Data 1;
BA_ "U_T6_MCA_MY2020_Rx" SG_ 955 Tire_Temp_RF_Data 1;
BA_ "GenSigStartValue" SG_ 955 Tire_Temp_RF_Data 253;
BA_ "GenSigStartValueInteger" SG_ 955 Tire_Temp_RF_Data 253;
BA_ "U_CD542_MY2021_Rx" SG_ 955 Tire_Temp_ORR_Data 1;
BA_ "U_U55X_MY2022_Rx" SG_ 955 Tire_Temp_ORR_Data 1;
BA_ "U_T6_MCA_MY2020_Rx" SG_ 955 Tire_Temp_ORR_Data 1;
BA_ "GenSigStartValue" SG_ 955 Tire_Temp_ORR_Data 253;
BA_ "GenSigStartValueInteger" SG_ 955 Tire_Temp_ORR_Data 253;
BA_ "U_CD542_MY2021_Rx" SG_ 955 Tire_Temp_OLR_Data 1;
BA_ "U_U55X_MY2022_Rx" SG_ 955 Tire_Temp_OLR_Data 1;
BA_ "U_T6_MCA_MY2020_Rx" SG_ 955 Tire_Temp_OLR_Data 1;
BA_ "GenSigStartValue" SG_ 955 Tire_Temp_OLR_Data 253;
BA_ "GenSigStartValueInteger" SG_ 955 Tire_Temp_OLR_Data 253;
BA_ "U_CD542_MY2021_Rx" SG_ 955 Tire_Temp_LF_Data 1;
BA_ "U_U55X_MY2022_Rx" SG_ 955 Tire_Temp_LF_Data 1;
BA_ "U_T6_MCA_MY2020_Rx" SG_ 955 Tire_Temp_LF_Data 1;
BA_ "GenSigStartValue" SG_ 955 Tire_Temp_LF_Data 253;
BA_ "GenSigStartValueInteger" SG_ 955 Tire_Temp_LF_Data 253;
BA_ "U_CD542_MY2021_Rx" SG_ 955 Tire_Temp_IRR_Data 1;
BA_ "U_U55X_MY2022_Rx" SG_ 955 Tire_Temp_IRR_Data 1;
BA_ "U_T6_MCA_MY2020_Rx" SG_ 955 Tire_Temp_IRR_Data 1;
BA_ "GenSigStartValue" SG_ 955 Tire_Temp_IRR_Data 253;
BA_ "GenSigStartValueInteger" SG_ 955 Tire_Temp_IRR_Data 253;
BA_ "U_CD542_MY2021_Rx" SG_ 955 Tire_Temp_ILR_Data 1;
BA_ "U_U55X_MY2022_Rx" SG_ 955 Tire_Temp_ILR_Data 1;
BA_ "U_T6_MCA_MY2020_Rx" SG_ 955 Tire_Temp_ILR_Data 1;
BA_ "GenSigStartValue" SG_ 955 Tire_Temp_ILR_Data 253;
BA_ "GenSigStartValueInteger" SG_ 955 Tire_Temp_ILR_Data 253;
BA_ "U_U55X_MY2022_Tx" SG_ 1116 TrlrAidSetup_D2_Rq 1;
BA_ "U_CD542_MY2021_Tx" SG_ 1116 TrlrAidSetup_D2_Rq 1;
BA_ "U_T6_MCA_MY2020_Tx" SG_ 1116 TrlrAidSetup_D2_Rq 1;
BA_ "GenSigSendType" SG_ 1116 TrlrAidSetup_D2_Rq 3;
BA_ "U_U55X_MY2022_Tx" SG_ 1116 TrlrAidEnbl_D2_Rq 1;
BA_ "U_CD542_MY2021_Tx" SG_ 1116 TrlrAidEnbl_D2_Rq 1;
BA_ "U_T6_MCA_MY2020_Tx" SG_ 1116 TrlrAidEnbl_D2_Rq 1;
BA_ "GenSigSendType" SG_ 1116 TrlrAidEnbl_D2_Rq 3;
BA_ "U_U55X_MY2022_Tx" SG_ 1116 TlightTest_D_Mnu 1;
BA_ "U_CD542_MY2021_Tx" SG_ 1116 TlightTest_D_Mnu 1;
BA_ "U_T6_MCA_MY2020_Tx" SG_ 1116 TlightTest_D_Mnu 1;
BA_ "U_CD764_MY2022_Rx" SG_ 1116 TlightTest_D_Mnu 1;
BA_ "U_U55X_MY2022_Rx" SG_ 1116 TlightTest_D_Mnu 1;
BA_ "U_CD542_MY2021_Rx" SG_ 1116 TlightTest_D_Mnu 1;
BA_ "ECGUsedRxSignal" SG_ 1116 TlightTest_D_Mnu 1;
BA_ "GenSigSendType" SG_ 1116 TlightTest_D_Mnu 3;
BA_ "U_U55X_MY2022_Tx" SG_ 1116 TrlrTrgtToBmpr_L_Actl 1;
BA_ "U_CD542_MY2021_Tx" SG_ 1116 TrlrTrgtToBmpr_L_Actl 1;
BA_ "U_T6_MCA_MY2020_Tx" SG_ 1116 TrlrTrgtToBmpr_L_Actl 1;
BA_ "U_U55X_MY2022_Tx" SG_ 1116 TrlrTrgtPtrnId_No_Mem 1;
BA_ "U_CD542_MY2021_Tx" SG_ 1116 TrlrTrgtPtrnId_No_Mem 1;
BA_ "U_T6_MCA_MY2020_Tx" SG_ 1116 TrlrTrgtPtrnId_No_Mem 1;
BA_ "U_U55X_MY2022_Tx" SG_ 1116 TrlrRvrseCancl_B_Rq 1;
BA_ "U_CD542_MY2021_Tx" SG_ 1116 TrlrRvrseCancl_B_Rq 1;
BA_ "U_T6_MCA_MY2020_Tx" SG_ 1116 TrlrRvrseCancl_B_Rq 1;
BA_ "GenSigSendType" SG_ 1116 TrlrRvrseCancl_B_Rq 3;
BA_ "U_U55X_MY2022_Tx" SG_ 1116 TrlrIdType_D_Stat 1;
BA_ "U_CD542_MY2021_Tx" SG_ 1116 TrlrIdType_D_Stat 1;
BA_ "U_T6_MCA_MY2020_Tx" SG_ 1116 TrlrIdType_D_Stat 1;
BA_ "GenSigSendType" SG_ 1116 TrlrIdType_D_Stat 3;
BA_ "U_U55X_MY2022_Tx" SG_ 1116 TrlrId_No_Actl 1;
BA_ "U_CD542_MY2021_Tx" SG_ 1116 TrlrId_No_Actl 1;
BA_ "U_T6_MCA_MY2020_Tx" SG_ 1116 TrlrId_No_Actl 1;
BA_ "U_U55X_MY2022_Tx" SG_ 1116 TrlrBallToBmpr_L_Actl 1;
BA_ "U_CD542_MY2021_Tx" SG_ 1116 TrlrBallToBmpr_L_Actl 1;
BA_ "U_T6_MCA_MY2020_Tx" SG_ 1116 TrlrBallToBmpr_L_Actl 1;
BA_ "U_U55X_MY2022_Tx" SG_ 1116 TrlrAxleToBmpr_L_Actl 1;
BA_ "U_CD542_MY2021_Tx" SG_ 1116 TrlrAxleToBmpr_L_Actl 1;
BA_ "U_T6_MCA_MY2020_Tx" SG_ 1116 TrlrAxleToBmpr_L_Actl 1;
BA_ "U_U55X_MY2022_Tx" SG_ 1116 TrlrAnOffstDir_D_Mem 1;
BA_ "U_CD542_MY2021_Tx" SG_ 1116 TrlrAnOffstDir_D_Mem 1;
BA_ "U_T6_MCA_MY2020_Tx" SG_ 1116 TrlrAnOffstDir_D_Mem 1;
BA_ "GenSigSendType" SG_ 1116 TrlrAnOffstDir_D_Mem 3;
BA_ "U_U55X_MY2022_Tx" SG_ 1116 TrlrAnOffst_An_Mem 1;
BA_ "U_CD542_MY2021_Tx" SG_ 1116 TrlrAnOffst_An_Mem 1;
BA_ "U_T6_MCA_MY2020_Tx" SG_ 1116 TrlrAnOffst_An_Mem 1;
BA_ "U_U55X_MY2022_Tx" SG_ 1116 TrlrTrgtOffst_L_Actl 1;
BA_ "U_CD542_MY2021_Tx" SG_ 1116 TrlrTrgtOffst_L_Actl 1;
BA_ "U_T6_MCA_MY2020_Tx" SG_ 1116 TrlrTrgtOffst_L_Actl 1;
BA_ "U_CD542_MY2021_Rx" SG_ 1113 TrlrAnOffstDir_D_Calc_UB 1;
BA_ "U_CD764_MY2022_Rx" SG_ 1113 TrlrAnOffstDir_D_Calc_UB 1;
BA_ "U_P702_MY2021_Rx" SG_ 1113 TrlrAnOffstDir_D_Calc_UB 1;
BA_ "U_U55X_MY2022_Rx" SG_ 1113 TrlrAnOffstDir_D_Calc_UB 1;
BA_ "U_T6_MCA_MY2020_Rx" SG_ 1113 TrlrAnOffstDir_D_Calc_UB 1;
BA_ "U_CD542_MY2021_Rx" SG_ 1113 TrlrAnOffst_An_Calc_UB 1;
BA_ "U_CD764_MY2022_Rx" SG_ 1113 TrlrAnOffst_An_Calc_UB 1;
BA_ "U_P702_MY2021_Rx" SG_ 1113 TrlrAnOffst_An_Calc_UB 1;
BA_ "U_U55X_MY2022_Rx" SG_ 1113 TrlrAnOffst_An_Calc_UB 1;
BA_ "U_T6_MCA_MY2020_Rx" SG_ 1113 TrlrAnOffst_An_Calc_UB 1;
BA_ "U_CD542_MY2021_Rx" SG_ 1113 TrlrAnCalib_B_Complt_UB 1;
BA_ "U_CD764_MY2022_Rx" SG_ 1113 TrlrAnCalib_B_Complt_UB 1;
BA_ "U_U55X_MY2022_Rx" SG_ 1113 TrlrAnCalib_B_Complt_UB 1;
BA_ "U_T6_MCA_MY2020_Rx" SG_ 1113 TrlrAnCalib_B_Complt_UB 1;
BA_ "U_CD542_MY2021_Rx" SG_ 1113 TrlrAidTrgtId_No_Actl_UB 1;
BA_ "U_CD764_MY2022_Rx" SG_ 1113 TrlrAidTrgtId_No_Actl_UB 1;
BA_ "U_U55X_MY2022_Rx" SG_ 1113 TrlrAidTrgtId_No_Actl_UB 1;
BA_ "U_T6_MCA_MY2020_Rx" SG_ 1113 TrlrAidTrgtId_No_Actl_UB 1;
BA_ "U_CD542_MY2021_Rx" SG_ 1113 TrlrAnOffst_An_Calc 1;
BA_ "U_CD764_MY2022_Rx" SG_ 1113 TrlrAnOffst_An_Calc 1;
BA_ "U_P702_MY2021_Rx" SG_ 1113 TrlrAnOffst_An_Calc 1;
BA_ "U_U55X_MY2022_Rx" SG_ 1113 TrlrAnOffst_An_Calc 1;
BA_ "U_T6_MCA_MY2020_Rx" SG_ 1113 TrlrAnOffst_An_Calc 1;
BA_ "U_CD542_MY2021_Rx" SG_ 1113 TrlrAnCalib_B_Complt 1;
BA_ "U_CD764_MY2022_Rx" SG_ 1113 TrlrAnCalib_B_Complt 1;
BA_ "U_U55X_MY2022_Rx" SG_ 1113 TrlrAnCalib_B_Complt 1;
BA_ "U_T6_MCA_MY2020_Rx" SG_ 1113 TrlrAnCalib_B_Complt 1;
BA_ "U_CD542_MY2021_Rx" SG_ 1113 TrlrAnOffstDir_D_Calc 1;
BA_ "U_CD764_MY2022_Rx" SG_ 1113 TrlrAnOffstDir_D_Calc 1;
BA_ "U_P702_MY2021_Rx" SG_ 1113 TrlrAnOffstDir_D_Calc 1;
BA_ "U_U55X_MY2022_Rx" SG_ 1113 TrlrAnOffstDir_D_Calc 1;
BA_ "U_T6_MCA_MY2020_Rx" SG_ 1113 TrlrAnOffstDir_D_Calc 1;
BA_ "U_CD542_MY2021_Rx" SG_ 1113 TrlrAidTrgtId_No_Actl 1;
BA_ "U_CD764_MY2022_Rx" SG_ 1113 TrlrAidTrgtId_No_Actl 1;
BA_ "U_U55X_MY2022_Rx" SG_ 1113 TrlrAidTrgtId_No_Actl 1;
BA_ "U_T6_MCA_MY2020_Rx" SG_ 1113 TrlrAidTrgtId_No_Actl 1;
BA_ "U_U55X_MY2022_Rx" SG_ 1113 immoSecureIdleMode_UB 1;
BA_ "U_CD542_MY2021_Rx" SG_ 1113 immoSecureIdleMode_UB 1;
BA_ "U_T6_MCA_MY2020_Rx" SG_ 1113 immoSecureIdleMode_UB 1;
BA_ "U_U55X_MY2022_Rx" SG_ 1113 immoSecureIdleMode 1;
BA_ "U_CD542_MY2021_Rx" SG_ 1113 immoSecureIdleMode 1;
BA_ "U_T6_MCA_MY2020_Rx" SG_ 1113 immoSecureIdleMode 1;
BA_ "U_CD542_MY2021_Rx" SG_ 1255 BalrRight4Threat_D_Stat 1;
BA_ "U_T6_MCA_MY2020_Rx" SG_ 1255 BalrRight4Threat_D_Stat 1;
BA_ "U_CD542_MY2021_Rx" SG_ 1255 BalrRight4Prev3Y_L_Actl 1;
BA_ "U_T6_MCA_MY2020_Rx" SG_ 1255 BalrRight4Prev3Y_L_Actl 1;
BA_ "GenSigStartValueInteger" SG_ 1255 BalrRight4Prev3Y_L_Actl 64;
BA_ "U_CD542_MY2021_Rx" SG_ 1255 BalrRight4Prev3X_L_Actl 1;
BA_ "U_T6_MCA_MY2020_Rx" SG_ 1255 BalrRight4Prev3X_L_Actl 1;
BA_ "GenSigStartValueInteger" SG_ 1255 BalrRight4Prev3X_L_Actl 64;
BA_ "U_CD542_MY2021_Rx" SG_ 1255 BalrRight4Prev2Y_L_Actl 1;
BA_ "U_T6_MCA_MY2020_Rx" SG_ 1255 BalrRight4Prev2Y_L_Actl 1;
BA_ "GenSigStartValueInteger" SG_ 1255 BalrRight4Prev2Y_L_Actl 64;
BA_ "U_CD542_MY2021_Rx" SG_ 1255 BalrRight4Prev2X_L_Actl 1;
BA_ "U_T6_MCA_MY2020_Rx" SG_ 1255 BalrRight4Prev2X_L_Actl 1;
BA_ "GenSigStartValueInteger" SG_ 1255 BalrRight4Prev2X_L_Actl 64;
BA_ "U_CD542_MY2021_Rx" SG_ 1255 BalrRight4Prev1Y_L_Actl 1;
BA_ "U_T6_MCA_MY2020_Rx" SG_ 1255 BalrRight4Prev1Y_L_Actl 1;
BA_ "GenSigStartValueInteger" SG_ 1255 BalrRight4Prev1Y_L_Actl 64;
BA_ "U_CD542_MY2021_Rx" SG_ 1255 BalrRight4Prev1X_L_Actl 1;
BA_ "U_T6_MCA_MY2020_Rx" SG_ 1255 BalrRight4Prev1X_L_Actl 1;
BA_ "GenSigStartValueInteger" SG_ 1255 BalrRight4Prev1X_L_Actl 64;
BA_ "U_CD542_MY2021_Rx" SG_ 1255 BalrRight4Fast_B_Stat 1;
BA_ "U_T6_MCA_MY2020_Rx" SG_ 1255 BalrRight4Fast_B_Stat 1;
BA_ "U_CD542_MY2021_Rx" SG_ 1255 BalrRight4Dsply_B_Stat 1;
BA_ "U_T6_MCA_MY2020_Rx" SG_ 1255 BalrRight4Dsply_B_Stat 1;
BA_ "U_CD542_MY2021_Rx" SG_ 1255 BalrRight4CurntY_L_Actl 1;
BA_ "U_T6_MCA_MY2020_Rx" SG_ 1255 BalrRight4CurntY_L_Actl 1;
BA_ "GenSigStartValueInteger" SG_ 1255 BalrRight4CurntY_L_Actl 64;
BA_ "U_CD542_MY2021_Rx" SG_ 1255 BalrRight4CurntX_L_Actl 1;
BA_ "U_T6_MCA_MY2020_Rx" SG_ 1255 BalrRight4CurntX_L_Actl 1;
BA_ "GenSigStartValueInteger" SG_ 1255 BalrRight4CurntX_L_Actl 64;
BA_ "U_CD542_MY2021_Rx" SG_ 1254 BalrRight3Threat_D_Stat 1;
BA_ "U_T6_MCA_MY2020_Rx" SG_ 1254 BalrRight3Threat_D_Stat 1;
BA_ "U_CD542_MY2021_Rx" SG_ 1254 BalrRight3Prev3Y_L_Actl 1;
BA_ "U_T6_MCA_MY2020_Rx" SG_ 1254 BalrRight3Prev3Y_L_Actl 1;
BA_ "GenSigStartValueInteger" SG_ 1254 BalrRight3Prev3Y_L_Actl 64;
BA_ "U_CD542_MY2021_Rx" SG_ 1254 BalrRight3Prev3X_L_Actl 1;
BA_ "U_T6_MCA_MY2020_Rx" SG_ 1254 BalrRight3Prev3X_L_Actl 1;
BA_ "GenSigStartValueInteger" SG_ 1254 BalrRight3Prev3X_L_Actl 64;
BA_ "U_CD542_MY2021_Rx" SG_ 1254 BalrRight3Prev2Y_L_Actl 1;
BA_ "U_T6_MCA_MY2020_Rx" SG_ 1254 BalrRight3Prev2Y_L_Actl 1;
BA_ "GenSigStartValueInteger" SG_ 1254 BalrRight3Prev2Y_L_Actl 64;
BA_ "U_CD542_MY2021_Rx" SG_ 1254 BalrRight3Prev2X_L_Actl 1;
BA_ "U_T6_MCA_MY2020_Rx" SG_ 1254 BalrRight3Prev2X_L_Actl 1;
BA_ "GenSigStartValueInteger" SG_ 1254 BalrRight3Prev2X_L_Actl 64;
BA_ "U_CD542_MY2021_Rx" SG_ 1254 BalrRight3Prev1Y_L_Actl 1;
BA_ "U_T6_MCA_MY2020_Rx" SG_ 1254 BalrRight3Prev1Y_L_Actl 1;
BA_ "GenSigStartValueInteger" SG_ 1254 BalrRight3Prev1Y_L_Actl 64;
BA_ "U_CD542_MY2021_Rx" SG_ 1254 BalrRight3Prev1X_L_Actl 1;
BA_ "U_T6_MCA_MY2020_Rx" SG_ 1254 BalrRight3Prev1X_L_Actl 1;
BA_ "GenSigStartValueInteger" SG_ 1254 BalrRight3Prev1X_L_Actl 64;
BA_ "U_CD542_MY2021_Rx" SG_ 1254 BalrRight3Fast_B_Stat 1;
BA_ "U_T6_MCA_MY2020_Rx" SG_ 1254 BalrRight3Fast_B_Stat 1;
BA_ "U_CD542_MY2021_Rx" SG_ 1254 BalrRight3Dsply_B_Stat 1;
BA_ "U_T6_MCA_MY2020_Rx" SG_ 1254 BalrRight3Dsply_B_Stat 1;
BA_ "U_CD542_MY2021_Rx" SG_ 1254 BalrRight3CurntY_L_Actl 1;
BA_ "U_T6_MCA_MY2020_Rx" SG_ 1254 BalrRight3CurntY_L_Actl 1;
BA_ "GenSigStartValueInteger" SG_ 1254 BalrRight3CurntY_L_Actl 64;
BA_ "U_CD542_MY2021_Rx" SG_ 1254 BalrRight3CurntX_L_Actl 1;
BA_ "U_T6_MCA_MY2020_Rx" SG_ 1254 BalrRight3CurntX_L_Actl 1;
BA_ "GenSigStartValueInteger" SG_ 1254 BalrRight3CurntX_L_Actl 64;
BA_ "U_CD542_MY2021_Rx" SG_ 1253 BalrRight2Prev3Y_L_Actl 1;
BA_ "U_T6_MCA_MY2020_Rx" SG_ 1253 BalrRight2Prev3Y_L_Actl 1;
BA_ "GenSigStartValueInteger" SG_ 1253 BalrRight2Prev3Y_L_Actl 64;
BA_ "U_CD542_MY2021_Rx" SG_ 1253 BalrRight2Prev3X_L_Actl 1;
BA_ "U_T6_MCA_MY2020_Rx" SG_ 1253 BalrRight2Prev3X_L_Actl 1;
BA_ "GenSigStartValueInteger" SG_ 1253 BalrRight2Prev3X_L_Actl 64;
BA_ "U_CD542_MY2021_Rx" SG_ 1253 BalrRight2Threat_D_Stat 1;
BA_ "U_T6_MCA_MY2020_Rx" SG_ 1253 BalrRight2Threat_D_Stat 1;
BA_ "U_CD542_MY2021_Rx" SG_ 1253 BalrRight2Prev2Y_L_Actl 1;
BA_ "U_T6_MCA_MY2020_Rx" SG_ 1253 BalrRight2Prev2Y_L_Actl 1;
BA_ "GenSigStartValueInteger" SG_ 1253 BalrRight2Prev2Y_L_Actl 64;
BA_ "U_CD542_MY2021_Rx" SG_ 1253 BalrRight2Prev2X_L_Actl 1;
BA_ "U_T6_MCA_MY2020_Rx" SG_ 1253 BalrRight2Prev2X_L_Actl 1;
BA_ "GenSigStartValueInteger" SG_ 1253 BalrRight2Prev2X_L_Actl 64;
BA_ "U_CD542_MY2021_Rx" SG_ 1253 BalrRight2Prev1Y_L_Actl 1;
BA_ "U_T6_MCA_MY2020_Rx" SG_ 1253 BalrRight2Prev1Y_L_Actl 1;
BA_ "GenSigStartValueInteger" SG_ 1253 BalrRight2Prev1Y_L_Actl 64;
BA_ "U_CD542_MY2021_Rx" SG_ 1253 BalrRight2Prev1X_L_Actl 1;
BA_ "U_T6_MCA_MY2020_Rx" SG_ 1253 BalrRight2Prev1X_L_Actl 1;
BA_ "GenSigStartValueInteger" SG_ 1253 BalrRight2Prev1X_L_Actl 64;
BA_ "U_CD542_MY2021_Rx" SG_ 1253 BalrRight2Fast_B_Stat 1;
BA_ "U_T6_MCA_MY2020_Rx" SG_ 1253 BalrRight2Fast_B_Stat 1;
BA_ "U_CD542_MY2021_Rx" SG_ 1253 BalrRight2Dsply_B_Stat 1;
BA_ "U_T6_MCA_MY2020_Rx" SG_ 1253 BalrRight2Dsply_B_Stat 1;
BA_ "U_CD542_MY2021_Rx" SG_ 1253 BalrRight2CurntY_L_Actl 1;
BA_ "U_T6_MCA_MY2020_Rx" SG_ 1253 BalrRight2CurntY_L_Actl 1;
BA_ "GenSigStartValueInteger" SG_ 1253 BalrRight2CurntY_L_Actl 64;
BA_ "U_CD542_MY2021_Rx" SG_ 1253 BalrRight2CurntX_L_Actl 1;
BA_ "U_T6_MCA_MY2020_Rx" SG_ 1253 BalrRight2CurntX_L_Actl 1;
BA_ "GenSigStartValueInteger" SG_ 1253 BalrRight2CurntX_L_Actl 64;
BA_ "U_CD542_MY2021_Rx" SG_ 1252 BalrRight1Prev3Y_L_Actl 1;
BA_ "U_T6_MCA_MY2020_Rx" SG_ 1252 BalrRight1Prev3Y_L_Actl 1;
BA_ "GenSigStartValueInteger" SG_ 1252 BalrRight1Prev3Y_L_Actl 64;
BA_ "U_CD542_MY2021_Rx" SG_ 1252 BalrRight1Prev3X_L_Actl 1;
BA_ "U_T6_MCA_MY2020_Rx" SG_ 1252 BalrRight1Prev3X_L_Actl 1;
BA_ "GenSigStartValueInteger" SG_ 1252 BalrRight1Prev3X_L_Actl 64;
BA_ "U_CD542_MY2021_Rx" SG_ 1252 BalrRight1Threat_D_Stat 1;
BA_ "U_T6_MCA_MY2020_Rx" SG_ 1252 BalrRight1Threat_D_Stat 1;
BA_ "U_CD542_MY2021_Rx" SG_ 1252 BalrRight1Prev2Y_L_Actl 1;
BA_ "U_T6_MCA_MY2020_Rx" SG_ 1252 BalrRight1Prev2Y_L_Actl 1;
BA_ "GenSigStartValueInteger" SG_ 1252 BalrRight1Prev2Y_L_Actl 64;
BA_ "U_CD542_MY2021_Rx" SG_ 1252 BalrRight1Prev2X_L_Actl 1;
BA_ "U_T6_MCA_MY2020_Rx" SG_ 1252 BalrRight1Prev2X_L_Actl 1;
BA_ "GenSigStartValueInteger" SG_ 1252 BalrRight1Prev2X_L_Actl 64;
BA_ "U_CD542_MY2021_Rx" SG_ 1252 BalrRight1Prev1Y_L_Actl 1;
BA_ "U_T6_MCA_MY2020_Rx" SG_ 1252 BalrRight1Prev1Y_L_Actl 1;
BA_ "GenSigStartValueInteger" SG_ 1252 BalrRight1Prev1Y_L_Actl 64;
BA_ "U_CD542_MY2021_Rx" SG_ 1252 BalrRight1Prev1X_L_Actl 1;
BA_ "U_T6_MCA_MY2020_Rx" SG_ 1252 BalrRight1Prev1X_L_Actl 1;
BA_ "GenSigStartValueInteger" SG_ 1252 BalrRight1Prev1X_L_Actl 64;
BA_ "U_CD542_MY2021_Rx" SG_ 1252 BalrRight1Fast_B_Stat 1;
BA_ "U_T6_MCA_MY2020_Rx" SG_ 1252 BalrRight1Fast_B_Stat 1;
BA_ "U_CD542_MY2021_Rx" SG_ 1252 BalrRight1Dsply_B_Stat 1;
BA_ "U_T6_MCA_MY2020_Rx" SG_ 1252 BalrRight1Dsply_B_Stat 1;
BA_ "U_CD542_MY2021_Rx" SG_ 1252 BalrRight1CurntY_L_Actl 1;
BA_ "U_T6_MCA_MY2020_Rx" SG_ 1252 BalrRight1CurntY_L_Actl 1;
BA_ "GenSigStartValueInteger" SG_ 1252 BalrRight1CurntY_L_Actl 64;
BA_ "U_CD542_MY2021_Rx" SG_ 1252 BalrRight1CurntX_L_Actl 1;
BA_ "U_T6_MCA_MY2020_Rx" SG_ 1252 BalrRight1CurntX_L_Actl 1;
BA_ "GenSigStartValueInteger" SG_ 1252 BalrRight1CurntX_L_Actl 64;
BA_ "U_CD542_MY2021_Rx" SG_ 1251 BalrLeft4Threat_D_Stat 1;
BA_ "U_T6_MCA_MY2020_Rx" SG_ 1251 BalrLeft4Threat_D_Stat 1;
BA_ "U_CD542_MY2021_Rx" SG_ 1251 BalrLeft4Prev3Y_L_Actl 1;
BA_ "U_T6_MCA_MY2020_Rx" SG_ 1251 BalrLeft4Prev3Y_L_Actl 1;
BA_ "GenSigStartValueInteger" SG_ 1251 BalrLeft4Prev3Y_L_Actl 64;
BA_ "U_CD542_MY2021_Rx" SG_ 1251 BalrLeft4Prev3X_L_Actl 1;
BA_ "U_T6_MCA_MY2020_Rx" SG_ 1251 BalrLeft4Prev3X_L_Actl 1;
BA_ "GenSigStartValueInteger" SG_ 1251 BalrLeft4Prev3X_L_Actl 64;
BA_ "U_CD542_MY2021_Rx" SG_ 1251 BalrLeft4Prev2Y_L_Actl 1;
BA_ "U_T6_MCA_MY2020_Rx" SG_ 1251 BalrLeft4Prev2Y_L_Actl 1;
BA_ "GenSigStartValueInteger" SG_ 1251 BalrLeft4Prev2Y_L_Actl 64;
BA_ "U_CD542_MY2021_Rx" SG_ 1251 BalrLeft4Prev2X_L_Actl 1;
BA_ "U_T6_MCA_MY2020_Rx" SG_ 1251 BalrLeft4Prev2X_L_Actl 1;
BA_ "GenSigStartValueInteger" SG_ 1251 BalrLeft4Prev2X_L_Actl 64;
BA_ "U_CD542_MY2021_Rx" SG_ 1251 BalrLeft4Prev1Y_L_Actl 1;
BA_ "U_T6_MCA_MY2020_Rx" SG_ 1251 BalrLeft4Prev1Y_L_Actl 1;
BA_ "GenSigStartValueInteger" SG_ 1251 BalrLeft4Prev1Y_L_Actl 64;
BA_ "U_CD542_MY2021_Rx" SG_ 1251 BalrLeft4Prev1X_L_Actl 1;
BA_ "U_T6_MCA_MY2020_Rx" SG_ 1251 BalrLeft4Prev1X_L_Actl 1;
BA_ "GenSigStartValueInteger" SG_ 1251 BalrLeft4Prev1X_L_Actl 64;
BA_ "U_CD542_MY2021_Rx" SG_ 1251 BalrLeft4Fast_B_Stat 1;
BA_ "U_T6_MCA_MY2020_Rx" SG_ 1251 BalrLeft4Fast_B_Stat 1;
BA_ "U_CD542_MY2021_Rx" SG_ 1251 BalrLeft4Dsply_B_Stat 1;
BA_ "U_T6_MCA_MY2020_Rx" SG_ 1251 BalrLeft4Dsply_B_Stat 1;
BA_ "U_CD542_MY2021_Rx" SG_ 1251 BalrLeft4CurntY_L_Actl 1;
BA_ "U_T6_MCA_MY2020_Rx" SG_ 1251 BalrLeft4CurntY_L_Actl 1;
BA_ "GenSigStartValueInteger" SG_ 1251 BalrLeft4CurntY_L_Actl 64;
BA_ "U_CD542_MY2021_Rx" SG_ 1251 BalrLeft4CurntX_L_Actl 1;
BA_ "U_T6_MCA_MY2020_Rx" SG_ 1251 BalrLeft4CurntX_L_Actl 1;
BA_ "GenSigStartValueInteger" SG_ 1251 BalrLeft4CurntX_L_Actl 64;
BA_ "U_CD542_MY2021_Rx" SG_ 1250 BalrLeft3Threat_D_Stat 1;
BA_ "U_T6_MCA_MY2020_Rx" SG_ 1250 BalrLeft3Threat_D_Stat 1;
BA_ "U_CD542_MY2021_Rx" SG_ 1250 BalrLeft3Prev3Y_L_Actl 1;
BA_ "U_T6_MCA_MY2020_Rx" SG_ 1250 BalrLeft3Prev3Y_L_Actl 1;
BA_ "GenSigStartValueInteger" SG_ 1250 BalrLeft3Prev3Y_L_Actl 64;
BA_ "U_CD542_MY2021_Rx" SG_ 1250 BalrLeft3Prev3X_L_Actl 1;
BA_ "U_T6_MCA_MY2020_Rx" SG_ 1250 BalrLeft3Prev3X_L_Actl 1;
BA_ "GenSigStartValueInteger" SG_ 1250 BalrLeft3Prev3X_L_Actl 64;
BA_ "U_CD542_MY2021_Rx" SG_ 1250 BalrLeft3Prev2Y_L_Actl 1;
BA_ "U_T6_MCA_MY2020_Rx" SG_ 1250 BalrLeft3Prev2Y_L_Actl 1;
BA_ "GenSigStartValueInteger" SG_ 1250 BalrLeft3Prev2Y_L_Actl 64;
BA_ "U_CD542_MY2021_Rx" SG_ 1250 BalrLeft3Prev2X_L_Actl 1;
BA_ "U_T6_MCA_MY2020_Rx" SG_ 1250 BalrLeft3Prev2X_L_Actl 1;
BA_ "GenSigStartValueInteger" SG_ 1250 BalrLeft3Prev2X_L_Actl 64;
BA_ "U_CD542_MY2021_Rx" SG_ 1250 BalrLeft3Prev1Y_L_Actl 1;
BA_ "U_T6_MCA_MY2020_Rx" SG_ 1250 BalrLeft3Prev1Y_L_Actl 1;
BA_ "GenSigStartValueInteger" SG_ 1250 BalrLeft3Prev1Y_L_Actl 64;
BA_ "U_CD542_MY2021_Rx" SG_ 1250 BalrLeft3Prev1X_L_Actl 1;
BA_ "U_T6_MCA_MY2020_Rx" SG_ 1250 BalrLeft3Prev1X_L_Actl 1;
BA_ "GenSigStartValueInteger" SG_ 1250 BalrLeft3Prev1X_L_Actl 64;
BA_ "U_CD542_MY2021_Rx" SG_ 1250 BalrLeft3Fast_B_Stat 1;
BA_ "U_T6_MCA_MY2020_Rx" SG_ 1250 BalrLeft3Fast_B_Stat 1;
BA_ "U_CD542_MY2021_Rx" SG_ 1250 BalrLeft3Dsply_B_Stat 1;
BA_ "U_T6_MCA_MY2020_Rx" SG_ 1250 BalrLeft3Dsply_B_Stat 1;
BA_ "U_CD542_MY2021_Rx" SG_ 1250 BalrLeft3CurntY_L_Actl 1;
BA_ "U_T6_MCA_MY2020_Rx" SG_ 1250 BalrLeft3CurntY_L_Actl 1;
BA_ "GenSigStartValueInteger" SG_ 1250 BalrLeft3CurntY_L_Actl 64;
BA_ "U_CD542_MY2021_Rx" SG_ 1250 BalrLeft3CurntX_L_Actl 1;
BA_ "U_T6_MCA_MY2020_Rx" SG_ 1250 BalrLeft3CurntX_L_Actl 1;
BA_ "GenSigStartValueInteger" SG_ 1250 BalrLeft3CurntX_L_Actl 64;
BA_ "U_CD542_MY2021_Rx" SG_ 1249 BalrLeft2Prev3Y_L_Actl 1;
BA_ "U_T6_MCA_MY2020_Rx" SG_ 1249 BalrLeft2Prev3Y_L_Actl 1;
BA_ "GenSigStartValueInteger" SG_ 1249 BalrLeft2Prev3Y_L_Actl 64;
BA_ "U_CD542_MY2021_Rx" SG_ 1249 BalrLeft2Prev3X_L_Actl 1;
BA_ "U_T6_MCA_MY2020_Rx" SG_ 1249 BalrLeft2Prev3X_L_Actl 1;
BA_ "GenSigStartValueInteger" SG_ 1249 BalrLeft2Prev3X_L_Actl 64;
BA_ "U_CD542_MY2021_Rx" SG_ 1249 BalrLeft2Threat_D_Stat 1;
BA_ "U_T6_MCA_MY2020_Rx" SG_ 1249 BalrLeft2Threat_D_Stat 1;
BA_ "U_CD542_MY2021_Rx" SG_ 1249 BalrLeft2Prev2Y_L_Actl 1;
BA_ "U_T6_MCA_MY2020_Rx" SG_ 1249 BalrLeft2Prev2Y_L_Actl 1;
BA_ "GenSigStartValueInteger" SG_ 1249 BalrLeft2Prev2Y_L_Actl 64;
BA_ "U_CD542_MY2021_Rx" SG_ 1249 BalrLeft2Prev2X_L_Actl 1;
BA_ "U_T6_MCA_MY2020_Rx" SG_ 1249 BalrLeft2Prev2X_L_Actl 1;
BA_ "GenSigStartValueInteger" SG_ 1249 BalrLeft2Prev2X_L_Actl 64;
BA_ "U_CD542_MY2021_Rx" SG_ 1249 BalrLeft2Prev1Y_L_Actl 1;
BA_ "U_T6_MCA_MY2020_Rx" SG_ 1249 BalrLeft2Prev1Y_L_Actl 1;
BA_ "GenSigStartValueInteger" SG_ 1249 BalrLeft2Prev1Y_L_Actl 64;
BA_ "U_CD542_MY2021_Rx" SG_ 1249 BalrLeft2Prev1X_L_Actl 1;
BA_ "U_T6_MCA_MY2020_Rx" SG_ 1249 BalrLeft2Prev1X_L_Actl 1;
BA_ "GenSigStartValueInteger" SG_ 1249 BalrLeft2Prev1X_L_Actl 64;
BA_ "U_CD542_MY2021_Rx" SG_ 1249 BalrLeft2Fast_B_Stat 1;
BA_ "U_T6_MCA_MY2020_Rx" SG_ 1249 BalrLeft2Fast_B_Stat 1;
BA_ "U_CD542_MY2021_Rx" SG_ 1249 BalrLeft2Dsply_B_Stat 1;
BA_ "U_T6_MCA_MY2020_Rx" SG_ 1249 BalrLeft2Dsply_B_Stat 1;
BA_ "U_CD542_MY2021_Rx" SG_ 1249 BalrLeft2CurntY_L_Actl 1;
BA_ "U_T6_MCA_MY2020_Rx" SG_ 1249 BalrLeft2CurntY_L_Actl 1;
BA_ "GenSigStartValueInteger" SG_ 1249 BalrLeft2CurntY_L_Actl 64;
BA_ "U_CD542_MY2021_Rx" SG_ 1249 BalrLeft2CurntX_L_Actl 1;
BA_ "U_T6_MCA_MY2020_Rx" SG_ 1249 BalrLeft2CurntX_L_Actl 1;
BA_ "GenSigStartValueInteger" SG_ 1249 BalrLeft2CurntX_L_Actl 64;
BA_ "U_CD542_MY2021_Rx" SG_ 1248 BalrLeft1Threat_D_Stat 1;
BA_ "U_T6_MCA_MY2020_Rx" SG_ 1248 BalrLeft1Threat_D_Stat 1;
BA_ "U_CD542_MY2021_Rx" SG_ 1248 BalrLeft1Prev3Y_L_Actl 1;
BA_ "U_T6_MCA_MY2020_Rx" SG_ 1248 BalrLeft1Prev3Y_L_Actl 1;
BA_ "GenSigStartValueInteger" SG_ 1248 BalrLeft1Prev3Y_L_Actl 64;
BA_ "U_CD542_MY2021_Rx" SG_ 1248 BalrLeft1Prev3X_L_Actl 1;
BA_ "U_T6_MCA_MY2020_Rx" SG_ 1248 BalrLeft1Prev3X_L_Actl 1;
BA_ "GenSigStartValueInteger" SG_ 1248 BalrLeft1Prev3X_L_Actl 64;
BA_ "U_CD542_MY2021_Rx" SG_ 1248 BalrLeft1Prev2Y_L_Actl 1;
BA_ "U_T6_MCA_MY2020_Rx" SG_ 1248 BalrLeft1Prev2Y_L_Actl 1;
BA_ "GenSigStartValueInteger" SG_ 1248 BalrLeft1Prev2Y_L_Actl 64;
BA_ "U_CD542_MY2021_Rx" SG_ 1248 BalrLeft1Prev2X_L_Actl 1;
BA_ "U_T6_MCA_MY2020_Rx" SG_ 1248 BalrLeft1Prev2X_L_Actl 1;
BA_ "GenSigStartValueInteger" SG_ 1248 BalrLeft1Prev2X_L_Actl 64;
BA_ "U_CD542_MY2021_Rx" SG_ 1248 BalrLeft1Prev1Y_L_Actl 1;
BA_ "U_T6_MCA_MY2020_Rx" SG_ 1248 BalrLeft1Prev1Y_L_Actl 1;
BA_ "GenSigStartValueInteger" SG_ 1248 BalrLeft1Prev1Y_L_Actl 64;
BA_ "U_CD542_MY2021_Rx" SG_ 1248 BalrLeft1Prev1X_L_Actl 1;
BA_ "U_T6_MCA_MY2020_Rx" SG_ 1248 BalrLeft1Prev1X_L_Actl 1;
BA_ "GenSigStartValueInteger" SG_ 1248 BalrLeft1Prev1X_L_Actl 64;
BA_ "U_CD542_MY2021_Rx" SG_ 1248 BalrLeft1Fast_B_Stat 1;
BA_ "U_T6_MCA_MY2020_Rx" SG_ 1248 BalrLeft1Fast_B_Stat 1;
BA_ "U_CD542_MY2021_Rx" SG_ 1248 BalrLeft1Dsply_B_Stat 1;
BA_ "U_T6_MCA_MY2020_Rx" SG_ 1248 BalrLeft1Dsply_B_Stat 1;
BA_ "U_CD542_MY2021_Rx" SG_ 1248 BalrLeft1CurntY_L_Actl 1;
BA_ "U_T6_MCA_MY2020_Rx" SG_ 1248 BalrLeft1CurntY_L_Actl 1;
BA_ "GenSigStartValueInteger" SG_ 1248 BalrLeft1CurntY_L_Actl 64;
BA_ "U_CD542_MY2021_Rx" SG_ 1248 BalrLeft1CurntX_L_Actl 1;
BA_ "U_T6_MCA_MY2020_Rx" SG_ 1248 BalrLeft1CurntX_L_Actl 1;
BA_ "GenSigStartValueInteger" SG_ 1248 BalrLeft1CurntX_L_Actl 64;
BA_ "U_CD542_MY2021_Rx" SG_ 1256 BalrMdeRight_D_Stat_UB 1;
BA_ "U_T6_MCA_MY2020_Rx" SG_ 1256 BalrMdeRight_D_Stat_UB 1;
BA_ "U_CD542_MY2021_Rx" SG_ 1256 BalrMdeSelRight_B_Stat_UB 1;
BA_ "U_T6_MCA_MY2020_Rx" SG_ 1256 BalrMdeSelRight_B_Stat_UB 1;
BA_ "U_CD542_MY2021_Rx" SG_ 1256 BalrRight_D_Stat_UB 1;
BA_ "U_T6_MCA_MY2020_Rx" SG_ 1256 BalrRight_D_Stat_UB 1;
BA_ "U_CD542_MY2021_Rx" SG_ 1256 BalrLckRight_B_Stat_UB 1;
BA_ "U_T6_MCA_MY2020_Rx" SG_ 1256 BalrLckRight_B_Stat_UB 1;
BA_ "U_CD542_MY2021_Rx" SG_ 1256 BalrChimeRight_D_Rq_UB 1;
BA_ "U_T6_MCA_MY2020_Rx" SG_ 1256 BalrChimeRight_D_Rq_UB 1;
BA_ "U_CD542_MY2021_Rx" SG_ 1256 BalrSnsRight_D_Falt_UB 1;
BA_ "U_T6_MCA_MY2020_Rx" SG_ 1256 BalrSnsRight_D_Falt_UB 1;
BA_ "U_CD542_MY2021_Rx" SG_ 1256 BalrWndwRight_B_Stat_UB 1;
BA_ "U_T6_MCA_MY2020_Rx" SG_ 1256 BalrWndwRight_B_Stat_UB 1;
BA_ "U_CD542_MY2021_Rx" SG_ 1256 BalrLckRight_B_Stat 1;
BA_ "U_T6_MCA_MY2020_Rx" SG_ 1256 BalrLckRight_B_Stat 1;
BA_ "GenSigSendType" SG_ 1256 BalrLckRight_B_Stat 3;
BA_ "U_CD542_MY2021_Rx" SG_ 1256 BalrWndwRight_B_Stat 1;
BA_ "U_T6_MCA_MY2020_Rx" SG_ 1256 BalrWndwRight_B_Stat 1;
BA_ "GenSigSendType" SG_ 1256 BalrWndwRight_B_Stat 3;
BA_ "U_CD542_MY2021_Rx" SG_ 1256 BalrMdeSelRight_B_Stat 1;
BA_ "U_T6_MCA_MY2020_Rx" SG_ 1256 BalrMdeSelRight_B_Stat 1;
BA_ "GenSigSendType" SG_ 1256 BalrMdeSelRight_B_Stat 3;
BA_ "U_CD542_MY2021_Rx" SG_ 1256 BalrSnsRight_D_Falt 1;
BA_ "U_T6_MCA_MY2020_Rx" SG_ 1256 BalrSnsRight_D_Falt 1;
BA_ "GenSigSendType" SG_ 1256 BalrSnsRight_D_Falt 3;
BA_ "U_CD542_MY2021_Rx" SG_ 1256 BalrChimeRight_D_Rq 1;
BA_ "U_T6_MCA_MY2020_Rx" SG_ 1256 BalrChimeRight_D_Rq 1;
BA_ "GenSigSendType" SG_ 1256 BalrChimeRight_D_Rq 3;
BA_ "U_CD542_MY2021_Rx" SG_ 1256 BalrMdeRight_D_Stat 1;
BA_ "U_T6_MCA_MY2020_Rx" SG_ 1256 BalrMdeRight_D_Stat 1;
BA_ "GenSigSendType" SG_ 1256 BalrMdeRight_D_Stat 3;
BA_ "GenSigStartValue" SG_ 1256 BalrMdeRight_D_Stat 1;
BA_ "GenSigStartValueInteger" SG_ 1256 BalrMdeRight_D_Stat 1;
BA_ "U_CD542_MY2021_Rx" SG_ 1256 BalrRight_D_Stat 1;
BA_ "U_T6_MCA_MY2020_Rx" SG_ 1256 BalrRight_D_Stat 1;
BA_ "GenSigSendType" SG_ 1256 BalrRight_D_Stat 3;
BA_ "GenSigStartValue" SG_ 1256 BalrRight_D_Stat 2;
BA_ "GenSigStartValueInteger" SG_ 1256 BalrRight_D_Stat 2;
BA_ "U_CD542_MY2021_Rx" SG_ 1256 BalrWndwLeft_B_Stat_UB 1;
BA_ "U_T6_MCA_MY2020_Rx" SG_ 1256 BalrWndwLeft_B_Stat_UB 1;
BA_ "U_CD542_MY2021_Rx" SG_ 1256 BalrSnsLeft_D_Falt_UB 1;
BA_ "U_T6_MCA_MY2020_Rx" SG_ 1256 BalrSnsLeft_D_Falt_UB 1;
BA_ "U_CD542_MY2021_Rx" SG_ 1256 BalrMdeSelLeft_B_Stat_UB 1;
BA_ "U_T6_MCA_MY2020_Rx" SG_ 1256 BalrMdeSelLeft_B_Stat_UB 1;
BA_ "U_CD542_MY2021_Rx" SG_ 1256 BalrMdeLeft_D_Stat_UB 1;
BA_ "U_T6_MCA_MY2020_Rx" SG_ 1256 BalrMdeLeft_D_Stat_UB 1;
BA_ "U_CD542_MY2021_Rx" SG_ 1256 BalrLeft_D_Stat_UB 1;
BA_ "U_T6_MCA_MY2020_Rx" SG_ 1256 BalrLeft_D_Stat_UB 1;
BA_ "U_CD542_MY2021_Rx" SG_ 1256 BalrLckLeft_B_Stat_UB 1;
BA_ "U_T6_MCA_MY2020_Rx" SG_ 1256 BalrLckLeft_B_Stat_UB 1;
BA_ "U_CD542_MY2021_Rx" SG_ 1256 BalrChimeLeft_D_Rq_UB 1;
BA_ "U_T6_MCA_MY2020_Rx" SG_ 1256 BalrChimeLeft_D_Rq_UB 1;
BA_ "U_CD542_MY2021_Rx" SG_ 1256 BalrLeft_D_Stat 1;
BA_ "U_T6_MCA_MY2020_Rx" SG_ 1256 BalrLeft_D_Stat 1;
BA_ "GenSigSendType" SG_ 1256 BalrLeft_D_Stat 3;
BA_ "GenSigStartValue" SG_ 1256 BalrLeft_D_Stat 2;
BA_ "GenSigStartValueInteger" SG_ 1256 BalrLeft_D_Stat 2;
BA_ "U_CD542_MY2021_Rx" SG_ 1256 BalrMdeSelLeft_B_Stat 1;
BA_ "U_T6_MCA_MY2020_Rx" SG_ 1256 BalrMdeSelLeft_B_Stat 1;
BA_ "GenSigSendType" SG_ 1256 BalrMdeSelLeft_B_Stat 3;
BA_ "U_CD542_MY2021_Rx" SG_ 1256 BalrLckLeft_B_Stat 1;
BA_ "U_T6_MCA_MY2020_Rx" SG_ 1256 BalrLckLeft_B_Stat 1;
BA_ "GenSigSendType" SG_ 1256 BalrLckLeft_B_Stat 3;
BA_ "U_CD764_MY2022_Rx" SG_ 1256 BalrWndwLeft_B_Stat 1;
BA_ "U_CD542_MY2021_Rx" SG_ 1256 BalrWndwLeft_B_Stat 1;
BA_ "U_T6_MCA_MY2020_Rx" SG_ 1256 BalrWndwLeft_B_Stat 1;
BA_ "GenSigSendType" SG_ 1256 BalrWndwLeft_B_Stat 3;
BA_ "U_CD542_MY2021_Rx" SG_ 1256 BalrMdeLeft_D_Stat 1;
BA_ "U_T6_MCA_MY2020_Rx" SG_ 1256 BalrMdeLeft_D_Stat 1;
BA_ "GenSigSendType" SG_ 1256 BalrMdeLeft_D_Stat 3;
BA_ "GenSigStartValue" SG_ 1256 BalrMdeLeft_D_Stat 1;
BA_ "GenSigStartValueInteger" SG_ 1256 BalrMdeLeft_D_Stat 1;
BA_ "U_CD542_MY2021_Rx" SG_ 1256 BalrSnsLeft_D_Falt 1;
BA_ "U_T6_MCA_MY2020_Rx" SG_ 1256 BalrSnsLeft_D_Falt 1;
BA_ "GenSigSendType" SG_ 1256 BalrSnsLeft_D_Falt 3;
BA_ "U_CD542_MY2021_Rx" SG_ 1256 BalrChimeLeft_D_Rq 1;
BA_ "U_T6_MCA_MY2020_Rx" SG_ 1256 BalrChimeLeft_D_Rq 1;
BA_ "GenSigSendType" SG_ 1256 BalrChimeLeft_D_Rq 3;
BA_ "U_U55X_MY2022_Rx" SG_ 1256 WakeAlarm2_D_Stat_UB 1;
BA_ "U_T6_MCA_MY2020_Rx" SG_ 1256 WakeAlarm2_D_Stat_UB 1;
BA_ "U_U55X_MY2022_Rx" SG_ 1256 WakeAlarm2_D_Stat 1;
BA_ "U_T6_MCA_MY2020_Rx" SG_ 1256 WakeAlarm2_D_Stat 1;
BA_ "GenSigSendType" SG_ 1256 WakeAlarm2_D_Stat 3;
BA_ "GenSigStartValue" SG_ 1256 WakeAlarm2_D_Stat 3;
BA_ "GenSigStartValueInteger" SG_ 1256 WakeAlarm2_D_Stat 3;
BA_ "U_T6_MCA_MY2020_Tx" SG_ 529 OnbChrgToPcWknd_D_Actl 1;
BA_ "U_P702_MY2021_Tx" SG_ 529 OnbChrgToPcWknd_D_Actl 1;
BA_ "U_U55X_MY2022_Tx" SG_ 529 OnbChrgToPcWknd_D_Actl 1;
BA_ "U_CD542_MY2021_Tx" SG_ 529 OnbChrgToPcWknd_D_Actl 1;
BA_ "U_T6_MCA_MY2020_Tx" SG_ 529 OnbChrgToPcWkdy_D_Actl 1;
BA_ "U_P702_MY2021_Tx" SG_ 529 OnbChrgToPcWkdy_D_Actl 1;
BA_ "U_U55X_MY2022_Tx" SG_ 529 OnbChrgToPcWkdy_D_Actl 1;
BA_ "U_CD542_MY2021_Tx" SG_ 529 OnbChrgToPcWkdy_D_Actl 1;
BA_ "U_T6_MCA_MY2020_Tx" SG_ 529 OnbChrgSetNow_D_Rq 1;
BA_ "U_P702_MY2021_Tx" SG_ 529 OnbChrgSetNow_D_Rq 1;
BA_ "U_U55X_MY2022_Tx" SG_ 529 OnbChrgSetNow_D_Rq 1;
BA_ "U_CD542_MY2021_Tx" SG_ 529 OnbChrgSetNow_D_Rq 1;
BA_ "U_T6_MCA_MY2020_Tx" SG_ 529 OnbChrgSetDelete_B_Rq 1;
BA_ "U_P702_MY2021_Tx" SG_ 529 OnbChrgSetDelete_B_Rq 1;
BA_ "U_U55X_MY2022_Tx" SG_ 529 OnbChrgSetDelete_B_Rq 1;
BA_ "U_CD542_MY2021_Tx" SG_ 529 OnbChrgSetDelete_B_Rq 1;
BA_ "U_T6_MCA_MY2020_Tx" SG_ 529 OnbChrgPrflWknd_No_Rq 1;
BA_ "U_P702_MY2021_Tx" SG_ 529 OnbChrgPrflWknd_No_Rq 1;
BA_ "U_CD764_MY2022_Tx" SG_ 529 OnbChrgPrflWknd_No_Rq 1;
BA_ "U_U55X_MY2022_Tx" SG_ 529 OnbChrgPrflWknd_No_Rq 1;
BA_ "U_CD542_MY2021_Tx" SG_ 529 OnbChrgPrflWknd_No_Rq 1;
BA_ "U_T6_MCA_MY2020_Tx" SG_ 529 OnbChrgPrflWkdy_No_Rq 1;
BA_ "U_P702_MY2021_Tx" SG_ 529 OnbChrgPrflWkdy_No_Rq 1;
BA_ "U_U55X_MY2022_Tx" SG_ 529 OnbChrgPrflWkdy_No_Rq 1;
BA_ "U_CD542_MY2021_Tx" SG_ 529 OnbChrgPrflWkdy_No_Rq 1;
BA_ "U_T6_MCA_MY2020_Tx" SG_ 529 OnbChrgPrflUpdate_B_Rq 1;
BA_ "U_P702_MY2021_Tx" SG_ 529 OnbChrgPrflUpdate_B_Rq 1;
BA_ "U_U55X_MY2022_Tx" SG_ 529 OnbChrgPrflUpdate_B_Rq 1;
BA_ "U_CD542_MY2021_Tx" SG_ 529 OnbChrgPrflUpdate_B_Rq 1;
BA_ "U_CD764_MY2022_Rx" SG_ 529 OnbChrgPrflUpdate_B_Rq 1;
BA_ "U_U55X_MY2022_Rx" SG_ 529 OnbChrgPrflUpdate_B_Rq 1;
BA_ "U_CD542_MY2021_Rx" SG_ 529 OnbChrgPrflUpdate_B_Rq 1;
BA_ "ECGUsedRxSignal" SG_ 529 OnbChrgPrflUpdate_B_Rq 1;
BA_ "U_T6_MCA_MY2020_Rx" SG_ 529 OnbChrgPrflUpdate_B_Rq 1;
BA_ "GenSigSendType" SG_ 529 OnbChrgPrflUpdate_B_Rq 3;
BA_ "U_T6_MCA_MY2020_Tx" SG_ 529 OnbChrgLocIdUns_B_Rq 1;
BA_ "U_P702_MY2021_Tx" SG_ 529 OnbChrgLocIdUns_B_Rq 1;
BA_ "U_U55X_MY2022_Tx" SG_ 529 OnbChrgLocIdUns_B_Rq 1;
BA_ "U_CD542_MY2021_Tx" SG_ 529 OnbChrgLocIdUns_B_Rq 1;
BA_ "U_U55X_MY2022_Tx" SG_ 529 OnbChrgLocIdTrgt_No_Rq 1;
BA_ "U_CD542_MY2021_Tx" SG_ 529 OnbChrgLocIdTrgt_No_Rq 1;
BA_ "U_T6_MCA_MY2020_Tx" SG_ 529 OnbChrgLocIdTrgt_No_Rq 1;
BA_ "U_P702_MY2021_Tx" SG_ 529 OnbChrgLocIdTrgt_No_Rq 1;
BA_ "GenSigSendType" SG_ 529 OnbChrgLocIdTrgt_No_Rq 3;
BA_ "U_CD764_MY2022_Rx" SG_ 642 SldrrMsgTxt_D2_Rq_UB 1;
BA_ "U_CD542_MY2021_Rx" SG_ 642 SldrrMsgTxt_D2_Rq_UB 1;
BA_ "U_T6_MCA_MY2020_Rx" SG_ 642 SldrrMsgTxt_D2_Rq_UB 1;
BA_ "U_CD764_MY2022_Rx" SG_ 642 SldrrMsgTxt_D2_Rq 1;
BA_ "U_CD542_MY2021_Rx" SG_ 642 SldrrMsgTxt_D2_Rq 1;
BA_ "U_T6_MCA_MY2020_Rx" SG_ 642 SldrrMsgTxt_D2_Rq 1;
BA_ "GenSigSendType" SG_ 642 SldrrMsgTxt_D2_Rq 3;
BA_ "WakeupSignal" SG_ 642 SldrrMsgTxt_D2_Rq 1;
BA_ "U_CD764_MY2022_Rx" SG_ 642 SldrrChime_D_Rq_UB 1;
BA_ "U_CD542_MY2021_Rx" SG_ 642 SldrrChime_D_Rq_UB 1;
BA_ "U_T6_MCA_MY2020_Rx" SG_ 642 SldrrChime_D_Rq_UB 1;
BA_ "U_CD764_MY2022_Rx" SG_ 642 SldrrChime_D_Rq 1;
BA_ "U_CD542_MY2021_Rx" SG_ 642 SldrrChime_D_Rq 1;
BA_ "U_T6_MCA_MY2020_Rx" SG_ 642 SldrrChime_D_Rq 1;
BA_ "GenSigSendType" SG_ 642 SldrrChime_D_Rq 3;
BA_ "WakeupSignal" SG_ 642 SldrrChime_D_Rq 1;
BA_ "U_CD764_MY2022_Rx" SG_ 642 SldrlMsgTxt_D2_Rq_UB 1;
BA_ "U_CD542_MY2021_Rx" SG_ 642 SldrlMsgTxt_D2_Rq_UB 1;
BA_ "U_T6_MCA_MY2020_Rx" SG_ 642 SldrlMsgTxt_D2_Rq_UB 1;
BA_ "U_CD764_MY2022_Rx" SG_ 642 SldrlMsgTxt_D2_Rq 1;
BA_ "U_CD542_MY2021_Rx" SG_ 642 SldrlMsgTxt_D2_Rq 1;
BA_ "U_T6_MCA_MY2020_Rx" SG_ 642 SldrlMsgTxt_D2_Rq 1;
BA_ "GenSigSendType" SG_ 642 SldrlMsgTxt_D2_Rq 3;
BA_ "WakeupSignal" SG_ 642 SldrlMsgTxt_D2_Rq 1;
BA_ "U_CD764_MY2022_Rx" SG_ 642 SldrlChime_D_Rq_UB 1;
BA_ "U_CD542_MY2021_Rx" SG_ 642 SldrlChime_D_Rq_UB 1;
BA_ "U_T6_MCA_MY2020_Rx" SG_ 642 SldrlChime_D_Rq_UB 1;
BA_ "U_CD764_MY2022_Rx" SG_ 642 SldrlChime_D_Rq 1;
BA_ "U_CD542_MY2021_Rx" SG_ 642 SldrlChime_D_Rq 1;
BA_ "U_T6_MCA_MY2020_Rx" SG_ 642 SldrlChime_D_Rq 1;
BA_ "GenSigSendType" SG_ 642 SldrlChime_D_Rq 3;
BA_ "WakeupSignal" SG_ 642 SldrlChime_D_Rq 1;
BA_ "U_CD542_MY2021_Rx" SG_ 642 PaakMyKeySearch_D_Stat_UB 1;
BA_ "U_U55X_MY2022_Rx" SG_ 642 PaakMyKeySearch_D_Stat_UB 1;
BA_ "U_T6_MCA_MY2020_Rx" SG_ 642 PaakMyKeySearch_D_Stat_UB 1;
BA_ "U_P702_MY2021_Rx" SG_ 642 PaakMyKeySearch_D_Stat_UB 1;
BA_ "U_CD764_MY2022_Rx" SG_ 642 UreaLvlQlty_D_RqDsply_UB 1;
BA_ "U_CD542_MY2021_Rx" SG_ 642 UreaLvlQlty_D_RqDsply_UB 1;
BA_ "U_T6_MCA_MY2020_Rx" SG_ 642 UreaLvlQlty_D_RqDsply_UB 1;
BA_ "U_P702_MY2021_Rx" SG_ 642 UreaLvlQlty_D_RqDsply_UB 1;
BA_ "U_CD764_MY2022_Rx" SG_ 642 DieslPrtcWarn_D_Rq_UB 1;
BA_ "U_CD542_MY2021_Rx" SG_ 642 DieslPrtcWarn_D_Rq_UB 1;
BA_ "U_T6_MCA_MY2020_Rx" SG_ 642 DieslPrtcWarn_D_Rq_UB 1;
BA_ "U_CD764_MY2022_Rx" SG_ 642 UreaQltySysWarn_D_Rq_UB 1;
BA_ "U_CD542_MY2021_Rx" SG_ 642 UreaQltySysWarn_D_Rq_UB 1;
BA_ "U_T6_MCA_MY2020_Rx" SG_ 642 UreaQltySysWarn_D_Rq_UB 1;
BA_ "U_P702_MY2021_Rx" SG_ 642 UreaQltySysWarn_D_Rq_UB 1;
BA_ "U_CD764_MY2022_Rx" SG_ 642 UreaLvlTxtWarn_D_Rq_UB 1;
BA_ "U_CD542_MY2021_Rx" SG_ 642 UreaLvlTxtWarn_D_Rq_UB 1;
BA_ "U_T6_MCA_MY2020_Rx" SG_ 642 UreaLvlTxtWarn_D_Rq_UB 1;
BA_ "U_P702_MY2021_Rx" SG_ 642 UreaLvlTxtWarn_D_Rq_UB 1;
BA_ "U_CD764_MY2022_Rx" SG_ 642 UreaLvlQlty_D_RqDsply 1;
BA_ "U_CD542_MY2021_Rx" SG_ 642 UreaLvlQlty_D_RqDsply 1;
BA_ "U_T6_MCA_MY2020_Rx" SG_ 642 UreaLvlQlty_D_RqDsply 1;
BA_ "U_P702_MY2021_Rx" SG_ 642 UreaLvlQlty_D_RqDsply 1;
BA_ "GenSigSendType" SG_ 642 UreaLvlQlty_D_RqDsply 3;
BA_ "U_CD764_MY2022_Rx" SG_ 642 UreaLvlTxtWarn_D_Rq 1;
BA_ "U_CD542_MY2021_Rx" SG_ 642 UreaLvlTxtWarn_D_Rq 1;
BA_ "U_T6_MCA_MY2020_Rx" SG_ 642 UreaLvlTxtWarn_D_Rq 1;
BA_ "U_P702_MY2021_Rx" SG_ 642 UreaLvlTxtWarn_D_Rq 1;
BA_ "GenSigSendType" SG_ 642 UreaLvlTxtWarn_D_Rq 3;
BA_ "U_CD764_MY2022_Rx" SG_ 642 UreaQltySysWarn_D_Rq 1;
BA_ "U_CD542_MY2021_Rx" SG_ 642 UreaQltySysWarn_D_Rq 1;
BA_ "U_T6_MCA_MY2020_Rx" SG_ 642 UreaQltySysWarn_D_Rq 1;
BA_ "U_P702_MY2021_Rx" SG_ 642 UreaQltySysWarn_D_Rq 1;
BA_ "GenSigSendType" SG_ 642 UreaQltySysWarn_D_Rq 3;
BA_ "U_CD764_MY2022_Rx" SG_ 642 DieslPrtcWarn_D_Rq 1;
BA_ "U_CD542_MY2021_Rx" SG_ 642 DieslPrtcWarn_D_Rq 1;
BA_ "U_T6_MCA_MY2020_Rx" SG_ 642 DieslPrtcWarn_D_Rq 1;
BA_ "GenSigSendType" SG_ 642 DieslPrtcWarn_D_Rq 3;
BA_ "U_U55X_MY2022_Rx" SG_ 642 KeyMyKeyTot_No2_Cnt_UB 1;
BA_ "U_CD542_MY2021_Rx" SG_ 642 KeyMyKeyTot_No2_Cnt_UB 1;
BA_ "U_T6_MCA_MY2020_Rx" SG_ 642 KeyMyKeyTot_No2_Cnt_UB 1;
BA_ "U_P702_MY2021_Rx" SG_ 642 KeyMyKeyTot_No2_Cnt_UB 1;
BA_ "U_U55X_MY2022_Rx" SG_ 642 KeyAdmnTot_No2_Cnt_UB 1;
BA_ "U_CD542_MY2021_Rx" SG_ 642 KeyAdmnTot_No2_Cnt_UB 1;
BA_ "U_T6_MCA_MY2020_Rx" SG_ 642 KeyAdmnTot_No2_Cnt_UB 1;
BA_ "U_P702_MY2021_Rx" SG_ 642 KeyAdmnTot_No2_Cnt_UB 1;
BA_ "U_CD542_MY2021_Rx" SG_ 642 KeyMyKeyTot_No2_Cnt 1;
BA_ "U_U55X_MY2022_Rx" SG_ 642 KeyMyKeyTot_No2_Cnt 1;
BA_ "U_T6_MCA_MY2020_Rx" SG_ 642 KeyMyKeyTot_No2_Cnt 1;
BA_ "U_P702_MY2021_Rx" SG_ 642 KeyMyKeyTot_No2_Cnt 1;
BA_ "U_U55X_MY2022_Rx" SG_ 642 KeyAdmnTot_No2_Cnt 1;
BA_ "U_CD542_MY2021_Rx" SG_ 642 KeyAdmnTot_No2_Cnt 1;
BA_ "U_T6_MCA_MY2020_Rx" SG_ 642 KeyAdmnTot_No2_Cnt 1;
BA_ "U_P702_MY2021_Rx" SG_ 642 KeyAdmnTot_No2_Cnt 1;
BA_ "U_CD764_MY2022_Rx" SG_ 642 DcChrgSrvcRqd_B_Rq_UB 1;
BA_ "U_CD542_MY2021_Rx" SG_ 642 DcChrgSrvcRqd_B_Rq_UB 1;
BA_ "U_T6_MCA_MY2020_Rx" SG_ 642 DcChrgSrvcRqd_B_Rq_UB 1;
BA_ "U_CD764_MY2022_Rx" SG_ 642 DcChrgSrvcRqd_B_Rq 1;
BA_ "U_CD542_MY2021_Rx" SG_ 642 DcChrgSrvcRqd_B_Rq 1;
BA_ "U_T6_MCA_MY2020_Rx" SG_ 642 DcChrgSrvcRqd_B_Rq 1;
BA_ "GenSigSendType" SG_ 642 DcChrgSrvcRqd_B_Rq 3;
BA_ "U_U55X_MY2022_Rx" SG_ 642 PaakMyKeySearch_D_Stat 1;
BA_ "U_CD542_MY2021_Rx" SG_ 642 PaakMyKeySearch_D_Stat 1;
BA_ "U_T6_MCA_MY2020_Rx" SG_ 642 PaakMyKeySearch_D_Stat 1;
BA_ "U_P702_MY2021_Rx" SG_ 642 PaakMyKeySearch_D_Stat 1;
BA_ "GenSigSendType" SG_ 642 PaakMyKeySearch_D_Stat 3;
BA_ "U_CD764_MY2022_Rx" SG_ 642 GrdAsstActv_B_Stat_UB 1;
BA_ "U_CD542_MY2021_Rx" SG_ 642 GrdAsstActv_B_Stat_UB 1;
BA_ "U_CD764_MY2022_Rx" SG_ 642 GrdAsstActv_B_Stat 1;
BA_ "U_CD542_MY2021_Rx" SG_ 642 GrdAsstActv_B_Stat 1;
BA_ "GenSigSendType" SG_ 642 GrdAsstActv_B_Stat 3;
BA_ "U_CD764_MY2022_Rx" SG_ 642 TrlrAidTrlrId_No_Rq_UB 1;
BA_ "U_CD542_MY2021_Rx" SG_ 642 TrlrAidTrlrId_No_Rq_UB 1;
BA_ "U_U55X_MY2022_Rx" SG_ 642 TrlrAidTrlrId_No_Rq_UB 1;
BA_ "U_T6_MCA_MY2020_Rx" SG_ 642 TrlrAidTrlrId_No_Rq_UB 1;
BA_ "U_CD764_MY2022_Rx" SG_ 642 TrlrAidTrlrId_No_Rq 1;
BA_ "U_CD542_MY2021_Rx" SG_ 642 TrlrAidTrlrId_No_Rq 1;
BA_ "U_U55X_MY2022_Rx" SG_ 642 TrlrAidTrlrId_No_Rq 1;
BA_ "U_T6_MCA_MY2020_Rx" SG_ 642 TrlrAidTrlrId_No_Rq 1;
BA_ "GenSigSendType" SG_ 642 TrlrAidTrlrId_No_Rq 3;
BA_ "U_U55X_MY2022_Rx" SG_ 893 RngPerChrgAvg_L2_Dsply_UB 1;
BA_ "U_CD542_MY2021_Rx" SG_ 893 RngPerChrgAvg_L2_Dsply_UB 1;
BA_ "U_CD542_MY2021_Rx" SG_ 893 RngImpctClim_L_Dsply_UB 1;
BA_ "U_T6_MCA_MY2020_Rx" SG_ 893 RngImpctClim_L_Dsply_UB 1;
BA_ "U_CD542_MY2021_Rx" SG_ 893 RngImpctDrv_L_Dsply_UB 1;
BA_ "U_T6_MCA_MY2020_Rx" SG_ 893 RngImpctDrv_L_Dsply_UB 1;
BA_ "U_CD542_MY2021_Rx" SG_ 893 RngImpctDrv_L_Dsply 1;
BA_ "U_T6_MCA_MY2020_Rx" SG_ 893 RngImpctDrv_L_Dsply 1;
BA_ "GenSigStartValueInteger" SG_ 893 RngImpctDrv_L_Dsply 255;
BA_ "U_CD542_MY2021_Rx" SG_ 893 RngImpctClim_L_Dsply 1;
BA_ "U_T6_MCA_MY2020_Rx" SG_ 893 RngImpctClim_L_Dsply 1;
BA_ "GenSigStartValueInteger" SG_ 893 RngImpctClim_L_Dsply 255;
BA_ "U_CD542_MY2021_Rx" SG_ 893 VehElEffAvg_No_Dsply_UB 1;
BA_ "U_U55X_MY2022_Rx" SG_ 893 VehElEffAvg_No_Dsply_UB 1;
BA_ "U_T6_MCA_MY2020_Rx" SG_ 893 VehElEffAvg_No_Dsply_UB 1;
BA_ "U_CD542_MY2021_Rx" SG_ 893 VehElEffAvg_No_Dsply 1;
BA_ "U_U55X_MY2022_Rx" SG_ 893 VehElEffAvg_No_Dsply 1;
BA_ "U_T6_MCA_MY2020_Rx" SG_ 893 VehElEffAvg_No_Dsply 1;
BA_ "GenSigStartValue" SG_ 893 VehElEffAvg_No_Dsply 126;
BA_ "GenSigStartValueInteger" SG_ 893 VehElEffAvg_No_Dsply 126;
BA_ "U_U55X_MY2022_Rx" SG_ 893 RngPerChrgAvg_L2_Dsply 1;
BA_ "U_CD542_MY2021_Rx" SG_ 893 RngPerChrgAvg_L2_Dsply 1;
BA_ "GenSigStartValue" SG_ 893 RngPerChrgAvg_L2_Dsply 8190;
BA_ "GenSigStartValueInteger" SG_ 893 RngPerChrgAvg_L2_Dsply 4094;
BA_ "GenSigStartValue" SG_ 893 TrnAout2_W_ActlUnfilt 65534;
BA_ "GenSigStartValueInteger" SG_ 893 TrnAout2_W_ActlUnfilt 65534;
BA_ "U_U55X_MY2022_Tx" SG_ 500 Dsp_SourceSetTrack_Rq 1;
BA_ "U_CD542_MY2021_Tx" SG_ 500 Dsp_SourceSetTrack_Rq 1;
BA_ "U_T6_MCA_MY2020_Tx" SG_ 500 Dsp_SourceSetTrack_Rq 1;
BA_ "U_P702_MY2021_Tx" SG_ 500 Dsp_SourceSetTrack_Rq 1;
BA_ "U_U55X_MY2022_Rx" SG_ 500 Dsp_SourceSetTrack_Rq 1;
BA_ "U_CD542_MY2021_Rx" SG_ 500 Dsp_SourceSetTrack_Rq 1;
BA_ "U_T6_MCA_MY2020_Rx" SG_ 500 Dsp_SourceSetTrack_Rq 1;
BA_ "U_P702_MY2021_Rx" SG_ 500 Dsp_SourceSetTrack_Rq 1;
BA_ "U_U55X_MY2022_Tx" SG_ 500 Dsp_ItemNameLength_Rq 1;
BA_ "U_CD542_MY2021_Tx" SG_ 500 Dsp_ItemNameLength_Rq 1;
BA_ "U_T6_MCA_MY2020_Tx" SG_ 500 Dsp_ItemNameLength_Rq 1;
BA_ "U_P702_MY2021_Tx" SG_ 500 Dsp_ItemNameLength_Rq 1;
BA_ "U_U55X_MY2022_Rx" SG_ 500 Dsp_ItemNameLength_Rq 1;
BA_ "U_CD542_MY2021_Rx" SG_ 500 Dsp_ItemNameLength_Rq 1;
BA_ "U_T6_MCA_MY2020_Rx" SG_ 500 Dsp_ItemNameLength_Rq 1;
BA_ "U_P702_MY2021_Rx" SG_ 500 Dsp_ItemNameLength_Rq 1;
BA_ "U_U55X_MY2022_Tx" SG_ 500 Dsp_GetCDTOCDData_Rq 1;
BA_ "U_CD542_MY2021_Tx" SG_ 500 Dsp_GetCDTOCDData_Rq 1;
BA_ "U_T6_MCA_MY2020_Tx" SG_ 500 Dsp_GetCDTOCDData_Rq 1;
BA_ "U_P702_MY2021_Tx" SG_ 500 Dsp_GetCDTOCDData_Rq 1;
BA_ "U_U55X_MY2022_Rx" SG_ 500 Dsp_GetCDTOCDData_Rq 1;
BA_ "U_CD542_MY2021_Rx" SG_ 500 Dsp_GetCDTOCDData_Rq 1;
BA_ "U_T6_MCA_MY2020_Rx" SG_ 500 Dsp_GetCDTOCDData_Rq 1;
BA_ "U_P702_MY2021_Rx" SG_ 500 Dsp_GetCDTOCDData_Rq 1;
BA_ "GenSigSendType" SG_ 500 Dsp_GetCDTOCDData_Rq 3;
BA_ "U_U55X_MY2022_Tx" SG_ 500 Dsp_FolderNumber_Rq 1;
BA_ "U_CD542_MY2021_Tx" SG_ 500 Dsp_FolderNumber_Rq 1;
BA_ "U_T6_MCA_MY2020_Tx" SG_ 500 Dsp_FolderNumber_Rq 1;
BA_ "U_P702_MY2021_Tx" SG_ 500 Dsp_FolderNumber_Rq 1;
BA_ "U_U55X_MY2022_Rx" SG_ 500 Dsp_FolderNumber_Rq 1;
BA_ "U_CD542_MY2021_Rx" SG_ 500 Dsp_FolderNumber_Rq 1;
BA_ "U_T6_MCA_MY2020_Rx" SG_ 500 Dsp_FolderNumber_Rq 1;
BA_ "U_P702_MY2021_Rx" SG_ 500 Dsp_FolderNumber_Rq 1;
BA_ "U_U55X_MY2022_Tx" SG_ 500 Dsp_CutItem_Rq 1;
BA_ "U_CD542_MY2021_Tx" SG_ 500 Dsp_CutItem_Rq 1;
BA_ "U_T6_MCA_MY2020_Tx" SG_ 500 Dsp_CutItem_Rq 1;
BA_ "U_P702_MY2021_Tx" SG_ 500 Dsp_CutItem_Rq 1;
BA_ "U_U55X_MY2022_Rx" SG_ 500 Dsp_CutItem_Rq 1;
BA_ "U_CD542_MY2021_Rx" SG_ 500 Dsp_CutItem_Rq 1;
BA_ "U_T6_MCA_MY2020_Rx" SG_ 500 Dsp_CutItem_Rq 1;
BA_ "U_P702_MY2021_Rx" SG_ 500 Dsp_CutItem_Rq 1;
BA_ "U_U55X_MY2022_Tx" SG_ 500 Dsp_AudioSourceSel_Rq 1;
BA_ "U_CD542_MY2021_Tx" SG_ 500 Dsp_AudioSourceSel_Rq 1;
BA_ "U_T6_MCA_MY2020_Tx" SG_ 500 Dsp_AudioSourceSel_Rq 1;
BA_ "U_P702_MY2021_Tx" SG_ 500 Dsp_AudioSourceSel_Rq 1;
BA_ "U_U55X_MY2022_Rx" SG_ 500 Dsp_AudioSourceSel_Rq 1;
BA_ "U_CD542_MY2021_Rx" SG_ 500 Dsp_AudioSourceSel_Rq 1;
BA_ "U_T6_MCA_MY2020_Rx" SG_ 500 Dsp_AudioSourceSel_Rq 1;
BA_ "U_P702_MY2021_Rx" SG_ 500 Dsp_AudioSourceSel_Rq 1;
BA_ "GenSigSendType" SG_ 500 Dsp_AudioSourceSel_Rq 3;
BA_ "U_U55X_MY2022_Tx" SG_ 503 Dsp_PlayFrstTrInFldr_Rq 1;
BA_ "U_CD542_MY2021_Tx" SG_ 503 Dsp_PlayFrstTrInFldr_Rq 1;
BA_ "U_T6_MCA_MY2020_Tx" SG_ 503 Dsp_PlayFrstTrInFldr_Rq 1;
BA_ "U_P702_MY2021_Tx" SG_ 503 Dsp_PlayFrstTrInFldr_Rq 1;
BA_ "U_U55X_MY2022_Rx" SG_ 503 Dsp_PlayFrstTrInFldr_Rq 1;
BA_ "U_CD542_MY2021_Rx" SG_ 503 Dsp_PlayFrstTrInFldr_Rq 1;
BA_ "U_T6_MCA_MY2020_Rx" SG_ 503 Dsp_PlayFrstTrInFldr_Rq 1;
BA_ "U_P702_MY2021_Rx" SG_ 503 Dsp_PlayFrstTrInFldr_Rq 1;
BA_ "U_U55X_MY2022_Tx" SG_ 503 Dsp_ItemIndex_Rq 1;
BA_ "U_CD542_MY2021_Tx" SG_ 503 Dsp_ItemIndex_Rq 1;
BA_ "U_T6_MCA_MY2020_Tx" SG_ 503 Dsp_ItemIndex_Rq 1;
BA_ "U_P702_MY2021_Tx" SG_ 503 Dsp_ItemIndex_Rq 1;
BA_ "U_U55X_MY2022_Rx" SG_ 503 Dsp_ItemIndex_Rq 1;
BA_ "U_CD542_MY2021_Rx" SG_ 503 Dsp_ItemIndex_Rq 1;
BA_ "U_T6_MCA_MY2020_Rx" SG_ 503 Dsp_ItemIndex_Rq 1;
BA_ "U_P702_MY2021_Rx" SG_ 503 Dsp_ItemIndex_Rq 1;
BA_ "U_U55X_MY2022_Tx" SG_ 503 Dsp_FolderNumber3_Rq 1;
BA_ "U_CD542_MY2021_Tx" SG_ 503 Dsp_FolderNumber3_Rq 1;
BA_ "U_T6_MCA_MY2020_Tx" SG_ 503 Dsp_FolderNumber3_Rq 1;
BA_ "U_P702_MY2021_Tx" SG_ 503 Dsp_FolderNumber3_Rq 1;
BA_ "U_U55X_MY2022_Rx" SG_ 503 Dsp_FolderNumber3_Rq 1;
BA_ "U_CD542_MY2021_Rx" SG_ 503 Dsp_FolderNumber3_Rq 1;
BA_ "U_T6_MCA_MY2020_Rx" SG_ 503 Dsp_FolderNumber3_Rq 1;
BA_ "U_P702_MY2021_Rx" SG_ 503 Dsp_FolderNumber3_Rq 1;
BA_ "U_U55X_MY2022_Tx" SG_ 503 Dsp_AudioSourceSel3_Rq 1;
BA_ "U_CD542_MY2021_Tx" SG_ 503 Dsp_AudioSourceSel3_Rq 1;
BA_ "U_T6_MCA_MY2020_Tx" SG_ 503 Dsp_AudioSourceSel3_Rq 1;
BA_ "U_P702_MY2021_Tx" SG_ 503 Dsp_AudioSourceSel3_Rq 1;
BA_ "U_U55X_MY2022_Rx" SG_ 503 Dsp_AudioSourceSel3_Rq 1;
BA_ "U_CD542_MY2021_Rx" SG_ 503 Dsp_AudioSourceSel3_Rq 1;
BA_ "U_T6_MCA_MY2020_Rx" SG_ 503 Dsp_AudioSourceSel3_Rq 1;
BA_ "U_P702_MY2021_Rx" SG_ 503 Dsp_AudioSourceSel3_Rq 1;
BA_ "GenSigSendType" SG_ 503 Dsp_AudioSourceSel3_Rq 3;
BA_ "U_U55X_MY2022_Tx" SG_ 412 LBC2_StartItemInd 1;
BA_ "U_CD542_MY2021_Tx" SG_ 412 LBC2_StartItemInd 1;
BA_ "U_T6_MCA_MY2020_Tx" SG_ 412 LBC2_StartItemInd 1;
BA_ "U_P702_MY2021_Tx" SG_ 412 LBC2_StartItemInd 1;
BA_ "U_U55X_MY2022_Rx" SG_ 412 LBC2_StartItemInd 1;
BA_ "U_CD542_MY2021_Rx" SG_ 412 LBC2_StartItemInd 1;
BA_ "U_T6_MCA_MY2020_Rx" SG_ 412 LBC2_StartItemInd 1;
BA_ "U_P702_MY2021_Rx" SG_ 412 LBC2_StartItemInd 1;
BA_ "U_U55X_MY2022_Tx" SG_ 412 LBC2_SetListServ 1;
BA_ "U_CD542_MY2021_Tx" SG_ 412 LBC2_SetListServ 1;
BA_ "U_T6_MCA_MY2020_Tx" SG_ 412 LBC2_SetListServ 1;
BA_ "U_P702_MY2021_Tx" SG_ 412 LBC2_SetListServ 1;
BA_ "U_U55X_MY2022_Rx" SG_ 412 LBC2_SetListServ 1;
BA_ "U_CD542_MY2021_Rx" SG_ 412 LBC2_SetListServ 1;
BA_ "U_T6_MCA_MY2020_Rx" SG_ 412 LBC2_SetListServ 1;
BA_ "U_P702_MY2021_Rx" SG_ 412 LBC2_SetListServ 1;
BA_ "U_U55X_MY2022_Tx" SG_ 412 LBC2_Opcode 1;
BA_ "U_CD542_MY2021_Tx" SG_ 412 LBC2_Opcode 1;
BA_ "U_T6_MCA_MY2020_Tx" SG_ 412 LBC2_Opcode 1;
BA_ "U_P702_MY2021_Tx" SG_ 412 LBC2_Opcode 1;
BA_ "U_U55X_MY2022_Rx" SG_ 412 LBC2_Opcode 1;
BA_ "U_CD542_MY2021_Rx" SG_ 412 LBC2_Opcode 1;
BA_ "U_T6_MCA_MY2020_Rx" SG_ 412 LBC2_Opcode 1;
BA_ "U_P702_MY2021_Rx" SG_ 412 LBC2_Opcode 1;
BA_ "GenSigSendType" SG_ 412 LBC2_Opcode 3;
BA_ "U_U55X_MY2022_Tx" SG_ 412 LBC2_NbrOfItems 1;
BA_ "U_CD542_MY2021_Tx" SG_ 412 LBC2_NbrOfItems 1;
BA_ "U_T6_MCA_MY2020_Tx" SG_ 412 LBC2_NbrOfItems 1;
BA_ "U_P702_MY2021_Tx" SG_ 412 LBC2_NbrOfItems 1;
BA_ "U_U55X_MY2022_Rx" SG_ 412 LBC2_NbrOfItems 1;
BA_ "U_CD542_MY2021_Rx" SG_ 412 LBC2_NbrOfItems 1;
BA_ "U_T6_MCA_MY2020_Rx" SG_ 412 LBC2_NbrOfItems 1;
BA_ "U_P702_MY2021_Rx" SG_ 412 LBC2_NbrOfItems 1;
BA_ "U_U55X_MY2022_Tx" SG_ 412 LBC2_ItemIndex 1;
BA_ "U_CD542_MY2021_Tx" SG_ 412 LBC2_ItemIndex 1;
BA_ "U_T6_MCA_MY2020_Tx" SG_ 412 LBC2_ItemIndex 1;
BA_ "U_P702_MY2021_Tx" SG_ 412 LBC2_ItemIndex 1;
BA_ "U_U55X_MY2022_Rx" SG_ 412 LBC2_ItemIndex 1;
BA_ "U_CD542_MY2021_Rx" SG_ 412 LBC2_ItemIndex 1;
BA_ "U_T6_MCA_MY2020_Rx" SG_ 412 LBC2_ItemIndex 1;
BA_ "U_U55X_MY2022_Tx" SG_ 412 LBC2_ActiveListID 1;
BA_ "U_CD542_MY2021_Tx" SG_ 412 LBC2_ActiveListID 1;
BA_ "U_T6_MCA_MY2020_Tx" SG_ 412 LBC2_ActiveListID 1;
BA_ "U_P702_MY2021_Tx" SG_ 412 LBC2_ActiveListID 1;
BA_ "U_U55X_MY2022_Rx" SG_ 412 LBC2_ActiveListID 1;
BA_ "U_CD542_MY2021_Rx" SG_ 412 LBC2_ActiveListID 1;
BA_ "U_T6_MCA_MY2020_Rx" SG_ 412 LBC2_ActiveListID 1;
BA_ "U_P702_MY2021_Rx" SG_ 412 LBC2_ActiveListID 1;
BA_ "U_U55X_MY2022_Tx" SG_ 493 Dsp_StatLiScanCancel_Rq 1;
BA_ "U_CD542_MY2021_Tx" SG_ 493 Dsp_StatLiScanCancel_Rq 1;
BA_ "U_T6_MCA_MY2020_Tx" SG_ 493 Dsp_StatLiScanCancel_Rq 1;
BA_ "U_P702_MY2021_Tx" SG_ 493 Dsp_StatLiScanCancel_Rq 1;
BA_ "U_U55X_MY2022_Rx" SG_ 493 Dsp_StatLiScanCancel_Rq 1;
BA_ "U_CD542_MY2021_Rx" SG_ 493 Dsp_StatLiScanCancel_Rq 1;
BA_ "U_T6_MCA_MY2020_Rx" SG_ 493 Dsp_StatLiScanCancel_Rq 1;
BA_ "U_P702_MY2021_Rx" SG_ 493 Dsp_StatLiScanCancel_Rq 1;
BA_ "GenSigSendType" SG_ 493 Dsp_StatLiScanCancel_Rq 3;
BA_ "U_U55X_MY2022_Tx" SG_ 493 Dsp_StationList_Rq 1;
BA_ "U_CD542_MY2021_Tx" SG_ 493 Dsp_StationList_Rq 1;
BA_ "U_T6_MCA_MY2020_Tx" SG_ 493 Dsp_StationList_Rq 1;
BA_ "U_P702_MY2021_Tx" SG_ 493 Dsp_StationList_Rq 1;
BA_ "U_U55X_MY2022_Rx" SG_ 493 Dsp_StationList_Rq 1;
BA_ "U_CD542_MY2021_Rx" SG_ 493 Dsp_StationList_Rq 1;
BA_ "U_T6_MCA_MY2020_Rx" SG_ 493 Dsp_StationList_Rq 1;
BA_ "U_P702_MY2021_Rx" SG_ 493 Dsp_StationList_Rq 1;
BA_ "GenSigSendType" SG_ 493 Dsp_StationList_Rq 3;
BA_ "U_U55X_MY2022_Tx" SG_ 493 Dsp_StartIndex3_Rq 1;
BA_ "U_CD542_MY2021_Tx" SG_ 493 Dsp_StartIndex3_Rq 1;
BA_ "U_T6_MCA_MY2020_Tx" SG_ 493 Dsp_StartIndex3_Rq 1;
BA_ "U_P702_MY2021_Tx" SG_ 493 Dsp_StartIndex3_Rq 1;
BA_ "U_U55X_MY2022_Rx" SG_ 493 Dsp_StartIndex3_Rq 1;
BA_ "U_CD542_MY2021_Rx" SG_ 493 Dsp_StartIndex3_Rq 1;
BA_ "U_T6_MCA_MY2020_Rx" SG_ 493 Dsp_StartIndex3_Rq 1;
BA_ "U_P702_MY2021_Rx" SG_ 493 Dsp_StartIndex3_Rq 1;
BA_ "U_U55X_MY2022_Tx" SG_ 493 Dsp_RefreshFlag 1;
BA_ "U_CD542_MY2021_Tx" SG_ 493 Dsp_RefreshFlag 1;
BA_ "U_T6_MCA_MY2020_Tx" SG_ 493 Dsp_RefreshFlag 1;
BA_ "U_P702_MY2021_Tx" SG_ 493 Dsp_RefreshFlag 1;
BA_ "U_U55X_MY2022_Rx" SG_ 493 Dsp_RefreshFlag 1;
BA_ "U_CD542_MY2021_Rx" SG_ 493 Dsp_RefreshFlag 1;
BA_ "U_T6_MCA_MY2020_Rx" SG_ 493 Dsp_RefreshFlag 1;
BA_ "U_P702_MY2021_Rx" SG_ 493 Dsp_RefreshFlag 1;
BA_ "U_U55X_MY2022_Tx" SG_ 493 Dsp_PTYCode_Rq 1;
BA_ "U_CD542_MY2021_Tx" SG_ 493 Dsp_PTYCode_Rq 1;
BA_ "U_T6_MCA_MY2020_Tx" SG_ 493 Dsp_PTYCode_Rq 1;
BA_ "U_P702_MY2021_Tx" SG_ 493 Dsp_PTYCode_Rq 1;
BA_ "U_U55X_MY2022_Rx" SG_ 493 Dsp_PTYCode_Rq 1;
BA_ "U_CD542_MY2021_Rx" SG_ 493 Dsp_PTYCode_Rq 1;
BA_ "U_T6_MCA_MY2020_Rx" SG_ 493 Dsp_PTYCode_Rq 1;
BA_ "U_P702_MY2021_Rx" SG_ 493 Dsp_PTYCode_Rq 1;
BA_ "U_U55X_MY2022_Tx" SG_ 493 Dsp_ListSize_Rq 1;
BA_ "U_CD542_MY2021_Tx" SG_ 493 Dsp_ListSize_Rq 1;
BA_ "U_T6_MCA_MY2020_Tx" SG_ 493 Dsp_ListSize_Rq 1;
BA_ "U_P702_MY2021_Tx" SG_ 493 Dsp_ListSize_Rq 1;
BA_ "U_U55X_MY2022_Rx" SG_ 493 Dsp_ListSize_Rq 1;
BA_ "U_CD542_MY2021_Rx" SG_ 493 Dsp_ListSize_Rq 1;
BA_ "U_T6_MCA_MY2020_Rx" SG_ 493 Dsp_ListSize_Rq 1;
BA_ "U_P702_MY2021_Rx" SG_ 493 Dsp_ListSize_Rq 1;
BA_ "U_U55X_MY2022_Tx" SG_ 493 Dsp_AFJump_Rq 1;
BA_ "U_CD542_MY2021_Tx" SG_ 493 Dsp_AFJump_Rq 1;
BA_ "U_T6_MCA_MY2020_Tx" SG_ 493 Dsp_AFJump_Rq 1;
BA_ "U_P702_MY2021_Tx" SG_ 493 Dsp_AFJump_Rq 1;
BA_ "U_U55X_MY2022_Rx" SG_ 493 Dsp_AFJump_Rq 1;
BA_ "U_CD542_MY2021_Rx" SG_ 493 Dsp_AFJump_Rq 1;
BA_ "U_T6_MCA_MY2020_Rx" SG_ 493 Dsp_AFJump_Rq 1;
BA_ "U_P702_MY2021_Rx" SG_ 493 Dsp_AFJump_Rq 1;
BA_ "GenSigSendType" SG_ 493 Dsp_AFJump_Rq 3;
BA_ "U_U55X_MY2022_Tx" SG_ 511 SdarsAudioRtng_D_Rq 1;
BA_ "U_CD542_MY2021_Tx" SG_ 511 SdarsAudioRtng_D_Rq 1;
BA_ "U_U55X_MY2022_Rx" SG_ 511 SdarsAudioRtng_D_Rq 1;
BA_ "U_T6_MCA_MY2020_Rx" SG_ 511 SdarsAudioRtng_D_Rq 1;
BA_ "GenSigSendType" SG_ 511 SdarsAudioRtng_D_Rq 3;
BA_ "U_U55X_MY2022_Tx" SG_ 511 Dsp_TUStartIndex2_Rq 1;
BA_ "U_CD542_MY2021_Tx" SG_ 511 Dsp_TUStartIndex2_Rq 1;
BA_ "U_T6_MCA_MY2020_Tx" SG_ 511 Dsp_TUStartIndex2_Rq 1;
BA_ "U_P702_MY2021_Tx" SG_ 511 Dsp_TUStartIndex2_Rq 1;
BA_ "U_U55X_MY2022_Rx" SG_ 511 Dsp_TUStartIndex2_Rq 1;
BA_ "U_CD542_MY2021_Rx" SG_ 511 Dsp_TUStartIndex2_Rq 1;
BA_ "U_T6_MCA_MY2020_Rx" SG_ 511 Dsp_TUStartIndex2_Rq 1;
BA_ "U_P702_MY2021_Rx" SG_ 511 Dsp_TUStartIndex2_Rq 1;
BA_ "U_U55X_MY2022_Tx" SG_ 511 Dsp_TUPresetArea_Rq 1;
BA_ "U_CD542_MY2021_Tx" SG_ 511 Dsp_TUPresetArea_Rq 1;
BA_ "U_T6_MCA_MY2020_Tx" SG_ 511 Dsp_TUPresetArea_Rq 1;
BA_ "U_P702_MY2021_Tx" SG_ 511 Dsp_TUPresetArea_Rq 1;
BA_ "U_U55X_MY2022_Rx" SG_ 511 Dsp_TUPresetArea_Rq 1;
BA_ "U_CD542_MY2021_Rx" SG_ 511 Dsp_TUPresetArea_Rq 1;
BA_ "U_T6_MCA_MY2020_Rx" SG_ 511 Dsp_TUPresetArea_Rq 1;
BA_ "U_P702_MY2021_Rx" SG_ 511 Dsp_TUPresetArea_Rq 1;
BA_ "GenSigSendType" SG_ 511 Dsp_TUPresetArea_Rq 3;
BA_ "U_U55X_MY2022_Tx" SG_ 511 Dsp_TUNbrOfPresets_Rq 1;
BA_ "U_CD542_MY2021_Tx" SG_ 511 Dsp_TUNbrOfPresets_Rq 1;
BA_ "U_T6_MCA_MY2020_Tx" SG_ 511 Dsp_TUNbrOfPresets_Rq 1;
BA_ "U_P702_MY2021_Tx" SG_ 511 Dsp_TUNbrOfPresets_Rq 1;
BA_ "U_U55X_MY2022_Rx" SG_ 511 Dsp_TUNbrOfPresets_Rq 1;
BA_ "U_CD542_MY2021_Rx" SG_ 511 Dsp_TUNbrOfPresets_Rq 1;
BA_ "U_T6_MCA_MY2020_Rx" SG_ 511 Dsp_TUNbrOfPresets_Rq 1;
BA_ "U_P702_MY2021_Rx" SG_ 511 Dsp_TUNbrOfPresets_Rq 1;
BA_ "U_U55X_MY2022_Tx" SG_ 511 Dsp_SetCurrTUPreset_Rq 1;
BA_ "U_CD542_MY2021_Tx" SG_ 511 Dsp_SetCurrTUPreset_Rq 1;
BA_ "U_T6_MCA_MY2020_Tx" SG_ 511 Dsp_SetCurrTUPreset_Rq 1;
BA_ "U_P702_MY2021_Tx" SG_ 511 Dsp_SetCurrTUPreset_Rq 1;
BA_ "U_U55X_MY2022_Rx" SG_ 511 Dsp_SetCurrTUPreset_Rq 1;
BA_ "U_CD542_MY2021_Rx" SG_ 511 Dsp_SetCurrTUPreset_Rq 1;
BA_ "U_T6_MCA_MY2020_Rx" SG_ 511 Dsp_SetCurrTUPreset_Rq 1;
BA_ "U_P702_MY2021_Rx" SG_ 511 Dsp_SetCurrTUPreset_Rq 1;
BA_ "GenSigSendType" SG_ 511 Dsp_SetCurrTUPreset_Rq 3;
BA_ "U_U55X_MY2022_Tx" SG_ 511 Dsp_SetCurrTUBand_Rq 1;
BA_ "U_CD542_MY2021_Tx" SG_ 511 Dsp_SetCurrTUBand_Rq 1;
BA_ "U_T6_MCA_MY2020_Tx" SG_ 511 Dsp_SetCurrTUBand_Rq 1;
BA_ "U_P702_MY2021_Tx" SG_ 511 Dsp_SetCurrTUBand_Rq 1;
BA_ "U_U55X_MY2022_Rx" SG_ 511 Dsp_SetCurrTUBand_Rq 1;
BA_ "U_CD542_MY2021_Rx" SG_ 511 Dsp_SetCurrTUBand_Rq 1;
BA_ "U_T6_MCA_MY2020_Rx" SG_ 511 Dsp_SetCurrTUBand_Rq 1;
BA_ "U_P702_MY2021_Rx" SG_ 511 Dsp_SetCurrTUBand_Rq 1;
BA_ "GenSigSendType" SG_ 511 Dsp_SetCurrTUBand_Rq 3;
BA_ "U_U55X_MY2022_Tx" SG_ 257 MFD_SetTagMode 1;
BA_ "U_CD542_MY2021_Tx" SG_ 257 MFD_SetTagMode 1;
BA_ "U_T6_MCA_MY2020_Tx" SG_ 257 MFD_SetTagMode 1;
BA_ "U_P702_MY2021_Tx" SG_ 257 MFD_SetTagMode 1;
BA_ "U_U55X_MY2022_Rx" SG_ 257 MFD_SetTagMode 1;
BA_ "U_CD542_MY2021_Rx" SG_ 257 MFD_SetTagMode 1;
BA_ "U_T6_MCA_MY2020_Rx" SG_ 257 MFD_SetTagMode 1;
BA_ "U_P702_MY2021_Rx" SG_ 257 MFD_SetTagMode 1;
BA_ "GenSigSendType" SG_ 257 MFD_SetTagMode 3;
BA_ "U_U55X_MY2022_Tx" SG_ 257 MFD_SetRBDSMode 1;
BA_ "U_CD542_MY2021_Tx" SG_ 257 MFD_SetRBDSMode 1;
BA_ "U_T6_MCA_MY2020_Tx" SG_ 257 MFD_SetRBDSMode 1;
BA_ "U_P702_MY2021_Tx" SG_ 257 MFD_SetRBDSMode 1;
BA_ "U_U55X_MY2022_Rx" SG_ 257 MFD_SetRBDSMode 1;
BA_ "U_CD542_MY2021_Rx" SG_ 257 MFD_SetRBDSMode 1;
BA_ "U_T6_MCA_MY2020_Rx" SG_ 257 MFD_SetRBDSMode 1;
BA_ "U_P702_MY2021_Rx" SG_ 257 MFD_SetRBDSMode 1;
BA_ "GenSigSendType" SG_ 257 MFD_SetRBDSMode 3;
BA_ "U_U55X_MY2022_Tx" SG_ 257 MFD_SetHDModeRq 1;
BA_ "U_CD542_MY2021_Tx" SG_ 257 MFD_SetHDModeRq 1;
BA_ "U_T6_MCA_MY2020_Tx" SG_ 257 MFD_SetHDModeRq 1;
BA_ "U_P702_MY2021_Tx" SG_ 257 MFD_SetHDModeRq 1;
BA_ "U_U55X_MY2022_Rx" SG_ 257 MFD_SetHDModeRq 1;
BA_ "U_CD542_MY2021_Rx" SG_ 257 MFD_SetHDModeRq 1;
BA_ "U_T6_MCA_MY2020_Rx" SG_ 257 MFD_SetHDModeRq 1;
BA_ "U_P702_MY2021_Rx" SG_ 257 MFD_SetHDModeRq 1;
BA_ "GenSigSendType" SG_ 257 MFD_SetHDModeRq 3;
BA_ "U_U55X_MY2022_Tx" SG_ 257 MFD_GetTagInfo 1;
BA_ "U_CD542_MY2021_Tx" SG_ 257 MFD_GetTagInfo 1;
BA_ "U_T6_MCA_MY2020_Tx" SG_ 257 MFD_GetTagInfo 1;
BA_ "U_P702_MY2021_Tx" SG_ 257 MFD_GetTagInfo 1;
BA_ "U_U55X_MY2022_Rx" SG_ 257 MFD_GetTagInfo 1;
BA_ "U_CD542_MY2021_Rx" SG_ 257 MFD_GetTagInfo 1;
BA_ "U_T6_MCA_MY2020_Rx" SG_ 257 MFD_GetTagInfo 1;
BA_ "U_P702_MY2021_Rx" SG_ 257 MFD_GetTagInfo 1;
BA_ "GenSigSendType" SG_ 257 MFD_GetTagInfo 3;
BA_ "U_U55X_MY2022_Tx" SG_ 713 SDARS_RDISP_WORD_Rx 1;
BA_ "U_CD542_MY2021_Tx" SG_ 713 SDARS_RDISP_WORD_Rx 1;
BA_ "U_T6_MCA_MY2020_Tx" SG_ 713 SDARS_RDISP_WORD_Rx 1;
BA_ "U_P702_MY2021_Tx" SG_ 713 SDARS_RDISP_WORD_Rx 1;
BA_ "U_U55X_MY2022_Rx" SG_ 713 SDARS_RDISP_WORD_Rx 1;
BA_ "U_CD542_MY2021_Rx" SG_ 713 SDARS_RDISP_WORD_Rx 1;
BA_ "U_T6_MCA_MY2020_Rx" SG_ 713 SDARS_RDISP_WORD_Rx 1;
BA_ "U_P702_MY2021_Rx" SG_ 713 SDARS_RDISP_WORD_Rx 1;
BA_ "U_CD542_MY2021_Rx" SG_ 382 EngMnfldChrg_Te_Actl 1;
BA_ "U_T6_MCA_MY2020_Rx" SG_ 382 EngMnfldChrg_Te_Actl 1;
BA_ "GenSigStartValue" SG_ 382 EngMnfldChrg_Te_Actl 126;
BA_ "GenSigStartValueInteger" SG_ 382 EngMnfldChrg_Te_Actl 126;
BA_ "U_CD542_MY2021_Rx" SG_ 382 EngInnrClnt_Te_Actl 1;
BA_ "GenSigStartValue" SG_ 382 EngInnrClnt_Te_Actl 126;
BA_ "GenSigStartValueInteger" SG_ 382 EngInnrClnt_Te_Actl 56;
BA_ "U_U55X_MY2022_Rx" SG_ 382 DcacOut2_Pw2_Dsply 1;
BA_ "U_U55X_MY2022_Rx" SG_ 382 DcacOut1_Pw2_Dsply 1;
BA_ "GenSigStartValue" SG_ 877 CabnAmb_Te_ActlAft 255;
BA_ "U_CD764_MY2022_Rx" SG_ 877 Rr_Third_Power_Btn_Stt 1;
BA_ "U_CD542_MY2021_Rx" SG_ 877 Rr_Third_Power_Btn_Stt 1;
BA_ "U_T6_MCA_MY2020_Rx" SG_ 877 Rr_Third_Power_Btn_Stt 1;
BA_ "U_P702_MY2021_Rx" SG_ 877 Rr_Third_Power_Btn_Stt 1;
BA_ "U_U55X_MY2022_Rx" SG_ 877 Rr_Third_Power_Btn_Stt 1;
BA_ "GenSigStartValue" SG_ 877 Rr_Third_Power_Btn_Stt 2;
BA_ "GenSigStartValueInteger" SG_ 877 Rr_Third_Power_Btn_Stt 2;
BA_ "U_CD764_MY2022_Rx" SG_ 877 Rr_Third_Floor_Btn_Stt 1;
BA_ "U_U55X_MY2022_Rx" SG_ 877 Rr_Third_Floor_Btn_Stt 1;
BA_ "U_CD542_MY2021_Rx" SG_ 877 Rr_Third_Floor_Btn_Stt 1;
BA_ "U_T6_MCA_MY2020_Rx" SG_ 877 Rr_Third_Floor_Btn_Stt 1;
BA_ "U_P702_MY2021_Rx" SG_ 877 Rr_Third_Floor_Btn_Stt 1;
BA_ "GenSigStartValue" SG_ 877 Rr_Third_Floor_Btn_Stt 2;
BA_ "GenSigStartValueInteger" SG_ 877 Rr_Third_Floor_Btn_Stt 2;
BA_ "U_CD764_MY2022_Rx" SG_ 877 Rr_Third_Auto_Btn_Stt 1;
BA_ "U_U55X_MY2022_Rx" SG_ 877 Rr_Third_Auto_Btn_Stt 1;
BA_ "U_CD542_MY2021_Rx" SG_ 877 Rr_Third_Auto_Btn_Stt 1;
BA_ "U_T6_MCA_MY2020_Rx" SG_ 877 Rr_Third_Auto_Btn_Stt 1;
BA_ "U_P702_MY2021_Rx" SG_ 877 Rr_Third_Auto_Btn_Stt 1;
BA_ "GenSigStartValue" SG_ 877 Rr_Third_Auto_Btn_Stt 2;
BA_ "GenSigStartValueInteger" SG_ 877 Rr_Third_Auto_Btn_Stt 2;
BA_ "U_CD764_MY2022_Rx" SG_ 877 Rr_Lock_Btn_Stt 1;
BA_ "U_U55X_MY2022_Rx" SG_ 877 Rr_Lock_Btn_Stt 1;
BA_ "U_CD542_MY2021_Rx" SG_ 877 Rr_Lock_Btn_Stt 1;
BA_ "U_T6_MCA_MY2020_Rx" SG_ 877 Rr_Lock_Btn_Stt 1;
BA_ "U_P702_MY2021_Rx" SG_ 877 Rr_Lock_Btn_Stt 1;
BA_ "GenSigStartValue" SG_ 877 Rr_Lock_Btn_Stt 2;
BA_ "GenSigStartValueInteger" SG_ 877 Rr_Lock_Btn_Stt 2;
BA_ "U_CD764_MY2022_Rx" SG_ 877 Rr_RHS_Blower_Indicate 1;
BA_ "U_U55X_MY2022_Rx" SG_ 877 Rr_RHS_Blower_Indicate 1;
BA_ "U_CD542_MY2021_Rx" SG_ 877 Rr_RHS_Blower_Indicate 1;
BA_ "U_T6_MCA_MY2020_Rx" SG_ 877 Rr_RHS_Blower_Indicate 1;
BA_ "GenSigStartValue" SG_ 877 Rr_RHS_Blower_Indicate 15;
BA_ "GenSigStartValueInteger" SG_ 877 Rr_RHS_Blower_Indicate 15;
BA_ "U_CD764_MY2022_Rx" SG_ 877 Rr_Third_Panel_Btn_Stt 1;
BA_ "U_U55X_MY2022_Rx" SG_ 877 Rr_Third_Panel_Btn_Stt 1;
BA_ "U_CD542_MY2021_Rx" SG_ 877 Rr_Third_Panel_Btn_Stt 1;
BA_ "U_T6_MCA_MY2020_Rx" SG_ 877 Rr_Third_Panel_Btn_Stt 1;
BA_ "U_P702_MY2021_Rx" SG_ 877 Rr_Third_Panel_Btn_Stt 1;
BA_ "GenSigStartValue" SG_ 877 Rr_Third_Panel_Btn_Stt 2;
BA_ "GenSigStartValueInteger" SG_ 877 Rr_Third_Panel_Btn_Stt 2;
BA_ "U_CD764_MY2022_Rx" SG_ 877 Rr_Synch_Btn_Stt 1;
BA_ "U_U55X_MY2022_Rx" SG_ 877 Rr_Synch_Btn_Stt 1;
BA_ "U_CD542_MY2021_Rx" SG_ 877 Rr_Synch_Btn_Stt 1;
BA_ "U_T6_MCA_MY2020_Rx" SG_ 877 Rr_Synch_Btn_Stt 1;
BA_ "U_P702_MY2021_Rx" SG_ 877 Rr_Synch_Btn_Stt 1;
BA_ "GenSigStartValue" SG_ 877 Rr_Synch_Btn_Stt 2;
BA_ "GenSigStartValueInteger" SG_ 877 Rr_Synch_Btn_Stt 2;
BA_ "U_CD764_MY2022_Rx" SG_ 877 AAR_Btn_Stt 1;
BA_ "U_CD542_MY2021_Rx" SG_ 877 AAR_Btn_Stt 1;
BA_ "U_U55X_MY2022_Rx" SG_ 877 AAR_Btn_Stt 1;
BA_ "U_T6_MCA_MY2020_Rx" SG_ 877 AAR_Btn_Stt 1;
BA_ "U_P702_MY2021_Rx" SG_ 877 AAR_Btn_Stt 1;
BA_ "GenSigStartValue" SG_ 877 AAR_Btn_Stt 2;
BA_ "GenSigStartValueInteger" SG_ 877 AAR_Btn_Stt 2;
BA_ "U_CD764_MY2022_Rx" SG_ 877 Heat_Btn_Stt 1;
BA_ "U_U55X_MY2022_Rx" SG_ 877 Heat_Btn_Stt 1;
BA_ "U_CD542_MY2021_Rx" SG_ 877 Heat_Btn_Stt 1;
BA_ "U_T6_MCA_MY2020_Rx" SG_ 877 Heat_Btn_Stt 1;
BA_ "U_P702_MY2021_Rx" SG_ 877 Heat_Btn_Stt 1;
BA_ "GenSigStartValue" SG_ 877 Heat_Btn_Stt 2;
BA_ "GenSigStartValueInteger" SG_ 877 Heat_Btn_Stt 2;
BA_ "U_CD764_MY2022_Rx" SG_ 592 RFA_BLEM_APIM_Tx 1;
BA_ "U_U55X_MY2022_Rx" SG_ 592 RFA_BLEM_APIM_Tx 1;
BA_ "U_CD542_MY2021_Rx" SG_ 592 RFA_BLEM_APIM_Tx 1;
BA_ "U_T6_MCA_MY2020_Rx" SG_ 592 RFA_BLEM_APIM_Tx 1;
BA_ "U_P702_MY2021_Rx" SG_ 592 RFA_BLEM_APIM_Tx 1;
BA_ "U_T6_MCA_MY2020_Tx" SG_ 600 APIM_RFA_BLEM_Tx 1;
BA_ "U_P702_MY2021_Tx" SG_ 600 APIM_RFA_BLEM_Tx 1;
BA_ "U_U55X_MY2022_Tx" SG_ 600 APIM_RFA_BLEM_Tx 1;
BA_ "U_CD542_MY2021_Tx" SG_ 600 APIM_RFA_BLEM_Tx 1;
BA_ "U_U55X_MY2022_Tx" SG_ 708 TMCSrvr_TMCClnt_WORD_Tx 1;
BA_ "U_CD542_MY2021_Tx" SG_ 708 TMCSrvr_TMCClnt_WORD_Tx 1;
BA_ "U_T6_MCA_MY2020_Tx" SG_ 708 TMCSrvr_TMCClnt_WORD_Tx 1;
BA_ "U_P702_MY2021_Tx" SG_ 708 TMCSrvr_TMCClnt_WORD_Tx 1;
BA_ "U_U55X_MY2022_Rx" SG_ 708 TMCSrvr_TMCClnt_WORD_Tx 1;
BA_ "U_CD542_MY2021_Rx" SG_ 708 TMCSrvr_TMCClnt_WORD_Tx 1;
BA_ "U_T6_MCA_MY2020_Rx" SG_ 708 TMCSrvr_TMCClnt_WORD_Tx 1;
BA_ "U_P702_MY2021_Rx" SG_ 708 TMCSrvr_TMCClnt_WORD_Tx 1;
BA_ "U_CD764_MY2022_Tx" SG_ 414 LBS2_ListStatus 1;
BA_ "U_U55X_MY2022_Tx" SG_ 414 LBS2_ListStatus 1;
BA_ "U_CD542_MY2021_Tx" SG_ 414 LBS2_ListStatus 1;
BA_ "U_T6_MCA_MY2020_Tx" SG_ 414 LBS2_ListStatus 1;
BA_ "U_P702_MY2021_Tx" SG_ 414 LBS2_ListStatus 1;
BA_ "U_P702_MY2021_Rx" SG_ 414 LBS2_ListStatus 1;
BA_ "U_CD542_MY2021_Rx" SG_ 414 LBS2_ListStatus 1;
BA_ "U_T6_MCA_MY2020_Rx" SG_ 414 LBS2_ListStatus 1;
BA_ "U_U55X_MY2022_Rx" SG_ 414 LBS2_ListStatus 1;
BA_ "GenSigSendType" SG_ 414 LBS2_ListStatus 3;
BA_ "U_CD764_MY2022_Tx" SG_ 414 LBS2_ParentID 1;
BA_ "U_U55X_MY2022_Tx" SG_ 414 LBS2_ParentID 1;
BA_ "U_CD542_MY2021_Tx" SG_ 414 LBS2_ParentID 1;
BA_ "U_T6_MCA_MY2020_Tx" SG_ 414 LBS2_ParentID 1;
BA_ "U_P702_MY2021_Tx" SG_ 414 LBS2_ParentID 1;
BA_ "U_P702_MY2021_Rx" SG_ 414 LBS2_ParentID 1;
BA_ "U_CD542_MY2021_Rx" SG_ 414 LBS2_ParentID 1;
BA_ "U_T6_MCA_MY2020_Rx" SG_ 414 LBS2_ParentID 1;
BA_ "U_U55X_MY2022_Rx" SG_ 414 LBS2_ParentID 1;
BA_ "U_CD764_MY2022_Tx" SG_ 414 LBS2_ListServer 1;
BA_ "U_U55X_MY2022_Tx" SG_ 414 LBS2_ListServer 1;
BA_ "U_CD542_MY2021_Tx" SG_ 414 LBS2_ListServer 1;
BA_ "U_T6_MCA_MY2020_Tx" SG_ 414 LBS2_ListServer 1;
BA_ "U_P702_MY2021_Tx" SG_ 414 LBS2_ListServer 1;
BA_ "U_P702_MY2021_Rx" SG_ 414 LBS2_ListServer 1;
BA_ "U_CD542_MY2021_Rx" SG_ 414 LBS2_ListServer 1;
BA_ "U_T6_MCA_MY2020_Rx" SG_ 414 LBS2_ListServer 1;
BA_ "U_U55X_MY2022_Rx" SG_ 414 LBS2_ListServer 1;
BA_ "U_CD764_MY2022_Tx" SG_ 414 LBS2_ListID 1;
BA_ "U_U55X_MY2022_Tx" SG_ 414 LBS2_ListID 1;
BA_ "U_CD542_MY2021_Tx" SG_ 414 LBS2_ListID 1;
BA_ "U_T6_MCA_MY2020_Tx" SG_ 414 LBS2_ListID 1;
BA_ "U_P702_MY2021_Tx" SG_ 414 LBS2_ListID 1;
BA_ "U_P702_MY2021_Rx" SG_ 414 LBS2_ListID 1;
BA_ "U_CD542_MY2021_Rx" SG_ 414 LBS2_ListID 1;
BA_ "U_T6_MCA_MY2020_Rx" SG_ 414 LBS2_ListID 1;
BA_ "U_U55X_MY2022_Rx" SG_ 414 LBS2_ListID 1;
BA_ "U_CD764_MY2022_Tx" SG_ 414 LBS2_EntryIndex 1;
BA_ "U_U55X_MY2022_Tx" SG_ 414 LBS2_EntryIndex 1;
BA_ "U_CD542_MY2021_Tx" SG_ 414 LBS2_EntryIndex 1;
BA_ "U_T6_MCA_MY2020_Tx" SG_ 414 LBS2_EntryIndex 1;
BA_ "U_P702_MY2021_Tx" SG_ 414 LBS2_EntryIndex 1;
BA_ "U_P702_MY2021_Rx" SG_ 414 LBS2_EntryIndex 1;
BA_ "U_CD542_MY2021_Rx" SG_ 414 LBS2_EntryIndex 1;
BA_ "U_T6_MCA_MY2020_Rx" SG_ 414 LBS2_EntryIndex 1;
BA_ "U_U55X_MY2022_Rx" SG_ 414 LBS2_EntryIndex 1;
BA_ "U_CD764_MY2022_Tx" SG_ 1239 StabBarCnnctLamp_D_Cstm 1;
BA_ "U_CD542_MY2021_Tx" SG_ 1239 StabBarCnnctLamp_D_Cstm 1;
BA_ "ECGUsedTxSignal" SG_ 1239 StabBarCnnctLamp_D_Cstm 1;
BA_ "U_CD764_MY2022_Rx" SG_ 1239 StabBarCnnctLamp_D_Cstm 1;
BA_ "GenSigSendType" SG_ 1239 StabBarCnnctLamp_D_Cstm 3;
BA_ "U_CD764_MY2022_Tx" SG_ 1239 SelDrvMdeCstmLamp_D_Rq 1;
BA_ "U_CD542_MY2021_Tx" SG_ 1239 SelDrvMdeCstmLamp_D_Rq 1;
BA_ "ECGUsedTxSignal" SG_ 1239 SelDrvMdeCstmLamp_D_Rq 1;
BA_ "U_CD764_MY2022_Rx" SG_ 1239 SelDrvMdeCstmLamp_D_Rq 1;
BA_ "GenSigSendType" SG_ 1239 SelDrvMdeCstmLamp_D_Rq 3;
BA_ "U_CD764_MY2022_Tx" SG_ 1239 SelDrvMdeCstm_D_RqDrv 1;
BA_ "U_CD542_MY2021_Tx" SG_ 1239 SelDrvMdeCstm_D_RqDrv 1;
BA_ "ECGUsedTxSignal" SG_ 1239 SelDrvMdeCstm_D_RqDrv 1;
BA_ "U_CD764_MY2022_Rx" SG_ 1239 SelDrvMdeCstm_D_RqDrv 1;
BA_ "GenSigSendType" SG_ 1239 SelDrvMdeCstm_D_RqDrv 3;
BA_ "U_CD764_MY2022_Tx" SG_ 1239 IndvMdeSuspCstm_No_Rq 1;
BA_ "U_CD542_MY2021_Tx" SG_ 1239 IndvMdeSuspCstm_No_Rq 1;
BA_ "ECGUsedTxSignal" SG_ 1239 IndvMdeSuspCstm_No_Rq 1;
BA_ "U_CD764_MY2022_Rx" SG_ 1239 IndvMdeSuspCstm_No_Rq 1;
BA_ "GenSigSendType" SG_ 1239 IndvMdeSuspCstm_No_Rq 3;
BA_ "GenSigStartValue" SG_ 1239 IndvMdeSuspCstm_No_Rq 15;
BA_ "U_CD764_MY2022_Tx" SG_ 1239 IndvMdeSteCstm_No_Rq 1;
BA_ "U_CD542_MY2021_Tx" SG_ 1239 IndvMdeSteCstm_No_Rq 1;
BA_ "ECGUsedTxSignal" SG_ 1239 IndvMdeSteCstm_No_Rq 1;
BA_ "U_CD764_MY2022_Rx" SG_ 1239 IndvMdeSteCstm_No_Rq 1;
BA_ "GenSigSendType" SG_ 1239 IndvMdeSteCstm_No_Rq 3;
BA_ "GenSigStartValue" SG_ 1239 IndvMdeSteCstm_No_Rq 15;
BA_ "U_CD764_MY2022_Tx" SG_ 1239 CstmDrvMdeMsgTxt_D_Rq 1;
BA_ "U_CD542_MY2021_Tx" SG_ 1239 CstmDrvMdeMsgTxt_D_Rq 1;
BA_ "ECGUsedTxSignal" SG_ 1239 CstmDrvMdeMsgTxt_D_Rq 1;
BA_ "U_CD764_MY2022_Rx" SG_ 1239 CstmDrvMdeMsgTxt_D_Rq 1;
BA_ "GenSigSendType" SG_ 1239 CstmDrvMdeMsgTxt_D_Rq 3;
BA_ "U_CD764_MY2022_Tx" SG_ 1239 ActvDrvMdeCstm_D2_Rq 1;
BA_ "U_CD542_MY2021_Tx" SG_ 1239 ActvDrvMdeCstm_D2_Rq 1;
BA_ "ECGUsedTxSignal" SG_ 1239 ActvDrvMdeCstm_D2_Rq 1;
BA_ "U_CD764_MY2022_Rx" SG_ 1239 ActvDrvMdeCstm_D2_Rq 1;
BA_ "GenSigSendType" SG_ 1239 ActvDrvMdeCstm_D2_Rq 3;
BA_ "GenSigStartValue" SG_ 1239 ActvDrvMdeCstm_D2_Rq 31;
BA_ "U_CD764_MY2022_Tx" SG_ 1239 SeatOccRearChime_B_Rq 1;
BA_ "ECGUsedTxSignal" SG_ 1239 SeatOccRearChime_B_Rq 1;
BA_ "U_CD764_MY2022_Rx" SG_ 1239 SeatOccRearChime_B_Rq 1;
BA_ "GenSigSendType" SG_ 1239 SeatOccRearChime_B_Rq 3;
BA_ "U_U55X_MY2022_Tx" SG_ 716 TMCSrvr_TMCClnt_WORD_Rx 1;
BA_ "U_CD542_MY2021_Tx" SG_ 716 TMCSrvr_TMCClnt_WORD_Rx 1;
BA_ "U_T6_MCA_MY2020_Tx" SG_ 716 TMCSrvr_TMCClnt_WORD_Rx 1;
BA_ "U_P702_MY2021_Tx" SG_ 716 TMCSrvr_TMCClnt_WORD_Rx 1;
BA_ "U_U55X_MY2022_Rx" SG_ 716 TMCSrvr_TMCClnt_WORD_Rx 1;
BA_ "U_CD542_MY2021_Rx" SG_ 716 TMCSrvr_TMCClnt_WORD_Rx 1;
BA_ "U_T6_MCA_MY2020_Rx" SG_ 716 TMCSrvr_TMCClnt_WORD_Rx 1;
BA_ "U_P702_MY2021_Rx" SG_ 716 TMCSrvr_TMCClnt_WORD_Rx 1;
BA_ "U_CD764_MY2022_Rx" SG_ 1013 ChrgToPcWkndSav_D_Stat 1;
BA_ "U_U55X_MY2022_Rx" SG_ 1013 ChrgToPcWkndSav_D_Stat 1;
BA_ "U_T6_MCA_MY2020_Rx" SG_ 1013 ChrgToPcWkndSav_D_Stat 1;
BA_ "U_P702_MY2021_Rx" SG_ 1013 ChrgToPcWkndSav_D_Stat 1;
BA_ "U_U55X_MY2022_Rx" SG_ 1013 ChrgToPcWkdySav_D_Stat 1;
BA_ "U_T6_MCA_MY2020_Rx" SG_ 1013 ChrgToPcWkdySav_D_Stat 1;
BA_ "U_P702_MY2021_Rx" SG_ 1013 ChrgToPcWkdySav_D_Stat 1;
BA_ "U_U55X_MY2022_Rx" SG_ 1013 ChrgProgIdSaved_D_Stat 1;
BA_ "U_T6_MCA_MY2020_Rx" SG_ 1013 ChrgProgIdSaved_D_Stat 1;
BA_ "U_P702_MY2021_Rx" SG_ 1013 ChrgProgIdSaved_D_Stat 1;
BA_ "U_U55X_MY2022_Rx" SG_ 1013 ChrgNowEnbl_B_Saved 1;
BA_ "U_T6_MCA_MY2020_Rx" SG_ 1013 ChrgNowEnbl_B_Saved 1;
BA_ "U_P702_MY2021_Rx" SG_ 1013 ChrgNowEnbl_B_Saved 1;
BA_ "U_U55X_MY2022_Rx" SG_ 1013 ChrgLocIdUnsAck_B_Stat 1;
BA_ "U_T6_MCA_MY2020_Rx" SG_ 1013 ChrgLocIdUnsAck_B_Stat 1;
BA_ "U_P702_MY2021_Rx" SG_ 1013 ChrgLocIdUnsAck_B_Stat 1;
BA_ "U_CD542_MY2021_Rx" SG_ 1013 ChrgLocIdCurnt_D_Sav 1;
BA_ "U_U55X_MY2022_Rx" SG_ 1013 ChrgLocIdCurnt_D_Sav 1;
BA_ "U_T6_MCA_MY2020_Rx" SG_ 1013 ChrgLocIdCurnt_D_Sav 1;
BA_ "U_P702_MY2021_Rx" SG_ 1013 ChrgLocIdCurnt_D_Sav 1;
BA_ "U_U55X_MY2022_Rx" SG_ 1013 ChrgPrflWknd_No_Actl 1;
BA_ "U_T6_MCA_MY2020_Rx" SG_ 1013 ChrgPrflWknd_No_Actl 1;
BA_ "U_P702_MY2021_Rx" SG_ 1013 ChrgPrflWknd_No_Actl 1;
BA_ "U_U55X_MY2022_Rx" SG_ 1013 ChrgPrflWkdy_No_Actl 1;
BA_ "U_T6_MCA_MY2020_Rx" SG_ 1013 ChrgPrflWkdy_No_Actl 1;
BA_ "U_P702_MY2021_Rx" SG_ 1013 ChrgPrflWkdy_No_Actl 1;
BA_ "U_U55X_MY2022_Rx" SG_ 641 ChrgGoTElement_B_Dsply_UB 1;
BA_ "U_T6_MCA_MY2020_Rx" SG_ 641 ChrgGoTElement_B_Dsply_UB 1;
BA_ "U_P702_MY2021_Rx" SG_ 641 ChrgGoTElement_B_Dsply_UB 1;
BA_ "U_CD542_MY2021_Rx" SG_ 641 ChrgGoTElement_B_Dsply_UB 1;
BA_ "U_U55X_MY2022_Rx" SG_ 641 ChrgGoTElement_B_Dsply 1;
BA_ "U_T6_MCA_MY2020_Rx" SG_ 641 ChrgGoTElement_B_Dsply 1;
BA_ "U_P702_MY2021_Rx" SG_ 641 ChrgGoTElement_B_Dsply 1;
BA_ "U_CD542_MY2021_Rx" SG_ 641 ChrgGoTElement_B_Dsply 1;
BA_ "GenSigSendType" SG_ 641 ChrgGoTElement_B_Dsply 3;
BA_ "U_CD764_MY2022_Rx" SG_ 641 BattChrgTrgtSoC_D_Rq 1;
BA_ "U_CD542_MY2021_Rx" SG_ 641 BattChrgTrgtSoC_D_Rq 1;
BA_ "U_T6_MCA_MY2020_Rx" SG_ 641 BattChrgTrgtSoC_D_Rq 1;
BA_ "U_CD764_MY2022_Rx" SG_ 641 BattChrgTrgtSoC_D_Rq_UB 1;
BA_ "U_CD542_MY2021_Rx" SG_ 641 BattChrgTrgtSoC_D_Rq_UB 1;
BA_ "U_T6_MCA_MY2020_Rx" SG_ 641 BattChrgTrgtSoC_D_Rq_UB 1;
BA_ "U_CD542_MY2021_Rx" SG_ 641 ChrgLocIdCurnt_D_Uns_UB 1;
BA_ "U_U55X_MY2022_Rx" SG_ 641 ChrgLocIdCurnt_D_Uns_UB 1;
BA_ "U_T6_MCA_MY2020_Rx" SG_ 641 ChrgLocIdCurnt_D_Uns_UB 1;
BA_ "U_P702_MY2021_Rx" SG_ 641 ChrgLocIdCurnt_D_Uns_UB 1;
BA_ "U_CD542_MY2021_Rx" SG_ 641 ChrgLocIdCurnt_D_Uns 1;
BA_ "U_U55X_MY2022_Rx" SG_ 641 ChrgLocIdCurnt_D_Uns 1;
BA_ "U_T6_MCA_MY2020_Rx" SG_ 641 ChrgLocIdCurnt_D_Uns 1;
BA_ "U_P702_MY2021_Rx" SG_ 641 ChrgLocIdCurnt_D_Uns 1;
BA_ "GenSigSendType" SG_ 641 ChrgLocIdCurnt_D_Uns 3;
BA_ "U_CD764_MY2022_Rx" SG_ 641 IgnPsswrdActv_B_Stat_UB 1;
BA_ "U_CD542_MY2021_Rx" SG_ 641 IgnPsswrdActv_B_Stat_UB 1;
BA_ "U_U55X_MY2022_Rx" SG_ 641 IgnPsswrdActv_B_Stat_UB 1;
BA_ "U_T6_MCA_MY2020_Rx" SG_ 641 IgnPsswrdActv_B_Stat_UB 1;
BA_ "U_P702_MY2021_Rx" SG_ 641 IgnPsswrdActv_B_Stat_UB 1;
BA_ "U_CD764_MY2022_Rx" SG_ 641 IgnPsswrdSetup_B_Rq_UB 1;
BA_ "U_CD542_MY2021_Rx" SG_ 641 IgnPsswrdSetup_B_Rq_UB 1;
BA_ "U_U55X_MY2022_Rx" SG_ 641 IgnPsswrdSetup_B_Rq_UB 1;
BA_ "U_T6_MCA_MY2020_Rx" SG_ 641 IgnPsswrdSetup_B_Rq_UB 1;
BA_ "U_P702_MY2021_Rx" SG_ 641 IgnPsswrdSetup_B_Rq_UB 1;
BA_ "U_CD764_MY2022_Rx" SG_ 641 IgnPsswrdLckout_B_Stat_UB 1;
BA_ "U_CD542_MY2021_Rx" SG_ 641 IgnPsswrdLckout_B_Stat_UB 1;
BA_ "U_U55X_MY2022_Rx" SG_ 641 IgnPsswrdLckout_B_Stat_UB 1;
BA_ "U_T6_MCA_MY2020_Rx" SG_ 641 IgnPsswrdLckout_B_Stat_UB 1;
BA_ "U_P702_MY2021_Rx" SG_ 641 IgnPsswrdLckout_B_Stat_UB 1;
BA_ "U_CD764_MY2022_Rx" SG_ 641 IgnPsswrdSetup_B_Rq 1;
BA_ "U_CD542_MY2021_Rx" SG_ 641 IgnPsswrdSetup_B_Rq 1;
BA_ "U_U55X_MY2022_Rx" SG_ 641 IgnPsswrdSetup_B_Rq 1;
BA_ "U_T6_MCA_MY2020_Rx" SG_ 641 IgnPsswrdSetup_B_Rq 1;
BA_ "U_P702_MY2021_Rx" SG_ 641 IgnPsswrdSetup_B_Rq 1;
BA_ "GenSigSendType" SG_ 641 IgnPsswrdSetup_B_Rq 3;
BA_ "U_CD764_MY2022_Rx" SG_ 641 IgnPsswrdLckout_B_Stat 1;
BA_ "U_CD542_MY2021_Rx" SG_ 641 IgnPsswrdLckout_B_Stat 1;
BA_ "U_U55X_MY2022_Rx" SG_ 641 IgnPsswrdLckout_B_Stat 1;
BA_ "U_T6_MCA_MY2020_Rx" SG_ 641 IgnPsswrdLckout_B_Stat 1;
BA_ "U_P702_MY2021_Rx" SG_ 641 IgnPsswrdLckout_B_Stat 1;
BA_ "GenSigSendType" SG_ 641 IgnPsswrdLckout_B_Stat 3;
BA_ "U_CD764_MY2022_Rx" SG_ 641 PaakCnnct_D_Stat_UB 1;
BA_ "U_CD542_MY2021_Rx" SG_ 641 PaakCnnct_D_Stat_UB 1;
BA_ "U_U55X_MY2022_Rx" SG_ 641 PaakCnnct_D_Stat_UB 1;
BA_ "U_T6_MCA_MY2020_Rx" SG_ 641 PaakCnnct_D_Stat_UB 1;
BA_ "U_P702_MY2021_Rx" SG_ 641 PaakCnnct_D_Stat_UB 1;
BA_ "U_CD764_MY2022_Rx" SG_ 641 PaakCnnct_D_Stat 1;
BA_ "U_CD542_MY2021_Rx" SG_ 641 PaakCnnct_D_Stat 1;
BA_ "U_U55X_MY2022_Rx" SG_ 641 PaakCnnct_D_Stat 1;
BA_ "U_T6_MCA_MY2020_Rx" SG_ 641 PaakCnnct_D_Stat 1;
BA_ "U_P702_MY2021_Rx" SG_ 641 PaakCnnct_D_Stat 1;
BA_ "GenSigSendType" SG_ 641 PaakCnnct_D_Stat 3;
BA_ "U_CD764_MY2022_Rx" SG_ 641 IgnPsswrdActv_B_Stat 1;
BA_ "U_CD542_MY2021_Rx" SG_ 641 IgnPsswrdActv_B_Stat 1;
BA_ "U_U55X_MY2022_Rx" SG_ 641 IgnPsswrdActv_B_Stat 1;
BA_ "U_T6_MCA_MY2020_Rx" SG_ 641 IgnPsswrdActv_B_Stat 1;
BA_ "U_P702_MY2021_Rx" SG_ 641 IgnPsswrdActv_B_Stat 1;
BA_ "GenSigSendType" SG_ 641 IgnPsswrdActv_B_Stat 3;
BA_ "U_CD542_MY2021_Rx" SG_ 641 ChrgGoTTouch_B_Stat_UB 1;
BA_ "U_U55X_MY2022_Rx" SG_ 641 ChrgGoTTouch_B_Stat_UB 1;
BA_ "U_T6_MCA_MY2020_Rx" SG_ 641 ChrgGoTTouch_B_Stat_UB 1;
BA_ "U_P702_MY2021_Rx" SG_ 641 ChrgGoTTouch_B_Stat_UB 1;
BA_ "U_CD542_MY2021_Rx" SG_ 641 ChrgGoTTouch_B_Stat 1;
BA_ "U_U55X_MY2022_Rx" SG_ 641 ChrgGoTTouch_B_Stat 1;
BA_ "U_T6_MCA_MY2020_Rx" SG_ 641 ChrgGoTTouch_B_Stat 1;
BA_ "U_P702_MY2021_Rx" SG_ 641 ChrgGoTTouch_B_Stat 1;
BA_ "GenSigSendType" SG_ 641 ChrgGoTTouch_B_Stat 3;
BA_ "U_CD542_MY2021_Rx" SG_ 641 ChrgGoTPrcond_D_Stat_UB 1;
BA_ "U_U55X_MY2022_Rx" SG_ 641 ChrgGoTPrcond_D_Stat_UB 1;
BA_ "U_T6_MCA_MY2020_Rx" SG_ 641 ChrgGoTPrcond_D_Stat_UB 1;
BA_ "U_P702_MY2021_Rx" SG_ 641 ChrgGoTPrcond_D_Stat_UB 1;
BA_ "U_CD542_MY2021_Rx" SG_ 641 ChrgGoTPrcond_D_Stat 1;
BA_ "U_U55X_MY2022_Rx" SG_ 641 ChrgGoTPrcond_D_Stat 1;
BA_ "U_T6_MCA_MY2020_Rx" SG_ 641 ChrgGoTPrcond_D_Stat 1;
BA_ "U_P702_MY2021_Rx" SG_ 641 ChrgGoTPrcond_D_Stat 1;
BA_ "U_CD542_MY2021_Rx" SG_ 641 ChrgGoTNext_D_Stat_UB 1;
BA_ "U_U55X_MY2022_Rx" SG_ 641 ChrgGoTNext_D_Stat_UB 1;
BA_ "U_T6_MCA_MY2020_Rx" SG_ 641 ChrgGoTNext_D_Stat_UB 1;
BA_ "U_P702_MY2021_Rx" SG_ 641 ChrgGoTNext_D_Stat_UB 1;
BA_ "U_CD542_MY2021_Rx" SG_ 641 ChrgGoTNext_D_Stat 1;
BA_ "U_U55X_MY2022_Rx" SG_ 641 ChrgGoTNext_D_Stat 1;
BA_ "U_T6_MCA_MY2020_Rx" SG_ 641 ChrgGoTNext_D_Stat 1;
BA_ "U_P702_MY2021_Rx" SG_ 641 ChrgGoTNext_D_Stat 1;
BA_ "GenSigSendType" SG_ 641 ChrgGoTNext_D_Stat 3;
BA_ "U_CD542_MY2021_Rx" SG_ 641 ChrgGoTMnte_D_Stat_UB 1;
BA_ "U_U55X_MY2022_Rx" SG_ 641 ChrgGoTMnte_D_Stat_UB 1;
BA_ "U_T6_MCA_MY2020_Rx" SG_ 641 ChrgGoTMnte_D_Stat_UB 1;
BA_ "U_P702_MY2021_Rx" SG_ 641 ChrgGoTMnte_D_Stat_UB 1;
BA_ "U_CD542_MY2021_Rx" SG_ 641 ChrgGoTMnte_D_Stat 1;
BA_ "U_U55X_MY2022_Rx" SG_ 641 ChrgGoTMnte_D_Stat 1;
BA_ "U_T6_MCA_MY2020_Rx" SG_ 641 ChrgGoTMnte_D_Stat 1;
BA_ "U_P702_MY2021_Rx" SG_ 641 ChrgGoTMnte_D_Stat 1;
BA_ "U_CD542_MY2021_Rx" SG_ 641 ChrgGoTHr_T_Stat_UB 1;
BA_ "U_U55X_MY2022_Rx" SG_ 641 ChrgGoTHr_T_Stat_UB 1;
BA_ "U_T6_MCA_MY2020_Rx" SG_ 641 ChrgGoTHr_T_Stat_UB 1;
BA_ "U_P702_MY2021_Rx" SG_ 641 ChrgGoTHr_T_Stat_UB 1;
BA_ "U_CD542_MY2021_Rx" SG_ 641 ChrgGoTHr_T_Stat 1;
BA_ "U_U55X_MY2022_Rx" SG_ 641 ChrgGoTHr_T_Stat 1;
BA_ "U_T6_MCA_MY2020_Rx" SG_ 641 ChrgGoTHr_T_Stat 1;
BA_ "U_P702_MY2021_Rx" SG_ 641 ChrgGoTHr_T_Stat 1;
BA_ "GenSigStartValue" SG_ 641 ChrgGoTHr_T_Stat 30;
BA_ "GenSigStartValueInteger" SG_ 641 ChrgGoTHr_T_Stat 30;
BA_ "U_CD542_MY2021_Rx" SG_ 641 ChrgGoTExtHtr_B_Stat_UB 1;
BA_ "U_U55X_MY2022_Rx" SG_ 641 ChrgGoTExtHtr_B_Stat_UB 1;
BA_ "U_T6_MCA_MY2020_Rx" SG_ 641 ChrgGoTExtHtr_B_Stat_UB 1;
BA_ "U_P702_MY2021_Rx" SG_ 641 ChrgGoTExtHtr_B_Stat_UB 1;
BA_ "U_CD542_MY2021_Rx" SG_ 641 ChrgGoTExtHtr_B_Stat 1;
BA_ "U_U55X_MY2022_Rx" SG_ 641 ChrgGoTExtHtr_B_Stat 1;
BA_ "U_T6_MCA_MY2020_Rx" SG_ 641 ChrgGoTExtHtr_B_Stat 1;
BA_ "U_P702_MY2021_Rx" SG_ 641 ChrgGoTExtHtr_B_Stat 1;
BA_ "GenSigSendType" SG_ 641 ChrgGoTExtHtr_B_Stat 3;
BA_ "U_CD542_MY2021_Rx" SG_ 641 ChrgGoTElement_D_Stat_UB 1;
BA_ "U_U55X_MY2022_Rx" SG_ 641 ChrgGoTElement_D_Stat_UB 1;
BA_ "U_T6_MCA_MY2020_Rx" SG_ 641 ChrgGoTElement_D_Stat_UB 1;
BA_ "U_P702_MY2021_Rx" SG_ 641 ChrgGoTElement_D_Stat_UB 1;
BA_ "U_CD542_MY2021_Rx" SG_ 641 ChrgGoTElement_D_Stat 1;
BA_ "U_U55X_MY2022_Rx" SG_ 641 ChrgGoTElement_D_Stat 1;
BA_ "U_T6_MCA_MY2020_Rx" SG_ 641 ChrgGoTElement_D_Stat 1;
BA_ "U_P702_MY2021_Rx" SG_ 641 ChrgGoTElement_D_Stat 1;
BA_ "GenSigSendType" SG_ 641 ChrgGoTElement_D_Stat 3;
BA_ "U_CD542_MY2021_Rx" SG_ 641 ChrgGoTAllOn_B_Stat_UB 1;
BA_ "U_U55X_MY2022_Rx" SG_ 641 ChrgGoTAllOn_B_Stat_UB 1;
BA_ "U_T6_MCA_MY2020_Rx" SG_ 641 ChrgGoTAllOn_B_Stat_UB 1;
BA_ "U_P702_MY2021_Rx" SG_ 641 ChrgGoTAllOn_B_Stat_UB 1;
BA_ "U_CD542_MY2021_Rx" SG_ 641 ChrgGoTAllOn_B_Stat 1;
BA_ "U_U55X_MY2022_Rx" SG_ 641 ChrgGoTAllOn_B_Stat 1;
BA_ "U_T6_MCA_MY2020_Rx" SG_ 641 ChrgGoTAllOn_B_Stat 1;
BA_ "U_P702_MY2021_Rx" SG_ 641 ChrgGoTAllOn_B_Stat 1;
BA_ "GenSigSendType" SG_ 641 ChrgGoTAllOn_B_Stat 3;
BA_ "U_CD764_MY2022_Rx" SG_ 641 TrlrAidMsgTxt_D2_Rq 1;
BA_ "U_U55X_MY2022_Rx" SG_ 641 TrlrAidMsgTxt_D2_Rq 1;
BA_ "U_CD542_MY2021_Rx" SG_ 641 TrlrAidMsgTxt_D2_Rq 1;
BA_ "U_T6_MCA_MY2020_Rx" SG_ 641 TrlrAidMsgTxt_D2_Rq 1;
BA_ "U_P702_MY2021_Rx" SG_ 641 TrlrAidMsgTxt_D2_Rq 1;
BA_ "GenSigSendType" SG_ 641 TrlrAidMsgTxt_D2_Rq 3;
BA_ "U_P702_MY2021_Rx" SG_ 641 TrlrAidEnbl_D2_Stat 1;
BA_ "U_CD764_MY2022_Rx" SG_ 641 TrlrAidEnbl_D2_Stat 1;
BA_ "U_U55X_MY2022_Rx" SG_ 641 TrlrAidEnbl_D2_Stat 1;
BA_ "U_CD542_MY2021_Rx" SG_ 641 TrlrAidEnbl_D2_Stat 1;
BA_ "U_T6_MCA_MY2020_Rx" SG_ 641 TrlrAidEnbl_D2_Stat 1;
BA_ "GenSigSendType" SG_ 641 TrlrAidEnbl_D2_Stat 3;
BA_ "U_CD764_MY2022_Rx" SG_ 641 TrlrAidMsgTxt_D2_Rq_UB 1;
BA_ "U_U55X_MY2022_Rx" SG_ 641 TrlrAidMsgTxt_D2_Rq_UB 1;
BA_ "U_CD542_MY2021_Rx" SG_ 641 TrlrAidMsgTxt_D2_Rq_UB 1;
BA_ "U_T6_MCA_MY2020_Rx" SG_ 641 TrlrAidMsgTxt_D2_Rq_UB 1;
BA_ "U_P702_MY2021_Rx" SG_ 641 TrlrAidMsgTxt_D2_Rq_UB 1;
BA_ "U_P702_MY2021_Rx" SG_ 641 TrlrAidEnbl_D2_Stat_UB 1;
BA_ "U_CD764_MY2022_Rx" SG_ 641 TrlrAidEnbl_D2_Stat_UB 1;
BA_ "U_U55X_MY2022_Rx" SG_ 641 TrlrAidEnbl_D2_Stat_UB 1;
BA_ "U_CD542_MY2021_Rx" SG_ 641 TrlrAidEnbl_D2_Stat_UB 1;
BA_ "U_T6_MCA_MY2020_Rx" SG_ 641 TrlrAidEnbl_D2_Stat_UB 1;
VAL_ 965 TrnkFrontPrim_B_Falt 1 "Fault" 0 "No_Fault" ;
VAL_ 965 TrnkFrontEmgcy_D_Stat 3 "NotDetermined" 2 "SwitchState2" 1 "SwitchState1" 0 "NotPressed" ;
VAL_ 965 PtWakeupActv4_B_Rq 1 "On" 0 "Off" ;
VAL_ 965 TrunkFrontOpen_D_Stat 3 "NotUsed" 2 "NotRestricted" 1 "Restricted" 0 "Null" ;
VAL_ 1104 DrvEngageLevel_D_Stat 7 "Faulty" 6 "NotUsed_2" 5 "NotUsed_1" 4 "Disengaged" 3 "Distracted" 2 "Attentive" 1 "Invalid" 0 "NotDetermined" ;
VAL_ 1104 DrvImpLvlConfid_D_Stat 7 "Faulty" 6 "NotUsed" 5 "High" 4 "MediumHigh" 3 "Medium" 2 "LowMedium" 1 "Low" 0 "NotDetermined" ;
VAL_ 1104 DrvImpairLvl_D_Stat 15 "Faulty" 14 "NotUsed_5" 13 "NotUsed_4" 12 "NotUsed_3" 11 "NotUsed_2" 10 "NotUsed_1" 9 "Incapacitated" 8 "Asleep" 7 "Microsleep" 6 "MostDrowsy" 5 "Drowsy_4" 4 "Drowsy_3" 3 "Drowsy_2" 2 "LeastDrowsy" 1 "Alert" 0 "NotDetermined" ;
VAL_ 1104 DrvEngLvlConfid_D_Stat 7 "Faulty" 6 "NotUsed" 5 "High" 4 "MediumHigh" 3 "Medium" 2 "LowMedium" 1 "Low" 0 "NotDetermined" ;
VAL_ 1104 DrvCamPassIR_D_Stat 3 "Faulty" 2 "Blocked" 1 "Ok" 0 "TemporaryUnavailable" ;
VAL_ 1104 DrvCamera_D_Stat 3 "Faulty" 2 "Blocked" 1 "Ok" 0 "TemporaryUnavailable" ;
VAL_ 1104 DrvCamDrvIR_D_Stat 3 "Faulty" 2 "Blocked" 1 "Ok" 0 "TemporaryUnavailable" ;
VAL_ 1104 DrvAttentZone_D_Stat 15 "Faulty" 14 "NotUsed_5" 13 "NotUsed_4" 12 "NotUsed_3" 11 "NotConfigured" 10 "DriverLap" 9 "PassengerSideWindow" 8 "DriverSideWindow" 7 "DriverSideMirror" 6 "RearviewMirror" 5 "PassengerSideMirror" 4 "Infotainment" 3 "Cluster" 2 "FrontWindshield" 1 "Other" 0 "NotDetermined" ;
VAL_ 1104 DrvAlertSt_D_Stat 3 "Faulty" 2 "EyesOffRoad" 1 "EyesOnRoad" 0 "NotDetermined" ;
VAL_ 773 StmsScrnPsngrOn_B_Rq 1 "On" 0 "Off" ;
VAL_ 773 SeatScrnPsngrOn_B_Rq 1 "On" 0 "Off" ;
VAL_ 773 SeatPsngrMem_D_Cmd 15 "NotUsed_7" 14 "NotUsed_6" 13 "NotUsed_5" 12 "NotUsed_4" 11 "NotUsed_3" 10 "NotUsed_2" 9 "NotUsed_1" 8 "RECALL_4" 7 "RECALL_3" 6 "RECALL_2" 5 "RECALL_1" 4 "STORE_4" 3 "STORE_3" 2 "STORE_2" 1 "STORE_1" 0 "Null" ;
VAL_ 773 MemSwtchPsngrFdbck_B_Rq 1 "Yes" 0 "No" ;
VAL_ 303 DrStatHood_D2_Actl 5 "NotUsed_2" 4 "NotUsed_1" 3 "Disabled" 2 "Ajar" 1 "Closed" 0 "NotDetermined" 7 "Faulty" 6 "NotUsed_3" ;
VAL_ 302 TrnkFrontRleas_B_Stat 1 "Request" 0 "NoRequest" ;
VAL_ 571 VehFalr_Pc_Est 127 "Faulty" 126 "NoDataExists" ;
VAL_ 571 TrlrTngLoad_Pc_Est 127 "Faulty" 126 "NoDataExists" ;
VAL_ 571 TrlrTngLoad_M_Est 2047 "Faulty" 2046 "NoDataExists" ;
VAL_ 571 VehPayloadAdd_M_Est 2047 "Faulty" 2046 "NoDataExists" ;
VAL_ 571 VehPayload_Pc_Est 127 "Faulty" 126 "NoDataExists" ;
VAL_ 571 VehPayload_M_Est 1023 "Faulty" 1022 "NoDataExists" ;
VAL_ 781 TrlrTireDual_D_Stat 15 "NotUsed_11" 14 "NotUsed_10" 13 "NotUsed_9" 12 "NotUsed_8" 11 "NotUsed_7" 10 "NotUsed_6" 9 "NotUsed_5" 8 "NotUsed_4" 7 "NotUsed_3" 6 "NotUsed_2" 5 "NotUsed_1" 4 "NotSupported" 3 "Invalid" 2 "InnerTire" 1 "OuterTire" 0 "SystemUnknown" ;
VAL_ 781 TrlrTireSys_D_Stat 15 "NotUsed" 14 "TiresNotTrained" 13 "TrainingComplete" 12 "TrainLMTire" 11 "TrainLRTire" 10 "TrainRMTire" 9 "TrainRRTire" 8 "TrainRFTire" 7 "TrainLFTire" 6 "RequestPressureThresh" 5 "RequestTireCount" 4 "SystemActive" 3 "TireLow" 2 "SensorFault" 1 "System Fault" 0 "SystemUnknown" ;
VAL_ 781 TrlrTireCnt_D_Stat 7 "Faulty" 6 "TwelveTire" 5 "EightTire" 4 "FourTireOneAxle" 3 "SixTire" 2 "FourTire" 1 "TwoTire" 0 "Unconfigured" ;
VAL_ 781 Chirp_D_RqTrlr 3 "NotUsed" 2 "Chirp_2" 1 "Chirp_1" 0 "NoRequest" ;
VAL_ 746 Con_BTAud_Shuffle_St 3 "OnTheFolderSelGroup" 2 "OnTheDevice" 1 "Off" 0 "Invalid" ;
VAL_ 746 Con_BTAud_Repeat_St 7 "Reserved3" 6 "Reserved2" 5 "Reserved1" 4 "RepeatOnDevice" 3 "RepeatOnFolder" 2 "RepeatOnTrack" 1 "Off" 0 "Invalid" ;
VAL_ 746 Con_BTAud_IntroScan_St 3 "OnTheFolderSelGroup" 2 "OnTheDevice" 1 "Off" 0 "Invalid" ;
VAL_ 746 Con_BTAud_Error_St 8 "NoDataInFolder" 7 "NoRespFromDevice" 6 "UnableToRead" 5 "NoDataOnDevice" 4 "FileSysNotSupported" 3 "DeviceNotSupported" 2 "InvalidFile" 1 "NoError" 0 "Invalid" ;
VAL_ 746 Con_BTAud_FunctStats_St 7 "Reserved2" 6 "Reserved1" 5 "Reserved" 4 "Reading" 3 "Ready" 2 "Initilization" 1 "Free" 0 "Invalid" ;
VAL_ 746 Con_BTAud_OpMode_St 7 "FastRewind20" 6 "FastRewind10" 5 "FastForward20" 4 "FastForward10" 3 "Pause" 2 "Play" 1 "Stop" 0 "Invalid" ;
VAL_ 479 DISP_SetVol_Source_Rq 5 "SetAudioVolume" 4 "SetVRvolume" 3 "SetPhoneVolume" 2 "SetPromptVolume" 1 "SetTAVolume" 0 "Inactive" ;
VAL_ 479 DISP_Setshaker_Rq 2 "On" 1 "Off" 0 "Inactive" ;
VAL_ 474 Nav_SetCurrStatMCCh_Rq 7 "MCChannel7" 6 "MCChannel6" 5 "MCChannel5" 4 "MCChannel4" 3 "MCChannel3" 2 "MCChannel2" 1 "MCChannel1" 0 "Inactive" ;
VAL_ 474 NAV_SetNEWSMode_Rq 0 "Inactive" 1 "NewsOn" 2 "NewsOff" ;
VAL_ 474 NAV_SetDSP_Rq 9 "Convertible" 8 "RearSeats" 7 "FrontSeats" 6 "Reserved3" 5 "Reserved2" 4 "Reserved1" 15 "Reserved" 0 "Inactive" 1 "All" 2 "Driver" 3 "Passenger" ;
VAL_ 474 NAV_SetCurrentStatOp_Rq 0 "Inactive" 1 "SetCurrentFrequency" 2 "SetCurrentPiCode" 3 "SetCurrentStation" ;
VAL_ 474 NAV_ARReqstrSystem_Rq 0 "FrontRequester" 1 "RearRequester" ;
VAL_ 474 NAV_ARReqstrPriority_Rq 0 "EmergencyServ" 1 "TelService" 2 "AutoAnswer" 3 "Ta" 4 "PttMutevoice" 5 "NavUserVoiceCmd" 6 "NavSysVoiceCmd" 7 "Radio" 8 "Disc" 9 "Alarm" 10 "Ptynews" 11 "Aux_ExtSource" 12 "BT_BTNavAndTelMute" 13 "ManualAudioMute" 14 "NotReq" ;
VAL_ 474 NAV_AROperationType_Rq 0 "Inactive" 1 "Requestaudioresource" 2 "Releaseaudioresource" 3 "Releaseallaudioresouces" 4 "Getresourceupdate" 5 "Getallresourceupdates" ;
VAL_ 474 NAV_ARAudioSource_Rq 15 "iPod" 14 "USB" 13 "BTAudio" 0 "AmfmRadio" 1 "FrontDisc" 2 "SDARS_DAB" 3 "InDashCdChanger" 4 "VoiceRecogniser" 5 "TelematicUnit" 6 "BluetoothPhone" 7 "RearDisc" 8 "APIM" 9 "FrontAuxInput" 10 "Navigation" 11 "RearAux" 12 "NotReq" ;
VAL_ 477 NAV_LoadEjectMode_Rq 0 "Inactive" 1 "Load" 2 "Eject" 3 "EndloadMode" ;
VAL_ 477 NAV_LoadEjectDisc_Rq 0 "Inactive" 1 "Disc1" 2 "Disc2" 3 "Disc3" 4 "Disc4" 5 "Disc5" 6 "Disc6" 7 "All" ;
VAL_ 260 MFD_SDARS_SetOpMode_Rq 7 "FastRewindSpeed2" 6 "FastRewindSpeed1" 5 "FastForwardSpeed2" 4 "FastForwardSpeed1" 3 "Pause" 2 "Play" 1 "Stop" 0 "Invalid" ;
VAL_ 260 SDARS_GetESN_Rq 1 "RequestESN" 0 "Invalid" ;
VAL_ 260 SDARS_SRReplay_Rq 2 "Disable" 1 "Enable" 0 "Inactive" ;
VAL_ 260 SDARS_FactoryReset_Rq 1 "ResetFactoryDefaults" 0 "Invalid" ;
VAL_ 476 Nav_SetAudioMixRatio_Rq 31 "Inactive" ;
VAL_ 476 NAV_SkipCatalouge_Rq 0 "Inactive" 1 "NextCatalouge" 2 "PerviousCatalouge" ;
VAL_ 476 NAV_SetOperationMode_Rq 7 "FastRewind20" 6 "FastRewind10" 5 "FastForward20" 4 "FastForward10" 3 "Pause" 2 "Play" 1 "Stop" 0 "Inactive" ;
VAL_ 476 NAV_SetDSPProgram_Rq 7 "Reserved2" 6 "Reserved1" 5 "Voice" 4 "Rock" 0 "Inactive" 1 "Normal" 2 "Pop" 3 "Classical" ;
VAL_ 490 HMI_SetCompression_Rq 0 "Inactive" 1 "On" 2 "Off" 3 "NotUsed" ;
VAL_ 490 HMI_SkipTrack_Rq 3 "NotUsed" 2 "Decrement" 1 "Increment" 0 "Inactive" ;
VAL_ 1001 AirSuspMsgTxt_D_Rq2 3 "NotUsed" 2 "Faulty" 1 "Override" 0 "NoMessage" ;
VAL_ 1001 PersIndexSuma_D_Actl 7 "Unused_3" 6 "Unused_2" 5 "Unused_1" 4 "Vehicle" 3 "PERS_4" 2 "PERS_3" 1 "PERS_2" 0 "PERS_1" ;
VAL_ 1245 RearDiffLckLamp_D_Cstm 3 "Not_Used" 2 "Flash" 1 "On" 0 "Off" ;
VAL_ 1245 FrontDiffLckLamp_D_Cstm 3 "Fast_Flash" 2 "Slow_Flash" 1 "On" 0 "Off" ;
VAL_ 1245 AwdMdeCstm_D_RqDrv 7 "Faulty" 6 "NotUsed_3" 5 "NotUsed_2" 4 "NotUsed_1" 3 "FourByFourLow" 2 "FourByFourHigh" 1 "FourByFourAuto" 0 "FourByTwo" ;
VAL_ 1245 SelDrvMdeAwd2_D_Cstm 31 "Faulty" 30 "NotUsed_17" 29 "NotUsed_16" 28 "NotUsed_15" 27 "NotUsed_14" 26 "NotUsed_13" 25 "NotUsed_12" 24 "NotUsed_11" 23 "NotUsed_10" 22 "NotUsed_9" 21 "NotUsed_8" 20 "CustomMode" 19 "OnePedalDrive" 18 "DragMode" 17 "EvLaterChargeMode" 16 "EvNowMode" 15 "TrackMode" 14 "RoughRoadMode" 13 "NotAvailable" 12 "HighSpeedDesertMode_Baja" 11 "SportAdaptiveMode" 10 "RockCrawlMode" 9 "MudRutsMode" 8 "SandMode" 7 "EconomyMode" 6 "GrassGravelSnow" 5 "TowHaulMode" 4 "SportMode" 3 "Normal_4L" 2 "Normal_4A" 1 "Normal_2H" 0 "NormalMode" ;
VAL_ 1242 EngExhMdeQuietCstm_D_Rq 7 "Faulty" 6 "NotUsed_2" 5 "NotUsed_1" 4 "Track" 3 "Sport" 2 "Normal" 1 "Stealth" 0 "Null" ;
VAL_ 1242 StopStrtCstm_D_Rq 3 "Faulty" 2 "On" 1 "Off" 0 "NotAvailable" ;
VAL_ 1242 SelDrvMdeCstmPt_D_Rq 31 "Faulty" 30 "NotUsed15" 29 "NotUsed14" 28 "NotUsed13" 27 "NotUsed12" 26 "NotUsed11" 25 "NotUsed10" 24 "NotUsed9" 23 "NotUsed8" 22 "NotUsed7" 21 "CustomMode" 20 "TrackMode" 19 "OnePedalDrive" 18 "EvLaterChargerMode" 17 "EvNowMode" 16 "DragMode" 15 "HighSpeedDesertMode_Baja" 14 "SportAdaptiveMode" 13 "NotAvailable_13" 12 "NotAvailable_12" 11 "NotAvailable_11" 10 "NotAvailable_10" 9 "RockCrawlMode" 8 "MudRutsMode" 7 "SandMode" 6 "EconomyMode" 5 "GrassGravelSnow" 4 "NotAvailable_04" 3 "TowHaulMode" 2 "NotAvailable_02" 1 "SportMode" 0 "NormalMode" ;
VAL_ 1022 TrlrTireTSensIRM_D_Stat 3 "Faulty" 2 "HighTempWarning" 1 "Normal" 0 "NotAvailable" ;
VAL_ 1022 TrlrTireTSensIRF_D_Stat 3 "Faulty" 2 "HighTempWarning" 1 "Normal" 0 "NotAvailable" ;
VAL_ 1022 TrlrTireIRR_T_Actl 255 "NotSupported" 254 "Invalid" ;
VAL_ 1022 TrlrTireIRM_T_Actl 255 "NotSupported" 254 "Invalid" ;
VAL_ 1022 TrlrTireILR_T_Actl 255 "NotSupported" 254 "Invalid" ;
VAL_ 1022 TrlrTireILM_T_Actl 255 "NotSupported" 254 "Invalid" ;
VAL_ 1022 TrlrTireILF_T_Actl 255 "NotSupported" 254 "Invalid" ;
VAL_ 1022 TrlrTireIRF_T_Actl 255 "NotSupported" 254 "Invalid" ;
VAL_ 1022 TrlrTireTSensIRR_D_Stat 3 "Faulty" 2 "HighTempWarning" 1 "Normal" 0 "NotAvailable" ;
VAL_ 1022 TrlrTireTSensILR_D_Stat 3 "Faulty" 2 "HighTempWarning" 1 "Normal" 0 "NotAvailable" ;
VAL_ 1022 TrlrTireTSensILM_D_Stat 3 "Faulty" 2 "HighTempWarning" 1 "Normal" 0 "NotAvailable" ;
VAL_ 1022 TrlrTireTSensILF_D_Stat 3 "Faulty" 2 "HighTempWarning" 1 "Normal" 0 "NotAvailable" ;
VAL_ 1021 TrlrTireSensIRR_D_Stat 15 "NotSupported" 14 "NotUsed10" 13 "NotUsed9" 12 "NotUsed8" 11 "NotUsed7" 10 "NotUsed6" 9 "NotUsed5" 8 "NotUsed4" 7 "NotUsed3" 6 "NotUsed2" 5 "NotUsed1" 4 "Alert" 3 "Fault" 2 "Low" 1 "Normal" 0 "Unknown" ;
VAL_ 1021 TrlrTireSensIRM_D_Stat 15 "NotSupported" 14 "NotUsed10" 13 "NotUsed9" 12 "NotUsed8" 11 "NotUsed7" 10 "NotUsed6" 9 "NotUsed5" 8 "NotUsed4" 7 "NotUsed3" 6 "NotUsed2" 5 "NotUsed1" 4 "Alert" 3 "Fault" 2 "Low" 1 "Normal" 0 "Unknown" ;
VAL_ 1021 TrlrTireSensIRF_D_Stat 15 "NotSupported" 14 "NotUsed10" 13 "NotUsed9" 12 "NotUsed8" 11 "NotUsed7" 10 "NotUsed6" 9 "NotUsed5" 8 "NotUsed4" 7 "NotUsed3" 6 "NotUsed2" 5 "NotUsed1" 4 "Alert" 3 "Fault" 2 "Low" 1 "Normal" 0 "Unknown" ;
VAL_ 1021 TrlrTireIRR_P_Actl 65534 "Invalid" 65535 "NotSupported" ;
VAL_ 1021 TrlrTireIRM_P_Actl 65534 "Invalid" 65535 "NotSupported" ;
VAL_ 1021 TrlrTireIRF_P_Actl 65534 "Invalid" 65535 "NotSupported" ;
VAL_ 1018 TrlrTireSensILR_D_Stat 15 "NotSupported" 14 "NotUsed10" 13 "NotUsed9" 12 "NotUsed8" 11 "NotUsed7" 10 "NotUsed6" 9 "NotUsed5" 8 "NotUsed4" 7 "NotUsed3" 6 "NotUsed2" 5 "NotUsed1" 4 "Alert" 3 "Fault" 2 "Low" 1 "Normal" 0 "Unknown" ;
VAL_ 1018 TrlrTireSensILM_D_Stat 15 "NotSupported" 14 "NotUsed10" 13 "NotUsed9" 12 "NotUsed8" 11 "NotUsed7" 10 "NotUsed6" 9 "NotUsed5" 8 "NotUsed4" 7 "NotUsed3" 6 "NotUsed2" 5 "NotUsed1" 4 "Alert" 3 "Fault" 2 "Low" 1 "Normal" 0 "Unknown" ;
VAL_ 1018 TrlrTireSensILF_D_Stat 15 "NotSupported" 14 "NotUsed10" 13 "NotUsed9" 12 "NotUsed8" 11 "NotUsed7" 10 "NotUsed6" 9 "NotUsed5" 8 "NotUsed4" 7 "NotUsed3" 6 "NotUsed2" 5 "NotUsed1" 4 "Alert" 3 "Fault" 2 "Low" 1 "Normal" 0 "Unknown" ;
VAL_ 1018 TrlrTireILR_P_Actl 65534 "Invalid" 65535 "NotSupported" ;
VAL_ 1018 TrlrTireILM_P_Actl 65534 "Invalid" 65535 "NotSupported" ;
VAL_ 1018 TrlrTireILF_P_Actl 65534 "Invalid" 65535 "NotSupported" ;
VAL_ 502 Dsp_FolderContent_Rq 2 "Inactive" 1 "RequestContentFromParentFolderOf" 0 "RequestContentFromParameterFolde" ;
VAL_ 502 Dsp_CutItem2_Rq 3 "Inactive" 2 "ThreeQuarterFromTheBeginningOneQ" 1 "End" 0 "Beginning" ;
VAL_ 502 Dsp_AudioSourceSel2_Rq 4 "Reserved" 3 "USB" 2 "BTAudio" 1 "CD" 0 "Inactive" ;
VAL_ 955 Tire_Temp_RF_Data 255 "NotSupported" 254 "Invalid" ;
VAL_ 955 Tire_Temp_ORR_Data 255 "NotSupported" 254 "Invalid" ;
VAL_ 955 Tire_Temp_OLR_Data 255 "NotSupported" 254 "Invalid" ;
VAL_ 955 Tire_Temp_LF_Data 255 "NotSupported" 254 "Invalid" ;
VAL_ 955 Tire_Temp_IRR_Data 255 "NotSupported" 254 "Invalid" ;
VAL_ 955 Tire_Temp_ILR_Data 255 "NotSupported" 254 "Invalid" ;
VAL_ 1116 TrlrAidSetup_D2_Rq 15 "NotUsed_9" 14 "NotUsed_8" 13 "NotUsed_7" 12 "NotUsed_6" 11 "NotUsed_5" 10 "NotUsed_4" 9 "NotUsed_3" 8 "NotUsed_2" 7 "NotUsed_1" 6 "CompleteSetup" 5 "ReturnToSetup" 4 "StickerNotCircled" 3 "ConfirmSetup" 2 "EndSetup" 1 "BeginSetup" 0 "Inactive" ;
VAL_ 1116 TrlrAidEnbl_D2_Rq 7 "NotUsed_4" 6 "NotUsed_3" 5 "NotUsed_2" 4 "NotUsed_1" 3 "Deactivate" 2 "ActivateTrg" 1 "ActivateTba" 0 "Inactive" ;
VAL_ 1116 TlightTest_D_Mnu 3 "TestEndAcknowledge" 2 "StartTest" 1 "StopTest" 0 "Null" ;
VAL_ 1116 TrlrRvrseCancl_B_Rq 1 "Cancel" 0 "Null" ;
VAL_ 1116 TrlrIdType_D_Stat 3 "Gooseneck" 2 "FifthWheel" 1 "Conventional" 0 "Null" ;
VAL_ 1116 TrlrAnOffstDir_D_Mem 3 "NotUSed" 2 "Right" 1 "Left_or_Center" 0 "Null" ;
VAL_ 1113 TrlrAnOffstDir_D_Calc_UB 1 "Fresh_data" 0 "Unchanged_data" ;
VAL_ 1113 TrlrAnOffst_An_Calc_UB 1 "Fresh_data" 0 "Unchanged_data" ;
VAL_ 1113 TrlrAnCalib_B_Complt_UB 1 "Fresh_data" 0 "Unchanged_data" ;
VAL_ 1113 TrlrAidTrgtId_No_Actl_UB 1 "Fresh_data" 0 "Unchanged_data" ;
VAL_ 1113 TrlrAnCalib_B_Complt 1 "Yes" 0 "No" ;
VAL_ 1113 TrlrAnOffstDir_D_Calc 3 "NotUSed" 2 "Right" 1 "Left_or_Center" 0 "Null" ;
VAL_ 1113 immoSecureIdleMode_UB 1 "Fresh_data" 0 "Unchanged_data" ;
VAL_ 1113 immoSecureIdleMode 3 "NotUsed2" 2 "NotUsed1" 1 "Active" 0 "Inactive" ;
VAL_ 1255 BalrRight4Threat_D_Stat 1 "Yes" 0 "No" ;
VAL_ 1255 BalrRight4Fast_B_Stat 1 "Yes" 0 "No" ;
VAL_ 1255 BalrRight4Dsply_B_Stat 1 "Yes" 0 "No" ;
VAL_ 1254 BalrRight3Threat_D_Stat 1 "Yes" 0 "No" ;
VAL_ 1254 BalrRight3Fast_B_Stat 1 "Yes" 0 "No" ;
VAL_ 1254 BalrRight3Dsply_B_Stat 1 "Yes" 0 "No" ;
VAL_ 1253 BalrRight2Threat_D_Stat 1 "Yes" 0 "No" ;
VAL_ 1253 BalrRight2Fast_B_Stat 1 "Yes" 0 "No" ;
VAL_ 1253 BalrRight2Dsply_B_Stat 1 "Yes" 0 "No" ;
VAL_ 1252 BalrRight1Threat_D_Stat 1 "Yes" 0 "No" ;
VAL_ 1252 BalrRight1Fast_B_Stat 1 "Yes" 0 "No" ;
VAL_ 1252 BalrRight1Dsply_B_Stat 1 "Yes" 0 "No" ;
VAL_ 1251 BalrLeft4Threat_D_Stat 1 "Yes" 0 "No" ;
VAL_ 1251 BalrLeft4Fast_B_Stat 1 "Yes" 0 "No" ;
VAL_ 1251 BalrLeft4Dsply_B_Stat 1 "Yes" 0 "No" ;
VAL_ 1250 BalrLeft3Threat_D_Stat 1 "Yes" 0 "No" ;
VAL_ 1250 BalrLeft3Fast_B_Stat 1 "Yes" 0 "No" ;
VAL_ 1250 BalrLeft3Dsply_B_Stat 1 "Yes" 0 "No" ;
VAL_ 1249 BalrLeft2Threat_D_Stat 1 "Yes" 0 "No" ;
VAL_ 1249 BalrLeft2Fast_B_Stat 1 "Yes" 0 "No" ;
VAL_ 1249 BalrLeft2Dsply_B_Stat 1 "Yes" 0 "No" ;
VAL_ 1248 BalrLeft1Threat_D_Stat 1 "Yes" 0 "No" ;
VAL_ 1248 BalrLeft1Fast_B_Stat 1 "Yes" 0 "No" ;
VAL_ 1248 BalrLeft1Dsply_B_Stat 1 "Yes" 0 "No" ;
VAL_ 1256 BalrMdeRight_D_Stat_UB 1 "Fresh_data" 0 "Unchanged_data" ;
VAL_ 1256 BalrMdeSelRight_B_Stat_UB 1 "Fresh_data" 0 "Unchanged_data" ;
VAL_ 1256 BalrRight_D_Stat_UB 1 "Fresh_data" 0 "Unchanged_data" ;
VAL_ 1256 BalrLckRight_B_Stat_UB 1 "Fresh_data" 0 "Unchanged_data" ;
VAL_ 1256 BalrChimeRight_D_Rq_UB 1 "Fresh_data" 0 "Unchanged_data" ;
VAL_ 1256 BalrSnsRight_D_Falt_UB 1 "Fresh_data" 0 "Unchanged_data" ;
VAL_ 1256 BalrWndwRight_B_Stat_UB 1 "Fresh_data" 0 "Unchanged_data" ;
VAL_ 1256 BalrLckRight_B_Stat 1 "Enable" 0 "Disable" ;
VAL_ 1256 BalrWndwRight_B_Stat 1 "Enable" 0 "Disable" ;
VAL_ 1256 BalrMdeSelRight_B_Stat 1 "Enable" 0 "Disable" ;
VAL_ 1256 BalrSnsRight_D_Falt 3 "Invalid" 2 "SystemFailure" 1 "Blocked" 0 "Clear" ;
VAL_ 1256 BalrChimeRight_D_Rq 3 "NotUsed" 2 "Soft" 1 "Normal" 0 "Off" ;
VAL_ 1256 BalrMdeRight_D_Stat 3 "NotUsed" 2 "High" 1 "Medium" 0 "Low" ;
VAL_ 1256 BalrRight_D_Stat 3 "Inhibited" 2 "Disabled" 1 "On" 0 "Off" ;
VAL_ 1256 BalrWndwLeft_B_Stat_UB 1 "Fresh_data" 0 "Unchanged_data" ;
VAL_ 1256 BalrSnsLeft_D_Falt_UB 1 "Fresh_data" 0 "Unchanged_data" ;
VAL_ 1256 BalrMdeSelLeft_B_Stat_UB 1 "Fresh_data" 0 "Unchanged_data" ;
VAL_ 1256 BalrMdeLeft_D_Stat_UB 1 "Fresh_data" 0 "Unchanged_data" ;
VAL_ 1256 BalrLeft_D_Stat_UB 1 "Fresh_data" 0 "Unchanged_data" ;
VAL_ 1256 BalrLckLeft_B_Stat_UB 1 "Fresh_data" 0 "Unchanged_data" ;
VAL_ 1256 BalrChimeLeft_D_Rq_UB 1 "Fresh_data" 0 "Unchanged_data" ;
VAL_ 1256 BalrLeft_D_Stat 3 "Inhibited" 2 "Disabled" 1 "On" 0 "Off" ;
VAL_ 1256 BalrMdeSelLeft_B_Stat 1 "Enable" 0 "Disable" ;
VAL_ 1256 BalrLckLeft_B_Stat 1 "Enable" 0 "Disable" ;
VAL_ 1256 BalrWndwLeft_B_Stat 1 "Enable" 0 "Disable" ;
VAL_ 1256 BalrMdeLeft_D_Stat 3 "NotUsed" 2 "High" 1 "Medium" 0 "Low" ;
VAL_ 1256 BalrSnsLeft_D_Falt 3 "Invalid" 2 "SystemFailure" 1 "Blocked" 0 "Clear" ;
VAL_ 1256 BalrChimeLeft_D_Rq 3 "NotUsed" 2 "Soft" 1 "Normal" 0 "Off" ;
VAL_ 1256 WakeAlarm2_D_Stat_UB 1 "Fresh_data" 0 "Unchanged_data" ;
VAL_ 1256 WakeAlarm2_D_Stat 3 "PublisherReset" 2 "Wake" 1 "AlarmRunning" 0 "AlarmOff" ;
VAL_ 529 OnbChrgToPcWknd_D_Actl 7 "Percent_50" 6 "Percent_60" 5 "Percent_70" 4 "Percent_80" 3 "Percent_85" 2 "Percent_90" 1 "Percent_95" 0 "Percent_100" ;
VAL_ 529 OnbChrgToPcWkdy_D_Actl 7 "Percent_50" 6 "Percent_60" 5 "Percent_70" 4 "Percent_80" 3 "Percent_85" 2 "Percent_90" 1 "Percent_95" 0 "Percent_100" ;
VAL_ 529 OnbChrgSetNow_D_Rq 3 "NotUsed" 2 "On" 1 "Off" 0 "Null" ;
VAL_ 529 OnbChrgSetDelete_B_Rq 1 "Request" 0 "NoRequest" ;
VAL_ 529 OnbChrgPrflUpdate_B_Rq 1 "Request" 0 "NoRequest" ;
VAL_ 529 OnbChrgLocIdUns_B_Rq 1 "Request" 0 "NoRequest" ;
VAL_ 642 SldrrMsgTxt_D2_Rq_UB 1 "Fresh_data" 0 "Unchanged_data" ;
VAL_ 642 SldrrMsgTxt_D2_Rq 7 "NotUsed_3" 6 "NotUsed_2" 5 "NotUsed_1" 4 "SlidingDrCalibNeeded2" 3 "SlidingDrOpenCltchReleased" 2 "SlidingDrCalibNeeded" 1 "SlidingDrClutchReleased" 0 "Null" ;
VAL_ 642 SldrrChime_D_Rq_UB 1 "Fresh_data" 0 "Unchanged_data" ;
VAL_ 642 SldrrChime_D_Rq 7 "NotUsed3" 6 "NotUsed2" 5 "NotUsed1" 4 "Warning" 3 "WarningRepeated" 2 "Programming" 1 "Operation" 0 "Off" ;
VAL_ 642 SldrlMsgTxt_D2_Rq_UB 1 "Fresh_data" 0 "Unchanged_data" ;
VAL_ 642 SldrlMsgTxt_D2_Rq 7 "NotUsed_3" 6 "NotUsed_2" 5 "NotUsed_1" 4 "SlidingDrCalibNeeded2" 3 "SlidingDrOpenCltchReleased" 2 "SlidingDrCalibNeeded" 1 "SlidingDrClutchReleased" 0 "Null" ;
VAL_ 642 SldrlChime_D_Rq_UB 1 "Fresh_data" 0 "Unchanged_data" ;
VAL_ 642 SldrlChime_D_Rq 7 "NotUsed3" 6 "NotUsed2" 5 "NotUsed1" 4 "Warning" 3 "WarningRepeated" 2 "Programming" 1 "Operation" 0 "Off" ;
VAL_ 642 PaakMyKeySearch_D_Stat_UB 1 "Fresh_data" 0 "Unchanged_data" ;
VAL_ 642 UreaLvlQlty_D_RqDsply_UB 1 "Fresh_data" 0 "Unchanged_data" ;
VAL_ 642 DieslPrtcWarn_D_Rq_UB 1 "Fresh_data" 0 "Unchanged_data" ;
VAL_ 642 UreaQltySysWarn_D_Rq_UB 1 "Fresh_data" 0 "Unchanged_data" ;
VAL_ 642 UreaLvlTxtWarn_D_Rq_UB 1 "Fresh_data" 0 "Unchanged_data" ;
VAL_ 642 UreaLvlQlty_D_RqDsply 7 "NotUsed_5" 6 "NotUsed_4" 5 "NotUsed_3" 4 "NotUsed_2" 3 "NotUsed_1" 2 "FlashChime" 1 "On" 0 "Off" ;
VAL_ 642 UreaLvlTxtWarn_D_Rq 15 "NotUsed_4" 14 "NotUsed_3" 13 "NotUsed_2" 12 "NotUsed_1" 11 "System_Error" 10 "Engine_Idled_See_Manual" 9 "Engine_Idled_Upon_Refuel" 8 "Speed_Limited_To_XX_mph" 7 "XXmph_Max_Upon_Restart" 6 "Speed_Limited_To_YY_mph" 5 "YYmph_Max_Upon_Restart" 4 "SpdLimtd_YYmph_In_XXmiles" 3 "ExFlRange_XXMiles_ScndWarn" 2 "Exh_Fluid_Range_XX_Miles" 1 "Exh_Fluid_Under_Half_Full" 0 "Exh_Fluid_Over_Half_Full" ;
VAL_ 642 UreaQltySysWarn_D_Rq 7 "Undefined" 6 "ZZ_Overrides" 5 "EngineIdled" 4 "Engine_Idle_Upon_Refuel" 3 "SPEED_LIMITED_to_YY_mph" 2 "YY_MPH_MAX_UPON_Restart" 1 "CONTAMINATED_ExhFluid" 0 "NoQualityProblem" ;
VAL_ 642 DieslPrtcWarn_D_Rq 15 "NotUsed_4" 14 "NotUsed_3" 13 "NotUsed_2" 12 "NotUsed_1" 11 "OCR_ExhFilterClean_Stopped" 10 "OCR_ExhFilterCleaned" 9 "RgnOff_AtLimit" 8 "RgnOff_OverLoaded" 7 "RgnOff_Loaded" 6 "Exhaust_Filter_Full" 5 "DPF_OverLimit" 4 "DPF_AtLimit" 3 "ExhFilter_Drive_Completed" 2 "Cleaning_Exhaust_Filter" 1 "DPF_OverLoaded" 0 "DPF_Normal_Operation" ;
VAL_ 642 KeyMyKeyTot_No2_Cnt_UB 1 "Fresh_data" 0 "Unchanged_data" ;
VAL_ 642 KeyAdmnTot_No2_Cnt_UB 1 "Fresh_data" 0 "Unchanged_data" ;
VAL_ 642 DcChrgSrvcRqd_B_Rq_UB 1 "Fresh_data" 0 "Unchanged_data" ;
VAL_ 642 DcChrgSrvcRqd_B_Rq 1 "On" 0 "Off" ;
VAL_ 642 PaakMyKeySearch_D_Stat 7 "PhoneErased" 6 "LockButtonTimeOut" 5 "PressLockButton" 4 "ConfirmHmi" 3 "MyKeyPaakFound" 2 "StandardPaakFound" 1 "NoValidPaakFound" 0 "Null" ;
VAL_ 642 GrdAsstActv_B_Stat_UB 1 "Fresh_data" 0 "Unchanged_data" ;
VAL_ 642 GrdAsstActv_B_Stat 1 "On" 0 "Off" ;
VAL_ 642 TrlrAidTrlrId_No_Rq_UB 1 "Fresh_data" 0 "Unchanged_data" ;
VAL_ 893 RngPerChrgAvg_L2_Dsply_UB 1 "Fresh_data" 0 "Unchanged_data" ;
VAL_ 893 RngImpctClim_L_Dsply_UB 1 "Fresh_data" 0 "Unchanged_data" ;
VAL_ 893 RngImpctDrv_L_Dsply_UB 1 "Fresh_data" 0 "Unchanged_data" ;
VAL_ 893 VehElEffAvg_No_Dsply_UB 1 "Fresh_data" 0 "Unchanged_data" ;
VAL_ 893 VehElEffAvg_No_Dsply 127 "Faulty" 126 "NoDataExists" ;
VAL_ 893 RngPerChrgAvg_L2_Dsply 8191 "Faulty" 8190 "NoDataExists" ;
VAL_ 893 TrnAout2_W_ActlUnfilt_UB 1 "Fresh_data" 0 "Unchanged_data" ;
VAL_ 893 TrnAout2_W_ActlUnfilt 65535 "Fault" 65534 "NoDataExists" ;
VAL_ 500 Dsp_GetCDTOCDData_Rq 0 "Inactive" 2 "Off" 1 "TOC" ;
VAL_ 500 Dsp_CutItem_Rq 3 "Inactive" 2 "ThreeQuarterFromTheBeginningOneQ" 1 "End" 0 "Beginning" ;
VAL_ 500 Dsp_AudioSourceSel_Rq 5 "SDCard" 4 "Reserved" 3 "USB" 2 "BTAudio" 1 "CD" 0 "Inactive" ;
VAL_ 503 Dsp_AudioSourceSel3_Rq 3 "USB" 2 "BTAudio" 1 "CD" 0 "Inactive" ;
VAL_ 493 Dsp_StatLiScanCancel_Rq 1 "Cancel" 0 "Inactive" ;
VAL_ 493 Dsp_StationList_Rq 15 "reserved_last" 8 "reserved" 7 "DAB_Service_List" 6 "DAB_Ensemble_Service_List" 5 "Analog_FM_PTY_List" 4 "Analog_and_HD_FM_List" 3 "HD_FM_List" 2 "Analog_FM_List" 1 "Analog_AM_List" 0 "Inactive" ;
VAL_ 493 Dsp_RefreshFlag 1 "True" 0 "False" ;
VAL_ 493 Dsp_AFJump_Rq 2 "Enable" 1 "Inhibit" 0 "Inactive" ;
VAL_ 511 SdarsAudioRtng_D_Rq 3 "NotUsed" 2 "APIMStereoOut" 1 "X40l2SStereoOut" 0 "Null" ;
VAL_ 511 Dsp_TUPresetArea_Rq 13 "reserved" 12 "GetSAT3PresetData" 11 "GetSAT2PresetData" 15 "reserved_last" 10 "GetSAT1PresetData" 9 "GetDAB2PresetData" 8 "GetDAB1PresetData" 7 "GetDAB3PresetData" 6 "GetAmPresetData" 5 "GetAmAstPresetData" 4 "GetFmAstPresetData" 3 "GetFm3PresetData" 2 "GetFm2PresetData" 1 "GetFm1PresetData" 0 "Inactive" ;
VAL_ 511 Dsp_SetCurrTUBand_Rq 13 "reserved1" 12 "DAB3" 11 "SAT3" 10 "SAT2" 15 "reserved_last" 9 "SAT1" 8 "DAB2" 7 "DAB1" 6 "AmAst" 5 "Am" 4 "FmAst" 3 "Fm3" 2 "Fm2" 1 "Fm1" 0 "Inactive" ;
VAL_ 257 MFD_SetTagMode 2 "On" 1 "Off" 0 "Inactive" ;
VAL_ 257 MFD_SetRBDSMode 2 "On" 1 "Off" 0 "Inactive" ;
VAL_ 257 MFD_SetHDModeRq 2 "On" 1 "Off" 0 "Inactive" ;
VAL_ 257 MFD_GetTagInfo 1 "TagInformation" 0 "Inactive" ;
VAL_ 382 EngMnfldChrg_Te_Actl 127 "Faulty" 126 "NoDataExists" ;
VAL_ 382 EngInnrClnt_Te_Actl 127 "Faulty" 126 "NoDataExists" ;
VAL_ 382 DcacOut2_Pw2_Dsply 8191 "Faulty" 8190 "NoDataExists" ;
VAL_ 382 DcacOut1_Pw2_Dsply 8191 "Faulty" 8190 "NoDataExists" ;
VAL_ 877 CabnAmb_Te_ActlAft 255 "Faulty" ;
VAL_ 877 RstrtClimtSet_B_Actv 1 "Active" 0 "Inactive" ;
VAL_ 877 Rr_Third_Power_Btn_Stt 3 "Unused" 2 "Disabled" 1 "Active" 0 "Enabled_Inactive" ;
VAL_ 877 Rr_Third_Floor_Btn_Stt 3 "Unused" 2 "Disabled" 1 "Active" 0 "Enabled_Inactive" ;
VAL_ 877 Rr_Third_Auto_Btn_Stt 3 "Unused" 2 "Disabled" 1 "Active" 0 "Enabled_Inactive" ;
VAL_ 877 Rr_Lock_Btn_Stt 3 "Unused" 2 "Disabled" 1 "Active" 0 "Enabled_Inactive" ;
VAL_ 877 Rr_RHS_Blower_Indicate 15 "Display_Blank" 14 "14_Indicators_On" 13 "13_Indicators_On" 12 "12_Indicators_On" 11 "11_Indicators_On" 10 "10_Indicators_On" 9 "9_Indicators_On" 8 "8_Indicators_On" 7 "7_Indicators_On" 6 "6_Indicators_On" 5 "5_Indicators_On" 4 "4_Indicators_On" 3 "3_Indicators_On" 2 "2_Indicators_On" 1 "1_Indicator_On" 0 "Indicators_Off" ;
VAL_ 877 Rr_Third_Panel_Btn_Stt 3 "Unused" 2 "Disabled" 1 "Active" 0 "Enabled_Inactive" ;
VAL_ 877 Rr_Synch_Btn_Stt 3 "Unused" 2 "Disabled" 1 "Active" 0 "Enabled_Inactive" ;
VAL_ 877 AAR_Btn_Stt 3 "Unused" 2 "Disabled" 1 "Active" 0 "Enabled_Inactive" ;
VAL_ 877 Heat_Btn_Stt 3 "Unused" 2 "Disabled" 1 "Active" 0 "Enabled_Inactive" ;
VAL_ 414 LBS2_ListStatus 0 "Inactive" 1 "Valid" 2 "Updating" 3 "Reserved" ;
VAL_ 1239 StabBarCnnctLamp_D_Cstm 3 "Fast_Flash" 2 "Slow_Flash" 1 "On" 0 "Off" ;
VAL_ 1239 SelDrvMdeCstmLamp_D_Rq 3 "NotUsed2" 2 "NotUsed1" 1 "On" 0 "Off" ;
VAL_ 1239 SelDrvMdeCstm_D_RqDrv 7 "Faulty" 6 "NotUsed_3" 5 "NotUsed_2" 4 "NotUsed_1" 3 "Recall" 2 "Save" 1 "Activate" 0 "Null" ;
VAL_ 1239 CstmDrvMdeMsgTxt_D_Rq 15 "Message15" 14 "Message14" 13 "Message13" 12 "Message12" 11 "Message11" 10 "Message10" 9 "Message9" 8 "Message8" 7 "Message7" 6 "Message6" 5 "Message5" 4 "Message4" 3 "Message3" 2 "Message2" 1 "Message1" 0 "NoMessage" ;
VAL_ 1239 ActvDrvMdeCstm_D2_Rq 31 "Faulty" 30 "SelDrvMde31" 29 "SelDrvMde30" 28 "SelDrvMde29" 27 "SelDrvMde28" 26 "SelDrvMde27" 25 "SelDrvMde26" 24 "SelDrvMde25" 23 "SelDrvMde24" 22 "SelDrvMde23" 21 "SelDrvMde22" 20 "SelDrvMde21" 19 "SelDrvMde20" 18 "SelDrvMde19" 17 "SelDrvMde18" 16 "SelDrvMde17" 15 "SelDrvMde16" 14 "SelDrvMde15" 13 "SelDrvMde14" 12 "SelDrvMde13" 11 "SelDrvMde12" 10 "SelDrvMde11" 9 "SelDrvMde10" 8 "SelDrvMde09" 7 "SelDrvMde08" 6 "SelDrvMde07" 5 "SelDrvMde06" 4 "SelDrvMde05" 3 "SelDrvMde04" 2 "SelDrvMde03" 1 "SelDrvMde02" 0 "SelDrvMde01" ;
VAL_ 1239 SeatOccRearChime_B_Rq 1 "On" 0 "Off" ;
VAL_ 1013 ChrgToPcWkndSav_D_Stat 7 "Percent_50" 6 "Percent_60" 5 "Percent_70" 4 "Percent_80" 3 "Percent_85" 2 "Percent_90" 1 "Percent_95" 0 "Percent_100" ;
VAL_ 1013 ChrgToPcWkdySav_D_Stat 7 "Percent_50" 6 "Percent_60" 5 "Percent_70" 4 "Percent_80" 3 "Percent_85" 2 "Percent_90" 1 "Percent_95" 0 "Percent_100" ;
VAL_ 1013 ChrgNowEnbl_B_Saved 1 "On" 0 "Off" ;
VAL_ 1013 ChrgLocIdUnsAck_B_Stat 1 "Yes" 0 "No" ;
VAL_ 641 ChrgGoTElement_B_Dsply_UB 1 "Fresh_data" 0 "Unchanged_data" ;
VAL_ 641 ChrgGoTElement_B_Dsply 1 "Yes" 0 "No" ;
VAL_ 641 BattChrgTrgtSoC_D_Rq 7 "Percent_50" 6 "Percent_60" 5 "Percent_70" 4 "Percent_80" 3 "Percent_85" 2 "Percent_90" 1 "Percent_95" 0 "Percent_100" ;
VAL_ 641 BattChrgTrgtSoC_D_Rq_UB 1 "Fresh_data" 0 "Unchanged_data" ;
VAL_ 641 ChrgLocIdCurnt_D_Uns_UB 1 "Fresh_data" 0 "Unchanged_data" ;
VAL_ 641 IgnPsswrdActv_B_Stat_UB 1 "Fresh_data" 0 "Unchanged_data" ;
VAL_ 641 IgnPsswrdSetup_B_Rq_UB 1 "Fresh_data" 0 "Unchanged_data" ;
VAL_ 641 IgnPsswrdLckout_B_Stat_UB 1 "Fresh_data" 0 "Unchanged_data" ;
VAL_ 641 IgnPsswrdSetup_B_Rq 1 "Active" 0 "Inactive" ;
VAL_ 641 IgnPsswrdLckout_B_Stat 1 "Active" 0 "Inactive" ;
VAL_ 641 PaakCnnct_D_Stat_UB 1 "Fresh_data" 0 "Unchanged_data" ;
VAL_ 641 PaakCnnct_D_Stat 3 "NotUsed" 2 "Connected" 1 "NotConnected" 0 "Null" ;
VAL_ 641 IgnPsswrdActv_B_Stat 1 "Active" 0 "Inactive" ;
VAL_ 641 ChrgGoTTouch_B_Stat_UB 1 "Fresh_data" 0 "Unchanged_data" ;
VAL_ 641 ChrgGoTTouch_B_Stat 1 "On" 0 "Off" ;
VAL_ 641 ChrgGoTPrcond_D_Stat_UB 1 "Fresh_data" 0 "Unchanged_data" ;
VAL_ 641 ChrgGoTPrcond_D_Stat 3 "High" 2 "Medium" 1 "Low" 0 "Off" ;
VAL_ 641 ChrgGoTNext_D_Stat_UB 1 "Fresh_data" 0 "Unchanged_data" ;
VAL_ 641 ChrgGoTMnte_D_Stat_UB 1 "Fresh_data" 0 "Unchanged_data" ;
VAL_ 641 ChrgGoTMnte_D_Stat 15 "NotUsed_4" 14 "NotUsed_3" 13 "NotUsed_2" 12 "NotUsed_1" 11 "Minute_55" 10 "Minute_50" 9 "Minute_45" 8 "Minute_40" 7 "Minute_35" 6 "Minute_30" 5 "Minute_25" 4 "Minute_20" 3 "Minute_15" 2 "Minute_10" 1 "Minute_5" 0 "Minute_0" ;
VAL_ 641 ChrgGoTHr_T_Stat_UB 1 "Fresh_data" 0 "Unchanged_data" ;
VAL_ 641 ChrgGoTHr_T_Stat 31 "Faulty" 30 "NoDataExists" ;
VAL_ 641 ChrgGoTExtHtr_B_Stat_UB 1 "Fresh_data" 0 "Unchanged_data" ;
VAL_ 641 ChrgGoTExtHtr_B_Stat 1 "On" 0 "Off" ;
VAL_ 641 ChrgGoTElement_D_Stat_UB 1 "Fresh_data" 0 "Unchanged_data" ;
VAL_ 641 ChrgGoTAllOn_B_Stat_UB 1 "Fresh_data" 0 "Unchanged_data" ;
VAL_ 641 ChrgGoTAllOn_B_Stat 1 "On" 0 "Off" ;
VAL_ 641 TrlrAidMsgTxt_D2_Rq 63 "Message63" 62 "Message62" 61 "Message61" 60 "Message60" 55 "Message55" 50 "Message50" 45 "Message45" 40 "Message40" 35 "Message35" 31 "Message31" 30 "Message30" 29 "Message29" 28 "Message28" 27 "Message27" 26 "Message26" 25 "Message25" 24 "Message24" 23 "Message23" 22 "Message22" 21 "Message21" 20 "Message20" 19 "Message19" 18 "Message18" 17 "Message17" 16 "Message16" 15 "Message15" 14 "Message14" 13 "Message13" 12 "Message12" 11 "Message11" 10 "Message10" 9 "Message9" 8 "Message8" 7 "Message7" 6 "Message6" 5 "Message5" 4 "Message4" 3 "Message3" 2 "Message2" 1 "Message1" 0 "NoMessage" ;
VAL_ 641 TrlrAidEnbl_D2_Stat 7 "NotUsed_1" 6 "TbaActiveExpertActive" 5 "TbaActiveExpertAvail" 4 "TbaOffTrgActive" 3 "TbaOffTrgSetup" 2 "TbaSetup" 1 "TbaActive" 0 "Inactive" ;
VAL_ 641 TrlrAidMsgTxt_D2_Rq_UB 1 "Fresh_data" 0 "Unchanged_data" ;
VAL_ 641 TrlrAidEnbl_D2_Stat_UB 1 "Fresh_data" 0 "Unchanged_data" ;
